VERSION ""

NS_ :

BS_:

BU_: CGM_HS TCM_HS RDCM_HS EPS_HS ECM_HS EBCM_HS BSM_HS BCM_HS

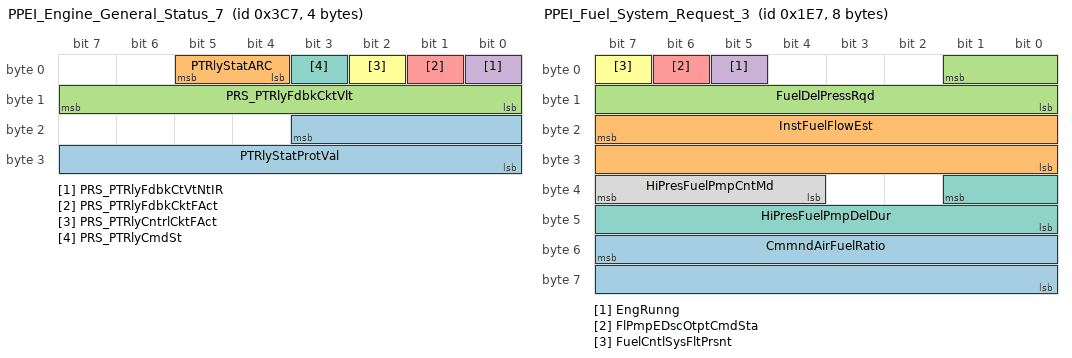
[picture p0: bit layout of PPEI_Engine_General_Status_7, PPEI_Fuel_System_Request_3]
BO_ 967 PPEI_Engine_General_Status_7: 4 ECM_HS
 SG_ PTRlyStatProtVal : 19|12@0+ (1,0) [0|4095] ""  CGM_HS
 SG_ PTRlyStatARC : 5|2@0+ (1,0) [0|3] ""  CGM_HS
 SG_ PRS_PTRlyFdbkCktVlt : 15|8@0+ (0.1,0) [0|25.5] "V"  CGM_HS
 SG_ PRS_PTRlyFdbkCtVtNtIR : 0|1@0+ (1,0) [0|1] ""  CGM_HS
 SG_ PRS_PTRlyFdbkCktFAct : 1|1@0+ (1,0) [0|1] ""  CGM_HS
 SG_ PRS_PTRlyCntrlCktFAct : 2|1@0+ (1,0) [0|1] ""  CGM_HS
 SG_ PRS_PTRlyCmdSt : 3|1@0+ (1,0) [0|1] ""  CGM_HS

BO_ 487 PPEI_Fuel_System_Request_3: 8 ECM_HS
 SG_ CmmndAirFuelRatio : 55|16@0+ (0.000488281,0) [0|31.999495335] ""  CGM_HS
 SG_ InstFuelFlowEst : 23|16@0+ (0.000976562,0) [0|63.99899067] "grams/s"  CGM_HS
 SG_ FuelDelPressRqd : 1|10@0+ (1,0) [0|1023] "kPa"  CGM_HS
 SG_ EngRunng : 5|1@0+ (1,0) [0|1] "" Vector__XXX
 SG_ FlPmpEDscOtptCmdSta : 6|1@0+ (1,0) [0|1] ""  CGM_HS
 SG_ FuelCntlSysFltPrsnt : 7|1@0+ (1,0) [0|1] ""  CGM_HS
 SG_ HiPresFuelPmpDelDur : 33|10@0+ (1,0) [0|1023] "deg"  CGM_HS
 SG_ HiPresFuelPmpCntMd : 39|4@0+ (1,0) [0|15] ""  CGM_HS

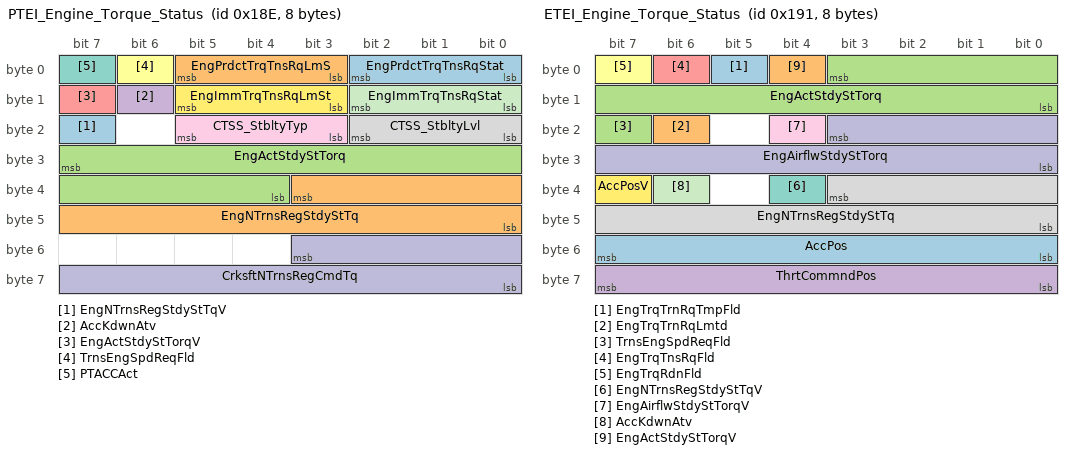
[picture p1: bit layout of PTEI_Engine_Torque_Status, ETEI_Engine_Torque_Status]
BO_ 398 PTEI_Engine_Torque_Status: 8 ECM_HS
 SG_ EngNTrnsRegStdyStTqV : 23|1@0+ (1,0) [0|1] ""  CGM_HS,TCM_HS
 SG_ EngNTrnsRegStdyStTq : 35|12@0+ (0.5,-848) [-848|1199.5] "Nm"  CGM_HS,TCM_HS
 SG_ EngActStdyStTorq : 31|12@0+ (0.5,-848) [-848|1199.5] "Nm"  CGM_HS,TCM_HS
 SG_ AccKdwnAtv : 14|1@0+ (1,0) [0|1] ""  CGM_HS,TCM_HS
 SG_ EngActStdyStTorqV : 15|1@0+ (1,0) [0|1] ""  CGM_HS,TCM_HS
 SG_ TrnsEngSpdReqFld : 6|1@0+ (1,0) [0|1] ""  CGM_HS,TCM_HS
 SG_ PTACCAct : 7|1@0+ (1,0) [0|1] ""  CGM_HS,TCM_HS
 SG_ CTSS_StbltyLvl : 18|3@0+ (1,0) [0|7] ""  CGM_HS,TCM_HS
 SG_ CTSS_StbltyTyp : 21|3@0+ (1,0) [0|7] ""  CGM_HS,TCM_HS
 SG_ CrksftNTrnsRegCmdTq : 51|12@0+ (0.5,-848) [-848|1199.5] "Nm"  CGM_HS,TCM_HS
 SG_ EngImmTrqTnsRqStat : 10|3@0+ (1,0) [0|7] ""  CGM_HS,TCM_HS
 SG_ EngImmTrqTnsRqLmSt : 13|3@0+ (1,0) [0|7] ""  CGM_HS,TCM_HS
 SG_ EngPrdctTrqTnsRqStat : 2|3@0+ (1,0) [0|7] ""  CGM_HS,TCM_HS
 SG_ EngPrdctTrqTnsRqLmS : 5|3@0+ (1,0) [0|7] ""  CGM_HS,TCM_HS

BO_ 1267 PPEI_Powertrain_Config_Data_2: 1 ECM_HS
 SG_ VehMassNom : 7|8@0+ (20,500) [500|5600] "kg"  CGM_HS

BO_ 1906 DTC_Triggered_772: 7 ECM_HS
 SG_ DTCI_DTCFaultType_772 : 55|8@0+ (1,0) [0|255] ""  CGM_HS
 SG_ DTCI_CodeSupported_772 : 40|1@0+ (1,0) [0|1] ""  CGM_HS
 SG_ DTCI_CurrentStatus_772 : 41|1@0+ (1,0) [0|1] ""  CGM_HS
 SG_ DTCI_TstNPsdCdClrdSt_772 : 42|1@0+ (1,0) [0|1] ""  CGM_HS
 SG_ DTCI_TstFldCdClrdStat_772 : 43|1@0+ (1,0) [0|1] ""  CGM_HS
 SG_ DTCI_HistStat_772 : 44|1@0+ (1,0) [0|1] ""  CGM_HS
 SG_ DTCI_TstNPsdPwrUpSt_772 : 45|1@0+ (1,0) [0|1] ""  CGM_HS
 SG_ DTCI_TstFldPwrUpSt_772 : 46|1@0+ (1,0) [0|1] ""  CGM_HS
 SG_ DTCI_WrnIndRqdSt_772 : 47|1@0+ (1,0) [0|1] ""  CGM_HS
 SG_ DTCI_DTCFailType_772 : 39|8@0+ (1,0) [0|255] ""  CGM_HS
 SG_ DTCI_DTCNumber_772 : 23|16@0+ (1,0) [0|65535] ""  CGM_HS
 SG_ DTCI_DTCSource_772 : 15|8@0+ (1,0) [0|255] ""  CGM_HS
 SG_ DTCI_DTCTriggered_772 : 0|1@0+ (1,0) [0|1] ""  CGM_HS
 SG_ DTCIUnused7_772 : 1|1@0+ (1,0) [0|1] ""  CGM_HS
 SG_ DTCIUnused6_772 : 2|1@0+ (1,0) [0|1] ""  CGM_HS
 SG_ DTCIUnused5_772 : 3|1@0+ (1,0) [0|1] ""  CGM_HS
 SG_ DTCIUnused4_772 : 4|1@0+ (1,0) [0|1] ""  CGM_HS
 SG_ DTCIUnused3_772 : 5|1@0+ (1,0) [0|1] ""  CGM_HS
 SG_ DTCIUnused2_772 : 6|1@0+ (1,0) [0|1] ""  CGM_HS
 SG_ DTCIUnused1_772 : 7|1@0+ (1,0) [0|1] ""  CGM_HS

BO_ 401 ETEI_Engine_Torque_Status: 8 ECM_HS
 SG_ EngTrqTrnRqTmpFld : 5|1@0+ (1,0) [0|1] ""  CGM_HS,TCM_HS
 SG_ EngTrqTrnRqLmtd : 22|1@0+ (1,0) [0|1] ""  CGM_HS,TCM_HS
 SG_ TrnsEngSpdReqFld : 23|1@0+ (1,0) [0|1] ""  CGM_HS,TCM_HS
 SG_ ThrtCommndPos : 63|8@0+ (0.392157,0) [0|100.000035] "%"  CGM_HS
 SG_ EngTrqTnsRqFld : 6|1@0+ (1,0) [0|1] ""  CGM_HS,TCM_HS
 SG_ EngTrqRdnFld : 7|1@0+ (1,0) [0|1] ""  CGM_HS,TCM_HS
 SG_ EngNTrnsRegStdyStTqV : 36|1@0+ (1,0) [0|1] ""  CGM_HS,TCM_HS
 SG_ EngNTrnsRegStdyStTq : 35|12@0+ (0.5,-848) [-848|1199.5] "Nm"  CGM_HS,TCM_HS
 SG_ EngAirflwStdyStTorqV : 20|1@0+ (1,0) [0|1] ""  CGM_HS,TCM_HS
 SG_ EngAirflwStdyStTorq : 19|12@0+ (0.5,-848) [-848|1199.5] "Nm"  CGM_HS,TCM_HS
 SG_ AccKdwnAtv : 38|1@0+ (1,0) [0|1] ""  CGM_HS,TCM_HS
 SG_ AccPosV : 39|1@0+ (1,0) [0|1] ""  CGM_HS,TCM_HS
 SG_ AccPos : 55|8@0+ (0.392157,0) [0|100.000035] "%"  TCM_HS
 SG_ EngActStdyStTorqV : 4|1@0+ (1,0) [0|1] ""  CGM_HS,TCM_HS
 SG_ EngActStdyStTorq : 3|12@0+ (0.5,-848) [-848|1199.5] "Nm"  CGM_HS,TCM_HS

BO_ 2024 USDT_Resp_From_ECM_HS: 8 ECM_HS
 SG_ DgnInf : 7|64@0+ (1,0) [0|1.84467440737096E+019] ""  CGM_HS

BO_ 1512 UUDT_Resp_From_ECM: 8 ECM_HS
 SG_ DgnInf : 7|64@0+ (1,0) [0|1.84467440737096E+019] ""  CGM_HS

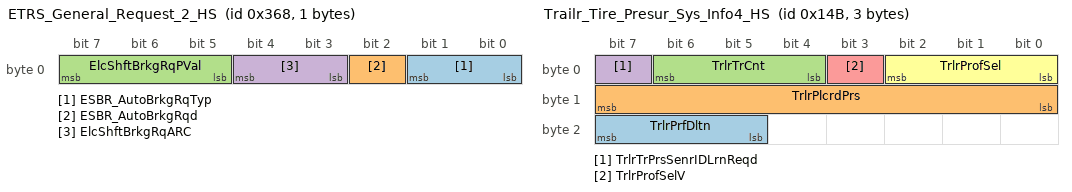
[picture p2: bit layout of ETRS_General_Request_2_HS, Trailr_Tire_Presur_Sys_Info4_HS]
BO_ 872 ETRS_General_Request_2_HS: 1 ECM_HS
 SG_ ESBR_AutoBrkgRqTyp : 1|2@0+ (1,0) [0|3] ""  CGM_HS,EBCM_HS
 SG_ ESBR_AutoBrkgRqd : 2|1@0+ (1,0) [0|1] ""  CGM_HS,EBCM_HS
 SG_ ElcShftBrkgRqPVal : 7|3@0+ (1,0) [0|7] ""  CGM_HS,EBCM_HS
 SG_ ElcShftBrkgRqARC : 4|2@0+ (1,0) [0|3] ""  CGM_HS,EBCM_HS

BO_ 331 Trailr_Tire_Presur_Sys_Info4_HS: 3 CGM_HS
 SG_ TrlrPrfDltn : 23|3@0+ (1,0) [0|7] "" Vector__XXX
 SG_ TrlrPlcrdPrs : 15|8@0+ (4,0) [0|1020] "kPaG" Vector__XXX
 SG_ TrlrTrCnt : 6|3@0+ (1,0) [0|7] "count" Vector__XXX
 SG_ TrlrTrPrsSenrIDLrnReqd : 7|1@0+ (1,0) [0|1] "" Vector__XXX
 SG_ TrlrProfSelV : 3|1@0+ (1,0) [0|1] ""  EBCM_HS
 SG_ TrlrProfSel : 2|3@0+ (1,0) [0|7] ""  EBCM_HS

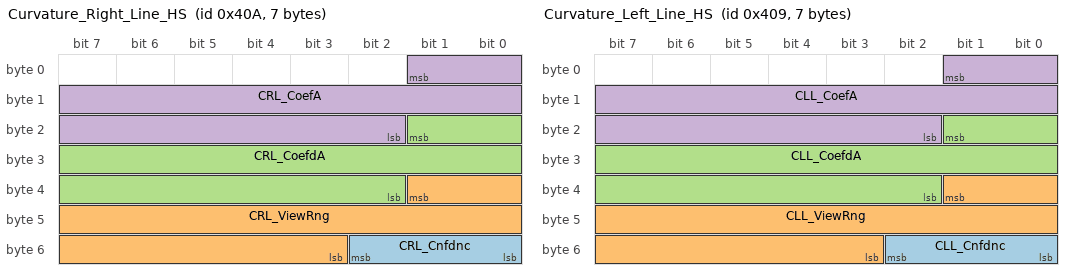
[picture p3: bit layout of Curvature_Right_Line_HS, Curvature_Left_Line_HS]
BO_ 1034 Curvature_Right_Line_HS: 7 CGM_HS
 SG_ CRL_Cnfdnc : 50|3@0+ (1,0) [0|7] ""  EBCM_HS
 SG_ CRL_ViewRng : 33|15@0+ (0.0039064,0) [0|128.0010088] "m"  EBCM_HS
 SG_ CRL_CoefdA : 17|16@0- (3.6622E-009,0) [-0.0001200029696|0.0001199993074] "1/m^2"  EBCM_HS
 SG_ CRL_CoefA : 1|16@0- (6.1036E-007,0) [-0.02000027648|0.01999966612] "1/m"  EBCM_HS

BO_ 1033 Curvature_Left_Line_HS: 7 CGM_HS
 SG_ CLL_Cnfdnc : 50|3@0+ (1,0) [0|7] ""  EBCM_HS
 SG_ CLL_ViewRng : 33|15@0+ (0.0039064,0) [0|128.0010088] "m"  EBCM_HS
 SG_ CLL_CoefdA : 17|16@0- (3.6622E-009,0) [-0.0001200029696|0.0001199993074] "1/m^2"  EBCM_HS
 SG_ CLL_CoefA : 1|16@0- (6.1036E-007,0) [-0.02000027648|0.01999966612] "1/m"  EBCM_HS

BO_ 1013 PPEI_Trans_General_Status_4_HS: 6 TCM_HS
 SG_ TrnRqHRBkCtlTgtVSpd : 1|2@0+ (1,0) [0|3] ""  CGM_HS,EBCM_HS
 SG_ TransReqHSAAval : 3|2@0+ (1,0) [0|3] ""  CGM_HS,EBCM_HS
 SG_ MtrBCoolFlwCmd : 39|8@0+ (0.05,0) [0|12.75] "l/min"  CGM_HS,TCM_HS
 SG_ MtrACoolFlwCmd : 31|8@0+ (0.05,0) [0|12.75] "l/min"  CGM_HS,TCM_HS
 SG_ ActrProcIntgSftyPtrn : 43|4@0+ (1,0) [0|15] ""  CGM_HS,ECM_HS
 SG_ TrnsRngDiagLmtdPVal : 19|4@0+ (1,0) [0|15] ""  CGM_HS,ECM_HS
 SG_ TrnsRngDiagLmtdFltARC : 7|2@0+ (1,0) [0|3] ""  CGM_HS,ECM_HS
 SG_ TRDLF_TrnsFwDrvRDLFlt : 20|1@0+ (1,0) [0|1] ""  CGM_HS,ECM_HS
 SG_ TRDLF_TrnsNtRgDgLtFlt : 21|1@0+ (1,0) [0|1] ""  CGM_HS,ECM_HS
 SG_ TRDLF_TrnsRvRgDgLtFlt : 22|1@0+ (1,0) [0|1] ""  CGM_HS,ECM_HS
 SG_ TRDLF_TrnsPkRgDgLtFlt : 23|1@0+ (1,0) [0|1] ""  CGM_HS,ECM_HS
 SG_ TrnsRngDiagCrtFltPVal : 11|4@0+ (1,0) [0|15] ""  CGM_HS,ECM_HS
 SG_ TrnsRngDiagCrtFltARC : 5|2@0+ (1,0) [0|3] ""  CGM_HS,ECM_HS
 SG_ TRDCF_TrnsFwDrvRDCFlt : 12|1@0+ (1,0) [0|1] ""  CGM_HS,ECM_HS
 SG_ TRDCF_TrnsNtRgDgCtFlt : 13|1@0+ (1,0) [0|1] ""  CGM_HS,ECM_HS
 SG_ TRDCF_TrnsRvRgDgCtFlt : 14|1@0+ (1,0) [0|1] ""  CGM_HS,ECM_HS
 SG_ TRDCF_TrnsPkRgDgCtFlt : 15|1@0+ (1,0) [0|1] ""  CGM_HS,ECM_HS

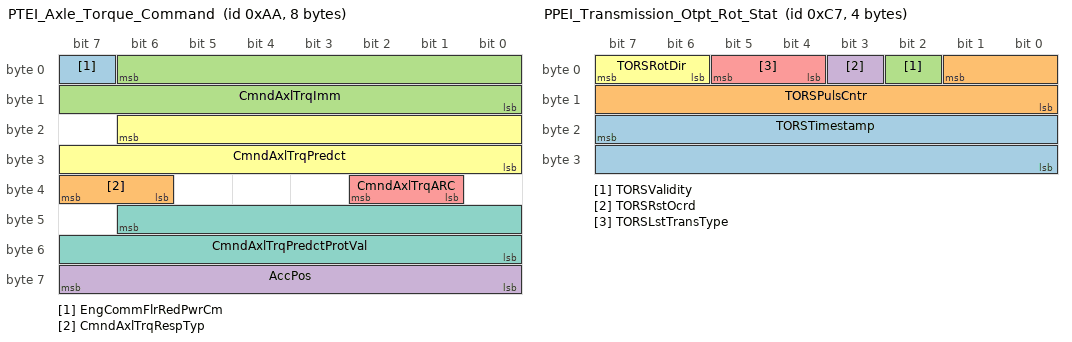
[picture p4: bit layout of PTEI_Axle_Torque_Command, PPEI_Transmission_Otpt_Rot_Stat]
BO_ 170 PTEI_Axle_Torque_Command: 8 ECM_HS
 SG_ EngCommFlrRedPwrCm : 7|1@0+ (1,0) [0|1] ""  CGM_HS
 SG_ CmndAxlTrqRespTyp : 39|2@0+ (1,0) [0|3] ""  CGM_HS
 SG_ CmndAxlTrqImm : 6|15@0+ (2,-22534) [-22534|43000] "Nm"  CGM_HS
 SG_ AccPos : 63|8@0+ (0.392157,0) [0|100.000035] "%"  TCM_HS
 SG_ CmndAxlTrqARC : 34|2@0+ (1,0) [0|3] ""  CGM_HS,EBCM_HS
 SG_ CmndAxlTrqPredct : 22|15@0+ (2,-22534) [-22534|43000] "Nm"  CGM_HS,EBCM_HS
 SG_ CmndAxlTrqPredctProtVal : 46|15@0+ (1,0) [0|32767] ""  CGM_HS,EBCM_HS

BO_ 647 PTEI_Transfer_Case_Supplemental: 6 ECM_HS
 SG_ DrvTrkModeCmnd : 23|1@0+ (1,0) [0|1] ""  TCM_HS,CGM_HS
 SG_ DrvCrwlModeCmnd : 31|1@0+ (1,0) [0|1] ""  TCM_HS,CGM_HS
 SG_ EngCntDtIntRSnsPsWdtV : 29|1@0+ (1,0) [0|1] ""  TCM_HS,CGM_HS
 SG_ CrnksftTqModRspMxCapV : 28|1@0+ (1,0) [0|1] ""  TCM_HS,CGM_HS
 SG_ CrnksftTqModRspMxCap : 27|12@0+ (0.5,-848) [-848|1199.5] "Nm"  TCM_HS,CGM_HS
 SG_ EngDetPndTrnCsRngShfV : 21|1@0+ (1,0) [0|1] ""  TCM_HS,CGM_HS
 SG_ EngDetPndTrnCsRngShf : 20|2@0+ (1,0) [0|3] ""  TCM_HS,CGM_HS
 SG_ EngCntDtIntRSnsPsWdt : 47|8@0+ (0.392157,0) [0|100.000035] "%"  TCM_HS,CGM_HS
 SG_ CrpCstCrvCmd : 18|3@0+ (1,0) [0|7] ""  TCM_HS,CGM_HS
 SG_ DrvMntnMdCmnd : 11|1@0+ (1,0) [0|1] ""  CGM_HS
 SG_ DrvHldMdCmnd : 12|1@0+ (1,0) [0|1] ""  CGM_HS
 SG_ DrPTGrdBrkDsbMdCmd : 22|1@0+ (1,0) [0|1] ""  TCM_HS,CGM_HS
 SG_ DrvWntrMdCmd : 13|1@0+ (1,0) [0|1] ""  TCM_HS,CGM_HS
 SG_ DrvTwHaulMdCmd : 14|1@0+ (1,0) [0|1] ""  TCM_HS,CGM_HS
 SG_ DrvSprtMdCmd : 15|1@0+ (1,0) [0|1] ""  TCM_HS,CGM_HS
 SG_ DrvEconMdCmd : 5|1@0+ (1,0) [0|1] ""  TCM_HS,CGM_HS
 SG_ EngCntrlDtrmdTrfCRngV : 10|1@0+ (1,0) [0|1] ""  TCM_HS,CGM_HS
 SG_ EngCntrlDtrmdTrfCRng : 9|2@0+ (1,0) [0|3] ""  TCM_HS,CGM_HS
 SG_ EngCtrlUtldTrnCRgPVal : 1|2@0+ (1,0) [0|3] ""  EBCM_HS,CGM_HS
 SG_ EngCntrlUtldTrnCsRng : 3|2@0+ (1,0) [0|3] ""  EBCM_HS,CGM_HS
 SG_ EngCntrlUtldTrnCsRgIn : 4|1@0+ (1,0) [0|1] ""  EBCM_HS,CGM_HS
 SG_ EngCtrlUtldTrnCRgARC : 7|2@0+ (1,0) [0|3] ""  EBCM_HS,CGM_HS

BO_ 199 PPEI_Transmission_Otpt_Rot_Stat: 4 TCM_HS
 SG_ TORSTimestamp : 23|16@0+ (1,0) [0|65535] "counts"  CGM_HS,ECM_HS,EBCM_HS
 SG_ TORSPulsCntr : 1|10@0+ (1,0) [0|1023] "counts"  CGM_HS,ECM_HS,EBCM_HS
 SG_ TORSValidity : 2|1@0+ (1,0) [0|1] ""  CGM_HS,ECM_HS,EBCM_HS
 SG_ TORSRstOcrd : 3|1@0+ (1,0) [0|1] ""  CGM_HS,ECM_HS,EBCM_HS
 SG_ TORSLstTransType : 5|2@0+ (1,0) [0|3] ""  CGM_HS,ECM_HS,EBCM_HS
 SG_ TORSRotDir : 7|2@0+ (1,0) [0|3] ""  CGM_HS,ECM_HS,EBCM_HS

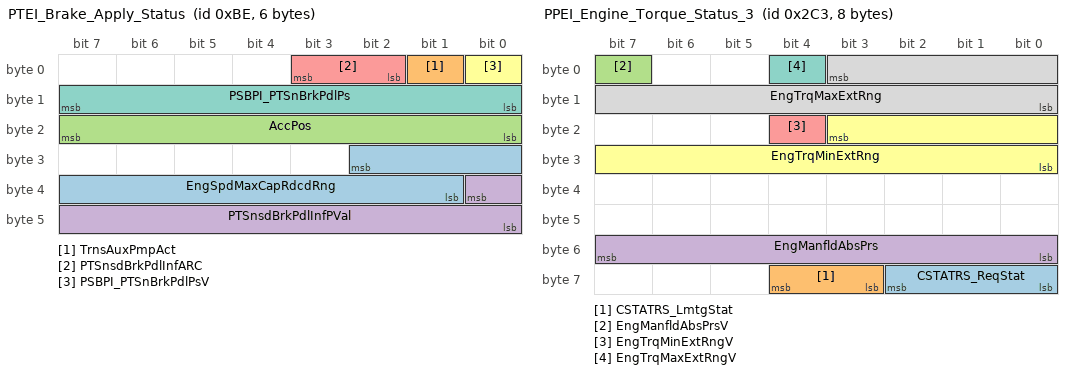
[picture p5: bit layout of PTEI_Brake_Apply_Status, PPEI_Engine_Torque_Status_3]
BO_ 190 PTEI_Brake_Apply_Status: 6 ECM_HS
 SG_ EngSpdMaxCapRdcdRng : 26|10@0+ (8,0) [0|8184] "rpm"  CGM_HS,TCM_HS
 SG_ TrnsAuxPmpAct : 1|1@0+ (1,0) [0|1] ""  CGM_HS,TCM_HS
 SG_ AccPos : 23|8@0+ (0.392157,0) [0|100.000035] "%"  CGM_HS,TCM_HS
 SG_ PTSnsdBrkPdlInfPVal : 32|9@0+ (1,0) [0|511] ""  CGM_HS,EBCM_HS
 SG_ PTSnsdBrkPdlInfARC : 3|2@0+ (1,0) [0|3] ""  CGM_HS,EBCM_HS
 SG_ PSBPI_PTSnBrkPdlPsV : 0|1@0+ (1,0) [0|1] ""  CGM_HS,TCM_HS,EBCM_HS
 SG_ PSBPI_PTSnBrkPdlPs : 15|8@0+ (0.392157,0) [0|100.000035] "%"  CGM_HS,TCM_HS,EBCM_HS

BO_ 579 USDT_Req_to_EBCM_HPCC_HS: 8 CGM_HS
 SG_ DgnInf : 7|64@0+ (1,0) [0|1.84467440737096E+019] ""  EBCM_HS

BO_ 707 PPEI_Engine_Torque_Status_3: 8 ECM_HS
 SG_ CSTATRS_ReqStat : 58|3@0+ (1,0) [0|7] ""  CGM_HS,EBCM_HS
 SG_ CSTATRS_LmtgStat : 60|2@0+ (1,0) [0|3] ""  CGM_HS,EBCM_HS
 SG_ EngManfldAbsPrsV : 7|1@0+ (1,0) [0|1] ""  CGM_HS,EBCM_HS
 SG_ EngManfldAbsPrs : 55|8@0+ (0.5,0) [0|127.5] "kPa"  CGM_HS,EBCM_HS
 SG_ EngTrqMinExtRngV : 20|1@0+ (1,0) [0|1] ""  CGM_HS,EBCM_HS
 SG_ EngTrqMinExtRng : 19|12@0+ (0.5,-848) [-848|1199.5] "Nm"  CGM_HS,EBCM_HS
 SG_ EngTrqMaxExtRngV : 4|1@0+ (1,0) [0|1] ""  CGM_HS,RDCM_HS,EBCM_HS
 SG_ EngTrqMaxExtRng : 3|12@0+ (0.5,-848) [-848|1199.5] "Nm"  CGM_HS,RDCM_HS,EBCM_HS

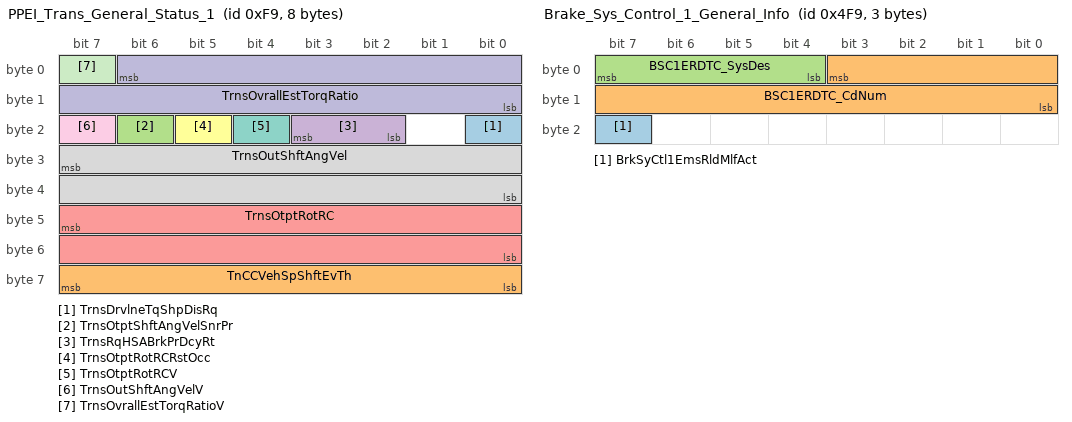
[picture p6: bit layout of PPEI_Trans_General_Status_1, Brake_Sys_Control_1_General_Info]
BO_ 249 PPEI_Trans_General_Status_1: 8 TCM_HS
 SG_ TrnsDrvlneTqShpDisRq : 16|1@0+ (1,0) [0|1] ""  CGM_HS,ECM_HS
 SG_ TnCCVehSpShftEvTh : 63|8@0+ (2,0) [0|510] "km / h"  CGM_HS,ECM_HS
 SG_ TrnsOtptShftAngVelSnrPr : 22|1@0+ (1,0) [0|1] ""  CGM_HS,ECM_HS
 SG_ TrnsRqHSABrkPrDcyRt : 19|2@0+ (1,0) [0|3] ""  CGM_HS,EBCM_HS
 SG_ TrnsOtptRotRC : 47|16@0+ (0.0078125,0) [0|511.9921875] "rot"  CGM_HS,ECM_HS,EBCM_HS
 SG_ TrnsOtptRotRCRstOcc : 21|1@0+ (1,0) [0|1] ""  CGM_HS,ECM_HS,EBCM_HS
 SG_ TrnsOtptRotRCV : 20|1@0+ (1,0) [0|1] ""  CGM_HS,ECM_HS,EBCM_HS
 SG_ TrnsOutShftAngVel : 31|16@0+ (0.25,0) [0|16383.75] "rpm"  CGM_HS,ECM_HS,EBCM_HS
 SG_ TrnsOutShftAngVelV : 23|1@0+ (1,0) [0|1] ""  CGM_HS,ECM_HS,EBCM_HS
 SG_ TrnsOvrallEstTorqRatio : 6|15@0- (0.00390625,0) [-64|63.99609375] ""  CGM_HS,RDCM_HS,ECM_HS,EBCM_HS
 SG_ TrnsOvrallEstTorqRatioV : 7|1@0+ (1,0) [0|1] ""  CGM_HS,RDCM_HS,ECM_HS,EBCM_HS

BO_ 1273 Brake_Sys_Control_1_General_Info: 3 EBCM_HS
 SG_ BrkSyCtl1EmsRldMlfAct : 23|1@0+ (1,0) [0|1] ""  CGM_HS,ECM_HS
 SG_ BSC1ERDTC_CdNum : 3|12@0+ (1,0) [0|4095] ""  CGM_HS,ECM_HS
 SG_ BSC1ERDTC_SysDes : 7|4@0+ (1,0) [0|15] ""  CGM_HS,ECM_HS

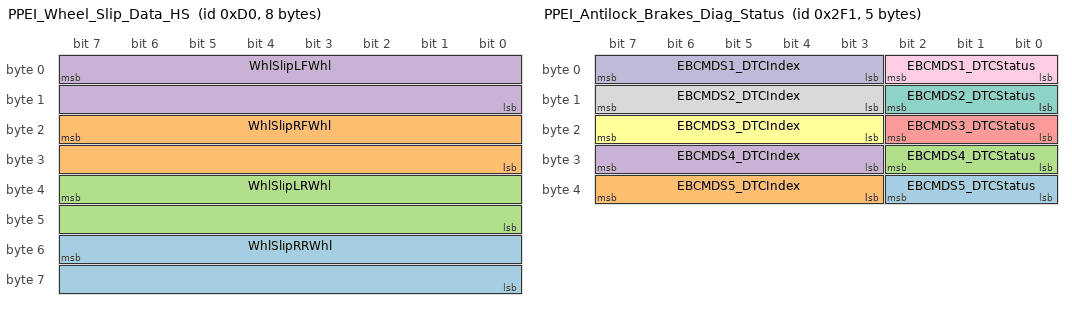
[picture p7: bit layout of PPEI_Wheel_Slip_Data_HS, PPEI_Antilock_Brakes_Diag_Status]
BO_ 208 PPEI_Wheel_Slip_Data_HS: 8 EBCM_HS
 SG_ WhlSlipRRWhl : 55|16@0+ (0.390625,-12800) [-12800|12799.609375] "%"  CGM_HS,TCM_HS
 SG_ WhlSlipRFWhl : 23|16@0+ (0.390625,-12800) [-12800|12799.609375] "%"  CGM_HS,TCM_HS
 SG_ WhlSlipLRWhl : 39|16@0+ (0.390625,-12800) [-12800|12799.609375] "%"  CGM_HS,TCM_HS
 SG_ WhlSlipLFWhl : 7|16@0+ (0.390625,-12800) [-12800|12799.609375] "%"  CGM_HS,TCM_HS

BO_ 753 PPEI_Antilock_Brakes_Diag_Status: 5 EBCM_HS
 SG_ EBCMDS5_DTCStatus : 34|3@0+ (1,0) [0|7] ""  CGM_HS,ECM_HS
 SG_ EBCMDS5_DTCIndex : 39|5@0+ (1,0) [0|31] ""  CGM_HS,ECM_HS
 SG_ EBCMDS4_DTCStatus : 26|3@0+ (1,0) [0|7] ""  CGM_HS,ECM_HS
 SG_ EBCMDS4_DTCIndex : 31|5@0+ (1,0) [0|31] ""  CGM_HS,ECM_HS
 SG_ EBCMDS3_DTCStatus : 18|3@0+ (1,0) [0|7] ""  CGM_HS,ECM_HS
 SG_ EBCMDS3_DTCIndex : 23|5@0+ (1,0) [0|31] ""  CGM_HS,ECM_HS
 SG_ EBCMDS2_DTCStatus : 10|3@0+ (1,0) [0|7] ""  CGM_HS,ECM_HS
 SG_ EBCMDS2_DTCIndex : 15|5@0+ (1,0) [0|31] ""  CGM_HS,ECM_HS
 SG_ EBCMDS1_DTCStatus : 2|3@0+ (1,0) [0|7] ""  CGM_HS,ECM_HS
 SG_ EBCMDS1_DTCIndex : 7|5@0+ (1,0) [0|31] ""  CGM_HS,ECM_HS

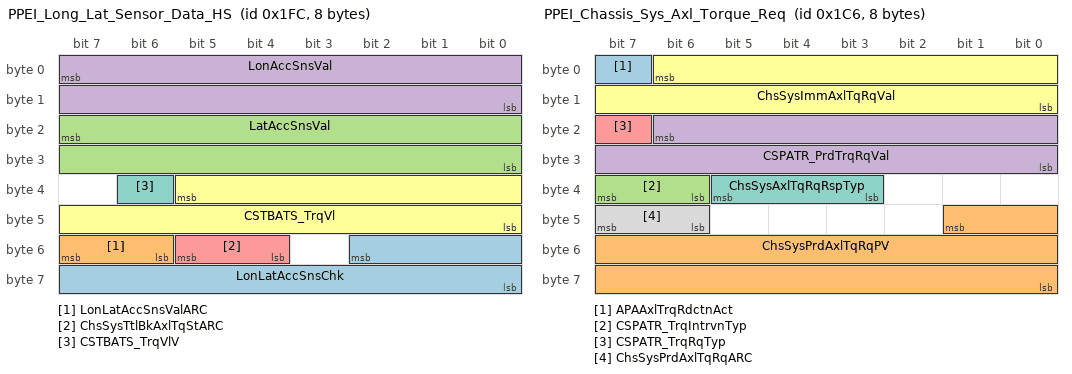
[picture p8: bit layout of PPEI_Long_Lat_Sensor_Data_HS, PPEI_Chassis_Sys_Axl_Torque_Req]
BO_ 508 PPEI_Long_Lat_Sensor_Data_HS: 8 EBCM_HS
 SG_ LonLatAccSnsChk : 50|11@0+ (1,0) [0|2047] ""  CGM_HS,TCM_HS,ECM_HS
 SG_ LonLatAccSnsValARC : 55|2@0+ (1,0) [0|3] ""  CGM_HS,TCM_HS,ECM_HS
 SG_ LatAccSnsVal : 23|16@0- (0.00012207,0) [-3.99998976|3.99986769] "g's"  TCM_HS,ECM_HS,CGM_HS
 SG_ LonAccSnsVal : 7|16@0- (0.00012207,0) [-3.99998976|3.99986769] "g's"  TCM_HS,ECM_HS,CGM_HS
 SG_ ChsSysTtlBkAxlTqStARC : 53|2@0+ (1,0) [0|3] ""  ECM_HS,CGM_HS
 SG_ CSTBATS_TrqVl : 37|14@0+ (2,0) [0|32766] "Nm"  TCM_HS,ECM_HS,CGM_HS
 SG_ CSTBATS_TrqVlV : 38|1@0+ (1,0) [0|1] ""  TCM_HS,ECM_HS,CGM_HS

BO_ 454 PPEI_Chassis_Sys_Axl_Torque_Req: 8 EBCM_HS
 SG_ APAAxlTrqRdctnAct : 7|1@0+ (1,0) [0|1] ""  ECM_HS,CGM_HS
 SG_ ChsSysPrdAxlTqRqPV : 41|18@0+ (1,0) [0|262143] ""  ECM_HS,CGM_HS
 SG_ CSPATR_TrqIntrvnTyp : 39|2@0+ (1,0) [0|3] ""  ECM_HS,CGM_HS
 SG_ CSPATR_PrdTrqRqVal : 22|15@0+ (2,-22534) [-22534|43000] "Nm"  ECM_HS,CGM_HS
 SG_ CSPATR_TrqRqTyp : 23|1@0+ (1,0) [0|1] ""  ECM_HS,CGM_HS
 SG_ ChsSysImmAxlTqRqVal : 6|15@0+ (2,-22534) [-22534|43000] "Nm"  ECM_HS,CGM_HS
 SG_ ChsSysAxlTqRqRspTyp : 37|3@0+ (1,0) [0|7] ""  ECM_HS,CGM_HS
 SG_ ChsSysPrdAxlTqRqARC : 47|2@0+ (1,0) [0|3] ""  ECM_HS,CGM_HS

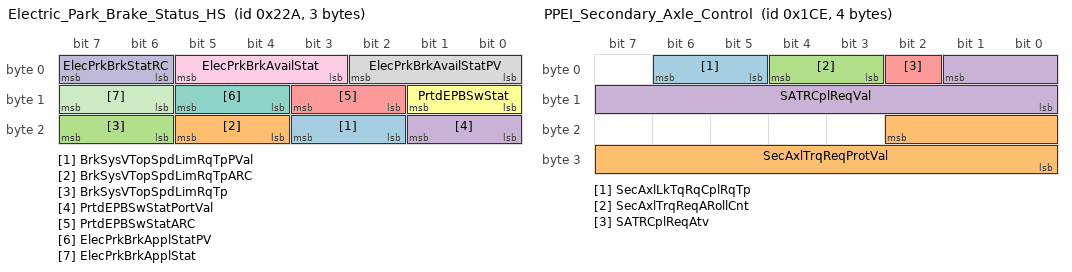
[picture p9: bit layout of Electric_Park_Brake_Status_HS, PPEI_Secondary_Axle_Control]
BO_ 554 Electric_Park_Brake_Status_HS: 3 EBCM_HS
 SG_ BrkSysVTopSpdLimRqTpPVal : 19|2@0+ (1,0) [0|3] ""  ECM_HS,CGM_HS
 SG_ BrkSysVTopSpdLimRqTpARC : 21|2@0+ (1,0) [0|3] ""  ECM_HS,CGM_HS
 SG_ BrkSysVTopSpdLimRqTp : 23|2@0+ (1,0) [0|3] ""  ECM_HS,CGM_HS
 SG_ PrtdEPBSwStatPortVal : 17|2@0+ (1,0) [0|3] "Counts"  CGM_HS
 SG_ PrtdEPBSwStatARC : 11|2@0+ (1,0) [0|3] "Counts"  CGM_HS
 SG_ PrtdEPBSwStat : 9|2@0+ (1,0) [0|3] ""  CGM_HS
 SG_ ElecPrkBrkApplStatPV : 13|2@0+ (1,0) [0|3] ""  ECM_HS,CGM_HS
 SG_ ElecPrkBrkAvailStatPV : 2|3@0+ (1,0) [0|7] ""  ECM_HS,CGM_HS
 SG_ ElecPrkBrkAvailStat : 5|3@0+ (1,0) [0|7] ""  TCM_HS,ECM_HS,CGM_HS
 SG_ ElecPrkBrkStatRC : 7|2@0+ (1,0) [0|3] ""  ECM_HS,CGM_HS
 SG_ ElecPrkBrkApplStat : 15|2@0+ (1,0) [0|3] ""  TCM_HS,ECM_HS,CGM_HS

BO_ 462 PPEI_Secondary_Axle_Control: 4 EBCM_HS
 SG_ SecAxlLkTqRqCplRqTp : 6|2@0+ (1,0) [0|3] ""  CGM_HS
 SG_ SecAxlTrqReqProtVal : 18|11@0+ (1,0) [0|2047] "Counts"  CGM_HS
 SG_ SecAxlTrqReqARollCnt : 4|2@0+ (1,0) [0|3] "Counts"  CGM_HS
 SG_ SATRCplReqVal : 1|10@0+ (10,0) [0|10230] "Nm"  CGM_HS
 SG_ SATRCplReqAtv : 2|1@0+ (1,0) [0|1] ""  CGM_HS

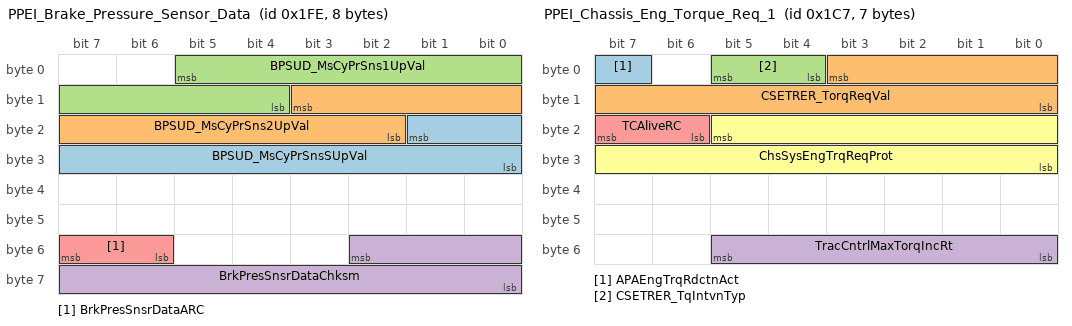
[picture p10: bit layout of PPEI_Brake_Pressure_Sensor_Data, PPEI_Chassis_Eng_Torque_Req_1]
BO_ 510 PPEI_Brake_Pressure_Sensor_Data: 8 EBCM_HS
 SG_ BPSUD_MsCyPrSnsSUpVal : 17|10@0+ (1,0) [0|1023] ""  CGM_HS
 SG_ BPSUD_MsCyPrSns2UpVal : 11|10@0+ (1,0) [0|1023] ""  CGM_HS
 SG_ BPSUD_MsCyPrSns1UpVal : 5|10@0+ (1,0) [0|1023] ""  CGM_HS
 SG_ BrkPresSnsrDataChksm : 50|11@0+ (1,0) [0|2047] ""  CGM_HS
 SG_ BrkPresSnsrDataARC : 55|2@0+ (1,0) [0|3] ""  CGM_HS

BO_ 1920 DTC_Triggered_780: 7 EBCM_HS
 SG_ DTCI_CurrentStatus_780 : 41|1@0+ (1,0) [0|1] ""  CGM_HS
 SG_ DTCI_WrnIndRqdSt_780 : 47|1@0+ (1,0) [0|1] ""  CGM_HS
 SG_ DTCIUnused7_780 : 1|1@0+ (1,0) [0|1] ""  CGM_HS
 SG_ DTCIUnused6_780 : 2|1@0+ (1,0) [0|1] ""  CGM_HS
 SG_ DTCIUnused5_780 : 3|1@0+ (1,0) [0|1] ""  CGM_HS
 SG_ DTCIUnused4_780 : 4|1@0+ (1,0) [0|1] ""  CGM_HS
 SG_ DTCIUnused3_780 : 5|1@0+ (1,0) [0|1] ""  CGM_HS
 SG_ DTCIUnused2_780 : 6|1@0+ (1,0) [0|1] ""  CGM_HS
 SG_ DTCIUnused1_780 : 7|1@0+ (1,0) [0|1] ""  CGM_HS
 SG_ DTCI_TstNPsdPwrUpSt_780 : 45|1@0+ (1,0) [0|1] ""  CGM_HS
 SG_ DTCI_TstNPsdCdClrdSt_780 : 42|1@0+ (1,0) [0|1] ""  CGM_HS
 SG_ DTCI_TstFldPwrUpSt_780 : 46|1@0+ (1,0) [0|1] ""  CGM_HS
 SG_ DTCI_TstFldCdClrdStat_780 : 43|1@0+ (1,0) [0|1] ""  CGM_HS
 SG_ DTCI_HistStat_780 : 44|1@0+ (1,0) [0|1] ""  CGM_HS
 SG_ DTCI_DTCTriggered_780 : 0|1@0+ (1,0) [0|1] ""  CGM_HS
 SG_ DTCI_DTCSource_780 : 15|8@0+ (1,0) [0|255] ""  CGM_HS
 SG_ DTCI_DTCNumber_780 : 23|16@0+ (1,0) [0|65535] ""  CGM_HS
 SG_ DTCI_DTCFaultType_780 : 55|8@0+ (1,0) [0|255] ""  CGM_HS
 SG_ DTCI_DTCFailType_780 : 39|8@0+ (1,0) [0|255] ""  CGM_HS
 SG_ DTCI_CodeSupported_780 : 40|1@0+ (1,0) [0|1] ""  CGM_HS

BO_ 1907 DTC_Triggered_773: 7 EBCM_HS
 SG_ DTCI_DTCFaultType_773 : 55|8@0+ (1,0) [0|255] ""  CGM_HS
 SG_ DTCI_CodeSupported_773 : 40|1@0+ (1,0) [0|1] ""  CGM_HS
 SG_ DTCI_CurrentStatus_773 : 41|1@0+ (1,0) [0|1] ""  CGM_HS
 SG_ DTCI_TstNPsdCdClrdSt_773 : 42|1@0+ (1,0) [0|1] ""  CGM_HS
 SG_ DTCI_TstFldCdClrdStat_773 : 43|1@0+ (1,0) [0|1] ""  CGM_HS
 SG_ DTCI_HistStat_773 : 44|1@0+ (1,0) [0|1] ""  CGM_HS
 SG_ DTCI_TstNPsdPwrUpSt_773 : 45|1@0+ (1,0) [0|1] ""  CGM_HS
 SG_ DTCI_TstFldPwrUpSt_773 : 46|1@0+ (1,0) [0|1] ""  CGM_HS
 SG_ DTCI_WrnIndRqdSt_773 : 47|1@0+ (1,0) [0|1] ""  CGM_HS
 SG_ DTCI_DTCFailType_773 : 39|8@0+ (1,0) [0|255] ""  CGM_HS
 SG_ DTCI_DTCNumber_773 : 23|16@0+ (1,0) [0|65535] ""  CGM_HS
 SG_ DTCI_DTCSource_773 : 15|8@0+ (1,0) [0|255] ""  CGM_HS
 SG_ DTCI_DTCTriggered_773 : 0|1@0+ (1,0) [0|1] ""  CGM_HS
 SG_ DTCIUnused7_773 : 1|1@0+ (1,0) [0|1] ""  CGM_HS
 SG_ DTCIUnused6_773 : 2|1@0+ (1,0) [0|1] ""  CGM_HS
 SG_ DTCIUnused5_773 : 3|1@0+ (1,0) [0|1] ""  CGM_HS
 SG_ DTCIUnused4_773 : 4|1@0+ (1,0) [0|1] ""  CGM_HS
 SG_ DTCIUnused3_773 : 5|1@0+ (1,0) [0|1] ""  CGM_HS
 SG_ DTCIUnused2_773 : 6|1@0+ (1,0) [0|1] ""  CGM_HS
 SG_ DTCIUnused1_773 : 7|1@0+ (1,0) [0|1] ""  CGM_HS

BO_ 1603 USDT_Resp_From_EBCM_HPCC_HS: 8 EBCM_HS
 SG_ DgnInf : 7|64@0+ (1,0) [0|1.84467440737096E+019] ""  CGM_HS

BO_ 1347 UUDT_Resp_From_EBCM_HPCC_HS: 8 EBCM_HS
 SG_ DgnInf_HS543 : 7|64@0+ (1,0) [0|1.84467440737096E+019] ""  CGM_HS

BO_ 455 PPEI_Chassis_Eng_Torque_Req_1: 7 EBCM_HS
 SG_ APAEngTrqRdctnAct : 7|1@0+ (1,0) [0|1] ""  CGM_HS,ECM_HS
 SG_ CSETRER_TorqReqVal : 3|12@0+ (0.5,-848) [-848|1199.5] "Nm"  CGM_HS,ECM_HS
 SG_ CSETRER_TqIntvnTyp : 5|2@0+ (1,0) [0|3] ""  CGM_HS,ECM_HS
 SG_ TracCntrlMaxTorqIncRt : 53|6@0+ (16,0) [0|1008] "Nm/s"  CGM_HS,ECM_HS
 SG_ TCAliveRC : 23|2@0+ (1,0) [0|3] ""  CGM_HS,ECM_HS
 SG_ ChsSysEngTrqReqProt : 21|14@0+ (1,0) [0|16383] ""  CGM_HS,ECM_HS

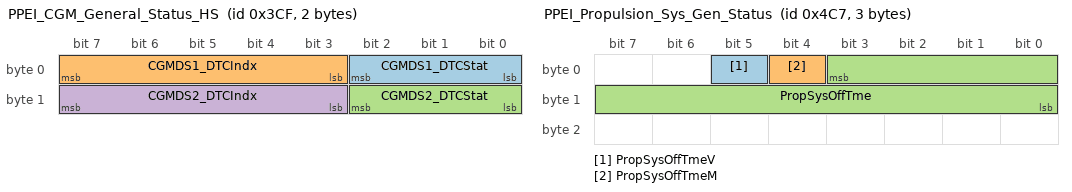
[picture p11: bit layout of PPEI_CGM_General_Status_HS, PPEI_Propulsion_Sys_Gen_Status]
BO_ 975 PPEI_CGM_General_Status_HS: 2 CGM_HS
 SG_ CGMDS1_DTCStat : 2|3@0+ (1,0) [0|7] ""  TCM_HS,EBCM_HS,ECM_HS,BSM_HS
 SG_ CGMDS1_DTCIndx : 7|5@0+ (1,0) [0|31] ""  TCM_HS,EBCM_HS,ECM_HS,BSM_HS
 SG_ CGMDS2_DTCStat : 10|3@0+ (1,0) [0|7] ""  ECM_HS
 SG_ CGMDS2_DTCIndx : 15|5@0+ (1,0) [0|31] ""  ECM_HS

BO_ 1223 PPEI_Propulsion_Sys_Gen_Status: 3 ECM_HS
 SG_ PropSysOffTmeV : 5|1@0+ (1,0) [0|1] ""  CGM_HS,TCM_HS,EBCM_HS,BSM_HS
 SG_ PropSysOffTmeM : 4|1@0+ (1,0) [0|1] ""  CGM_HS,TCM_HS,EBCM_HS,BSM_HS
 SG_ PropSysOffTme : 3|12@0+ (0.5,0) [0|2047.5] "min"  CGM_HS,TCM_HS,EBCM_HS,BSM_HS

BO_ 211 PPEI_Hybrid_General_Status_3_HS: 2 ECM_HS
 SG_ ActAxleTrqV : 7|1@0+ (1,0) [0|1] ""  CGM_HS,TCM_HS,EPS_HS,ECM_HS,EBCM_HS,BSM_HS
 SG_ ActAxleTrq : 6|15@0+ (2,-22534) [-22534|43000] "Nm"  CGM_HS,TCM_HS,EPS_HS,ECM_HS,EBCM_HS,BSM_HS

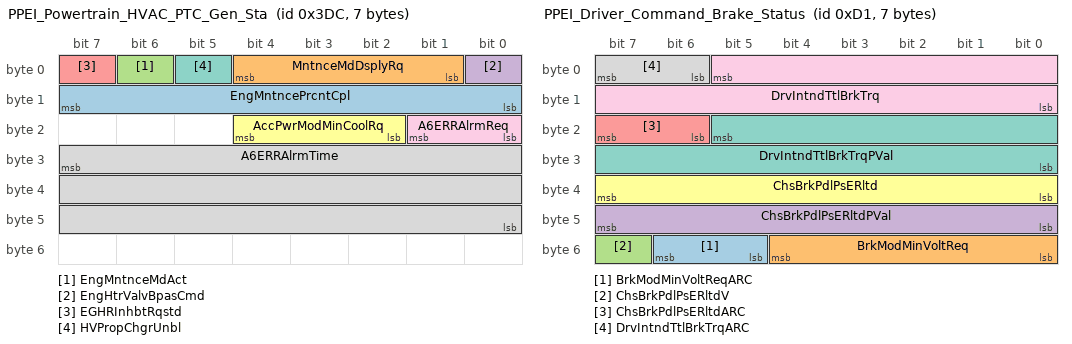
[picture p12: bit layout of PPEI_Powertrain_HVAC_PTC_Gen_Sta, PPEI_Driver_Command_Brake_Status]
BO_ 988 PPEI_Powertrain_HVAC_PTC_Gen_Sta: 7 ECM_HS
 SG_ EngMntncePrcntCpl : 15|8@0+ (0.392157,0) [0|100.000035] "%"  CGM_HS
 SG_ MntnceMdDsplyRq : 4|4@0+ (1,0) [0|15] ""  CGM_HS
 SG_ EngMntnceMdAct : 6|1@0+ (1,0) [0|1] ""  CGM_HS
 SG_ EngHtrValvBpasCmd : 0|1@0+ (1,0) [0|1] ""  CGM_HS
 SG_ EGHRInhbtRqstd : 7|1@0+ (1,0) [0|1] ""  CGM_HS,BSM_HS
 SG_ AccPwrModMinCoolRq : 20|3@0+ (1,0) [0|7] ""  CGM_HS,BSM_HS
 SG_ HVPropChgrUnbl : 5|1@0+ (1,0) [0|1] ""  CGM_HS,BSM_HS
 SG_ A6ERRAlrmTime : 31|24@0+ (1,0) [0|16777215] "min"  BSM_HS
 SG_ A6ERRAlrmReq : 17|2@0+ (1,0) [0|3] ""  BSM_HS

BO_ 209 PPEI_Driver_Command_Brake_Status: 7 EBCM_HS
 SG_ BrkModMinVoltReqARC : 54|2@0+ (1,0) [0|3] ""  ECM_HS,CGM_HS
 SG_ BrkModMinVoltReq : 52|5@0+ (0.625,0) [0|19.375] ""  ECM_HS,CGM_HS
 SG_ ChsBrkPdlPsERltdV : 55|1@0+ (1,0) [0|1] ""  ECM_HS,CGM_HS
 SG_ ChsBrkPdlPsERltdPVal : 47|8@0+ (1,0) [0|255] ""  ECM_HS,CGM_HS
 SG_ ChsBrkPdlPsERltdARC : 23|2@0+ (1,0) [0|3] ""  ECM_HS,CGM_HS
 SG_ ChsBrkPdlPsERltd : 39|8@0+ (0.392157,0) [0|100.000035] "%"  ECM_HS,CGM_HS
 SG_ DrvIntndTtlBrkTrqPVal : 21|14@0+ (1,0) [0|16383] ""  ECM_HS,CGM_HS
 SG_ DrvIntndTtlBrkTrqARC : 7|2@0+ (1,0) [0|3] ""  ECM_HS,CGM_HS
 SG_ DrvIntndTtlBrkTrq : 5|14@0+ (2,0) [0|32766] "Nm"  ECM_HS,CGM_HS,BSM_HS

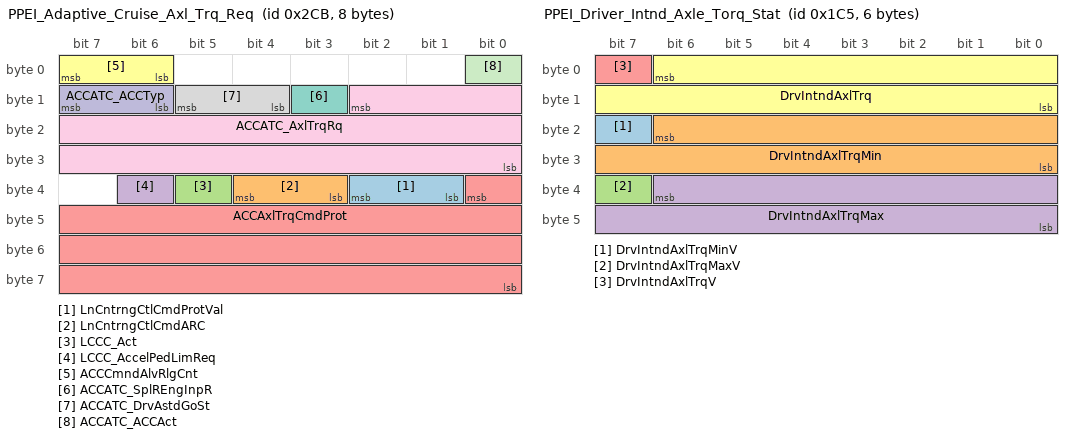
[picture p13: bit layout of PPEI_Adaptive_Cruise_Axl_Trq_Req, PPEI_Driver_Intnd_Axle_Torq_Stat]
BO_ 715 PPEI_Adaptive_Cruise_Axl_Trq_Req: 8 CGM_HS
 SG_ LnCntrngCtlCmdProtVal : 34|2@0+ (1,0) [0|3] ""  ECM_HS
 SG_ LnCntrngCtlCmdARC : 36|2@0+ (1,0) [0|3] ""  ECM_HS
 SG_ LCCC_Act : 37|1@0+ (1,0) [0|1] ""  ECM_HS
 SG_ LCCC_AccelPedLimReq : 38|1@0+ (1,0) [0|1] ""  ECM_HS
 SG_ ACCAxlTrqCmdProt : 32|25@0+ (1,0) [0|33554431] ""  ECM_HS
 SG_ ACCCmndAlvRlgCnt : 7|2@0+ (1,0) [0|3] ""  ECM_HS
 SG_ ACCATC_SplREngInpR : 11|1@0+ (1,0) [0|1] ""  ECM_HS,BSM_HS
 SG_ ACCATC_DrvAstdGoSt : 13|2@0+ (1,0) [0|3] ""  ECM_HS,BSM_HS
 SG_ ACCATC_AxlTrqRq : 10|19@0+ (0.125,-22534) [-22534|43001.875] "Nm"  ECM_HS,BSM_HS
 SG_ ACCATC_ACCTyp : 15|2@0+ (1,0) [0|3] ""  ECM_HS,BSM_HS
 SG_ ACCATC_ACCAct : 0|1@0+ (1,0) [0|1] ""  ECM_HS,BSM_HS

BO_ 453 PPEI_Driver_Intnd_Axle_Torq_Stat: 6 ECM_HS
 SG_ DrvIntndAxlTrqMinV : 23|1@0+ (1,0) [0|1] ""  CGM_HS
 SG_ DrvIntndAxlTrqMin : 22|15@0+ (2,-22534) [-22534|43000] "Nm"  CGM_HS
 SG_ DrvIntndAxlTrqMaxV : 39|1@0+ (1,0) [0|1] ""  CGM_HS
 SG_ DrvIntndAxlTrqMax : 38|15@0+ (2,-22534) [-22534|43000] "Nm"  CGM_HS
 SG_ DrvIntndAxlTrqV : 7|1@0+ (1,0) [0|1] ""  CGM_HS,EBCM_HS,BSM_HS
 SG_ DrvIntndAxlTrq : 6|15@0+ (2,-22534) [-22534|43000] "Nm"  CGM_HS,EBCM_HS,BSM_HS

BO_ 495 PPEI_Fuel_System_Request_2: 4 ECM_HS
 SG_ MassAirFloV : 7|1@0+ (1,0) [0|1] ""  CGM_HS,BSM_HS
 SG_ MassAirFlo : 23|16@0+ (0.01,0) [0|655.35] "grams/s"  CGM_HS,BSM_HS

BO_ 2020 USDT_Req_to_VICM_HS: 8 CGM_HS
 SG_ DgnInf : 7|64@0+ (1,0) [0|1.84467440737096E+019] ""  BSM_HS

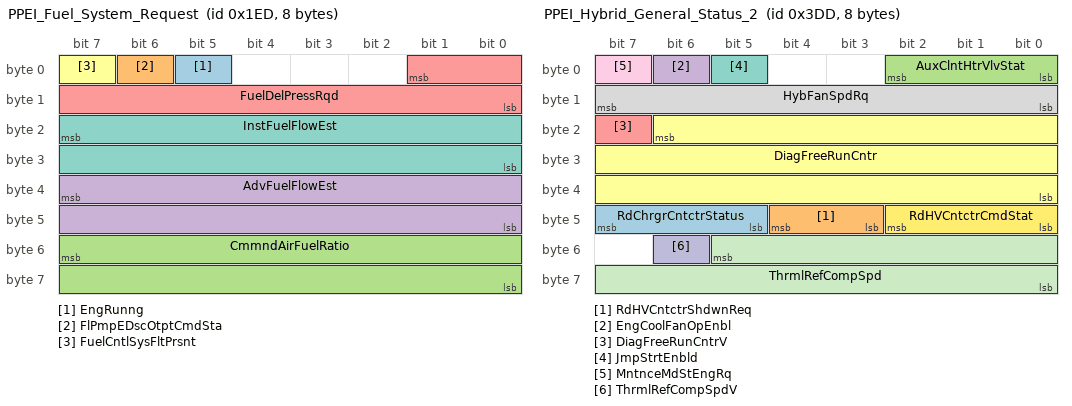
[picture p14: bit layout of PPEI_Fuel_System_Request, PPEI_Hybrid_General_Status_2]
BO_ 493 PPEI_Fuel_System_Request: 8 ECM_HS
 SG_ EngRunng : 5|1@0+ (1,0) [0|1] ""  CGM_HS
 SG_ FlPmpEDscOtptCmdSta : 6|1@0+ (1,0) [0|1] ""  CGM_HS
 SG_ CmmndAirFuelRatio : 55|16@0+ (0.000488281,0) [0|31.999495335] ""  CGM_HS
 SG_ AdvFuelFlowEst : 39|16@0+ (0.000976562,0) [0|63.99899067] "grams/s"  CGM_HS
 SG_ FuelDelPressRqd : 1|10@0+ (1,0) [0|1023] "kPa"  CGM_HS
 SG_ FuelCntlSysFltPrsnt : 7|1@0+ (1,0) [0|1] ""  CGM_HS
 SG_ InstFuelFlowEst : 23|16@0+ (0.000976562,0) [0|63.99899067] "grams/s"  CGM_HS,BSM_HS

BO_ 2015 USDT_OBD_Functional_Request: 8 CGM_HS
 SG_ DgnInf : 7|64@0+ (1,0) [0|1.84467440737096E+019] ""  TCM_HS,ECM_HS,BSM_HS

BO_ 989 PPEI_Hybrid_General_Status_2: 8 BSM_HS
 SG_ RdChrgrCntctrStatus : 47|3@0+ (1,0) [0|7] ""  CGM_HS
 SG_ RdHVCntctrShdwnReq : 44|2@0+ (1,0) [0|3] ""  CGM_HS
 SG_ AuxClntHtrVlvStat : 2|3@0+ (1,0) [0|7] ""  CGM_HS,ECM_HS
 SG_ EngCoolFanOpEnbl : 6|1@0+ (1,0) [0|1] ""  CGM_HS,ECM_HS
 SG_ DiagFreeRunCntrV : 23|1@0+ (1,0) [0|1] ""  CGM_HS,ECM_HS
 SG_ DiagFreeRunCntr : 22|23@0+ (1,0) [0|8388607] "min"  CGM_HS,ECM_HS
 SG_ JmpStrtEnbld : 5|1@0+ (1,0) [0|1] ""  CGM_HS
 SG_ HybFanSpdRq : 15|8@0+ (0.392157,0) [0|100.000035] "%"  CGM_HS,ECM_HS
 SG_ MntnceMdStEngRq : 7|1@0+ (1,0) [0|1] ""  CGM_HS,ECM_HS
 SG_ ThrmlRefCompSpdV : 54|1@0+ (1,0) [0|1] ""  CGM_HS,ECM_HS
 SG_ ThrmlRefCompSpd : 53|14@0+ (1,0) [0|16383] "rpm"  CGM_HS,ECM_HS
 SG_ RdHVCntctrCmdStat : 42|3@0+ (1,0) [0|7] ""  CGM_HS

BO_ 1927 DTC_Triggered_787: 7 BSM_HS
 SG_ DTCI_CodeSupported_787 : 40|1@0+ (1,0) [0|1] ""  CGM_HS
 SG_ DTCI_CurrentStatus_787 : 41|1@0+ (1,0) [0|1] ""  CGM_HS
 SG_ DTCI_DTCFailType_787 : 39|8@0+ (1,0) [0|255] ""  CGM_HS
 SG_ DTCI_DTCFaultType_787 : 55|8@0+ (1,0) [0|255] ""  CGM_HS
 SG_ DTCI_DTCNumber_787 : 23|16@0+ (1,0) [0|65535] ""  CGM_HS
 SG_ DTCI_DTCSource_787 : 15|8@0+ (1,0) [0|255] ""  CGM_HS
 SG_ DTCI_DTCTriggered_787 : 0|1@0+ (1,0) [0|1] ""  CGM_HS
 SG_ DTCI_HistStat_787 : 44|1@0+ (1,0) [0|1] ""  CGM_HS
 SG_ DTCI_TstFldCdClrdStat_787 : 43|1@0+ (1,0) [0|1] ""  CGM_HS
 SG_ DTCI_TstFldPwrUpSt_787 : 46|1@0+ (1,0) [0|1] ""  CGM_HS
 SG_ DTCI_TstNPsdCdClrdSt_787 : 42|1@0+ (1,0) [0|1] ""  CGM_HS
 SG_ DTCI_TstNPsdPwrUpSt_787 : 45|1@0+ (1,0) [0|1] ""  CGM_HS
 SG_ DTCIUnused1_787 : 7|1@0+ (1,0) [0|1] ""  CGM_HS
 SG_ DTCIUnused2_787 : 6|1@0+ (1,0) [0|1] ""  CGM_HS
 SG_ DTCIUnused3_787 : 5|1@0+ (1,0) [0|1] ""  CGM_HS
 SG_ DTCIUnused4_787 : 4|1@0+ (1,0) [0|1] ""  CGM_HS
 SG_ DTCIUnused5_787 : 3|1@0+ (1,0) [0|1] ""  CGM_HS
 SG_ DTCIUnused6_787 : 2|1@0+ (1,0) [0|1] ""  CGM_HS
 SG_ DTCIUnused7_787 : 1|1@0+ (1,0) [0|1] ""  CGM_HS
 SG_ DTCI_WrnIndRqdSt_787 : 47|1@0+ (1,0) [0|1] ""  CGM_HS

BO_ 2028 USDT_Resp_From_VICM_HS: 8 BSM_HS
 SG_ DgnInf : 7|64@0+ (1,0) [0|1.84467440737096E+019] ""  CGM_HS

BO_ 1516 UUDT_Resp_From_VICM_HS: 8 BSM_HS
 SG_ DgnInf : 7|64@0+ (1,0) [0|1.84467440737096E+019] ""  CGM_HS

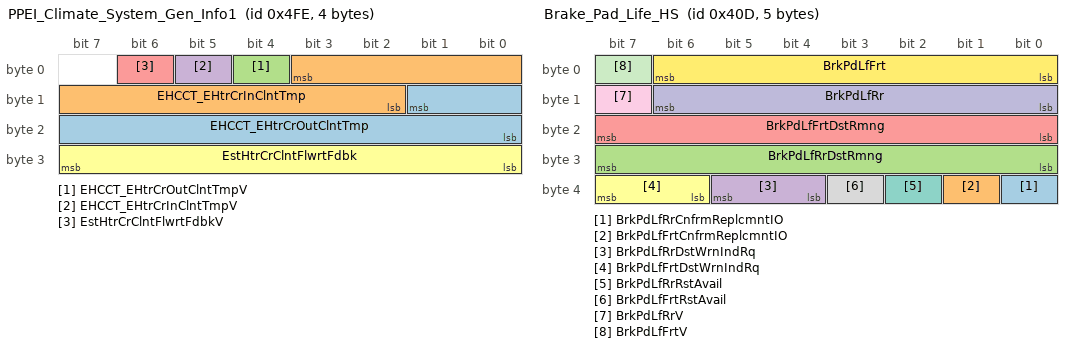
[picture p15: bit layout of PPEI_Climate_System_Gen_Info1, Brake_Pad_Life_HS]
BO_ 1278 PPEI_Climate_System_Gen_Info1: 4 ECM_HS
 SG_ EHCCT_EHtrCrOutClntTmp : 9|10@0+ (0.1857,-40) [-40|149.9711] "DegC"  CGM_HS,BCM_HS
 SG_ EHCCT_EHtrCrInClntTmp : 3|10@0+ (0.1857,-40) [-40|149.9711] "DegC"  CGM_HS,BCM_HS
 SG_ EHCCT_EHtrCrOutClntTmpV : 4|1@0+ (1,0) [0|1] ""  CGM_HS,BCM_HS
 SG_ EHCCT_EHtrCrInClntTmpV : 5|1@0+ (1,0) [0|1] ""  CGM_HS,BCM_HS
 SG_ EstHtrCrClntFlwrtFdbkV : 6|1@0+ (1,0) [0|1] ""  CGM_HS,BCM_HS
 SG_ EstHtrCrClntFlwrtFdbk : 31|8@0+ (0.2509,0) [0|63.9795] "l/min"  CGM_HS,BCM_HS

BO_ 1276 PPEI_OBD_Climate_Sys_Gen_Info_1: 2 ECM_HS
 SG_ CCFrBlwFnSpdFbkRatV : 0|1@0+ (1,0) [0|1] ""  CGM_HS,BCM_HS
 SG_ CCFrBlwFnSpdFbkRat : 15|8@0+ (0.392157,0) [0|100.000035] "%"  CGM_HS,BCM_HS

BO_ 1037 Brake_Pad_Life_HS: 5 EBCM_HS
 SG_ BrkPdLfRrCnfrmReplcmntIO : 32|1@0+ (1,0) [0|1] ""  CGM_HS,BCM_HS
 SG_ BrkPdLfFrtCnfrmReplcmntIO : 33|1@0+ (1,0) [0|1] ""  CGM_HS,BCM_HS
 SG_ BrkPdLfRrDstRmng : 31|8@0+ (100,0) [0|25500] ""  CGM_HS,BCM_HS
 SG_ BrkPdLfRrDstWrnIndRq : 37|2@0+ (1,0) [0|3] ""  CGM_HS,BCM_HS
 SG_ BrkPdLfFrtDstRmng : 23|8@0+ (100,0) [0|25500] ""  CGM_HS,BCM_HS
 SG_ BrkPdLfFrtDstWrnIndRq : 39|2@0+ (1,0) [0|3] ""  CGM_HS,BCM_HS
 SG_ BrkPdLfRrRstAvail : 34|1@0+ (1,0) [0|1] ""  CGM_HS,BCM_HS
 SG_ BrkPdLfFrtRstAvail : 35|1@0+ (1,0) [0|1] ""  CGM_HS,BCM_HS
 SG_ BrkPdLfRrV : 15|1@0+ (1,0) [0|1] ""  CGM_HS,BCM_HS
 SG_ BrkPdLfRr : 14|7@0+ (1,0) [0|127] "%"  CGM_HS,BCM_HS
 SG_ BrkPdLfFrtV : 7|1@0+ (1,0) [0|1] ""  CGM_HS,BCM_HS
 SG_ BrkPdLfFrt : 6|7@0+ (1,0) [0|127] "%"  CGM_HS,BCM_HS

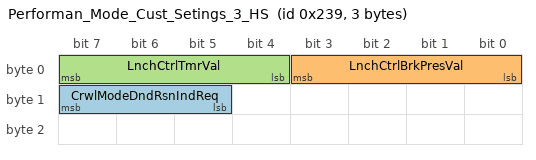
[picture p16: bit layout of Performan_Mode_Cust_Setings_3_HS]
BO_ 569 Performan_Mode_Cust_Setings_3_HS: 3 EBCM_HS
 SG_ CrwlModeDndRsnIndReq : 15|3@0+ (1,0) [0|7] ""  CGM_HS,BCM_HS
 SG_ LnchCtrlBrkPresVal : 3|4@0+ (10,0) [0|150] "%"  CGM_HS,BCM_HS
 SG_ LnchCtrlTmrVal : 7|4@0+ (1,0) [0|15] ""  CGM_HS,BCM_HS

CM_ SG_ 398 EngNTrnsRegStdyStTqV "ETEI 3.1";
CM_ SG_ 398 EngNTrnsRegStdyStTq "ETEI 3.1";
CM_ SG_ 398 EngActStdyStTorq "ETEI 3.1";
CM_ SG_ 398 EngActStdyStTorqV "ETEI 3.1";
CM_ SG_ 1906 DTCI_DTCFaultType_772 "Based on Powertrain definition.  Not expected to be supported by all devices.";
CM_ SG_ 1906 DTCI_DTCFailType_772 "Assigned per GMW3110, Appendix E";
CM_ SG_ 1906 DTCI_DTCSource_772 "This shall be equal to the Diagnostic Address of the transmittting device.";
CM_ SG_ 401 EngTrqTnsRqFld "Indicates that the Engine controller will not honor the torque request from the Transmission Controller due to a failure in the Rolling count, protection value, etc.";
CM_ SG_ 401 EngNTrnsRegStdyStTqV "ETEI 3.1";
CM_ SG_ 401 EngNTrnsRegStdyStTq "ETEI 3.1";
CM_ SG_ 401 EngAirflwStdyStTorqV "ETEI 3.1";
CM_ SG_ 401 EngAirflwStdyStTorq "ETEI 3.1";
CM_ SG_ 401 EngActStdyStTorqV "ETEI 3.1";
CM_ SG_ 401 EngActStdyStTorq "ETEI 3.1";
CM_ SG_ 1920 DTCI_DTCSource_780 "This shall be equal to the Diagnostic Address of the transmittting device.";
CM_ SG_ 1920 DTCI_DTCFaultType_780 "Based on Powertrain definition.  Not expected to be supported by all devices.";
CM_ SG_ 1920 DTCI_DTCFailType_780 "Assigned per GMW3110, Appendix E";
CM_ SG_ 1907 DTCI_DTCFaultType_773 "Based on Powertrain definition.  Not expected to be supported by all devices.";
CM_ SG_ 1907 DTCI_DTCFailType_773 "Assigned per GMW3110, Appendix E";
CM_ SG_ 1907 DTCI_DTCSource_773 "This shall be equal to the Diagnostic Address of the transmittting device.";
CM_ BO_ 715 "EOCM algorithm will transmit this message at a 40 ms periodic rate";
CM_ SG_ 1927 DTCI_DTCFailType_787 "Assigned per GMW3110, Appendix E";
CM_ SG_ 1927 DTCI_DTCFaultType_787 "Based on Powertrain definition.  Not expected to be supported by all devices.";
CM_ SG_ 1927 DTCI_DTCSource_787 "This shall be equal to the Diagnostic Address of the transmittting device.";
BA_DEF_ SG_  "GenSigSendOnInit" ENUM  "Not Initialized","Application","Handler","DLCLS","DLCHS","DLCCE","DLCFO";
BA_DEF_ SG_  "GenSigSendType" ENUM  "not used","not used","not used","not used","not used","not used","not used","NoSigSendType","not used","not used","OnAnyChange","OnChangeIfActive","OnDelta","DLCLS","DLCHS","DLCCE","DLCFO";
BA_DEF_ SG_  "GenSigDeltaValue" INT 0 0;
BA_DEF_ SG_  "VNSigAllNodes" ENUM  "No","Yes","DLCLS","DLCHS","DLCCE","DLCFO";
BA_DEF_ SG_  "VNSigSLHSSharedDiagnostic" ENUM  "No","Yes","DLCLS","DLCHS","DLCCE","DLCFO";
BA_DEF_ SG_  "VNSigSLHS_VNReq" ENUM  "No","Yes","DLCLS","DLCHS","DLCCE","DLCFO";
BA_DEF_ SG_  "SignalType" STRING ;
BA_DEF_ SG_  "PacketOrder" INT 0 65535;
BA_DEF_ SG_  "SignalLongName" STRING ;
BA_DEF_ SG_  "GenSigStartValue" INT 0 65535;
BA_DEF_ SG_  "TxSignalSendOnInit" ENUM  "Not Initialized","Application","Handler";
BA_DEF_ BO_  "GenMsgILSupport" ENUM  "No","Yes","DLCLS","DLCHS","DLCCE","DLCFO";
BA_DEF_ BO_  "AppGenMsgCycleTime" INT 0 0;
BA_DEF_ BO_  "TpApplType" STRING ;
BA_DEF_ BO_  "Prio" INT 0 7;
BA_DEF_ BO_  "MessageSubnet" ENUM  "LS","MS","HS","CE","PE","HV","FO","S1","HE","LE","HE2","DLCLS","DLCHS","DLCCE","DLCFO","vector_leerstring";
BA_DEF_ BO_  "DiagState" ENUM  "No","Yes";
BA_DEF_ BO_  "GenMsgIlSupport" ENUM  "No","Yes";
BA_DEF_ BO_  "GenMsgStartDelayTime" INT 0 100000;
BA_DEF_ BO_  "GenMsgDelayTime" INT 0 100000;
BA_DEF_ BO_  "GenMsgCycleTime" INT 0 100000;
BA_DEF_ BO_  "GenMsgSendType" ENUM  "cyclicX","spontanX","cyclicIfActiveX","spontanWithDelay","cyclicAndSpontanX","cyclicAndSpontanWithDelay","spontanWithRepitition","cyclicIfActiveAndSpontanWD";
BA_DEF_ BO_  "DiagResponse" ENUM  "No","Yes";
BA_DEF_ BO_  "DiagRequest" ENUM  "No","Yes";
BA_DEF_ BO_  "NmMessage" ENUM  "No","Yes";
BA_DEF_REL_ BU_SG_REL_  "GenSigSuprvResp" ENUM  "None","Notify App","Substitute Default","DLCLS","DLCHS","DLCCE","DLCFO";
BA_DEF_REL_ BU_SG_REL_  "GenSigSuprvRespSubValue" INT 0 65535;
BA_DEF_REL_ BU_SG_REL_  "GenSigRxStartValue" STRING ;
BA_DEF_REL_ BU_SG_REL_  "GenSigVDAFailResp" ENUM  "No","Yes","DLCLS","DLCHS","DLCCE","DLCFO";
BA_DEF_REL_ BU_SG_REL_  "GenSigVDAFailComment" STRING ;
BA_DEF_REL_ BU_SG_REL_  "GenSigVBitRespComment" STRING ;
BA_DEF_REL_ BU_SG_REL_  "GenSigVBitResp" ENUM  "No","Yes","DLCLS","DLCHS","DLCCE","DLCFO";
BA_DEF_REL_ BU_SG_REL_  "GenSigSuprvRespComment" STRING ;
BA_DEF_REL_ BU_SG_REL_  "GenSigTimeoutMsg" HEX 0 268435455;
BA_DEF_REL_ BU_SG_REL_  "GenSigTimeoutTime" INT 0 5000;
BA_DEF_DEF_  "GenSigSendOnInit" "Not Initialized";
BA_DEF_DEF_  "GenSigSendType" "NoSigSendType";
BA_DEF_DEF_  "GenSigDeltaValue" 0;
BA_DEF_DEF_  "VNSigAllNodes" "No";
BA_DEF_DEF_  "VNSigSLHSSharedDiagnostic" "No";
BA_DEF_DEF_  "VNSigSLHS_VNReq" "No";
BA_DEF_DEF_  "SignalType" "";
BA_DEF_DEF_  "PacketOrder" 0;
BA_DEF_DEF_  "SignalLongName" "";
BA_DEF_DEF_  "GenSigStartValue" 0;
BA_DEF_DEF_  "TxSignalSendOnInit" "Not Initialized";
BA_DEF_DEF_  "GenMsgILSupport" "Yes";
BA_DEF_DEF_  "AppGenMsgCycleTime" 0;
BA_DEF_DEF_  "TpApplType" "";
BA_DEF_DEF_  "Prio" 0;
BA_DEF_DEF_  "MessageSubnet" "LS";
BA_DEF_DEF_  "DiagState" "No";
BA_DEF_DEF_  "GenMsgIlSupport" "Yes";
BA_DEF_DEF_  "GenMsgStartDelayTime" 0;
BA_DEF_DEF_  "GenMsgDelayTime" 0;
BA_DEF_DEF_  "GenMsgCycleTime" 0;
BA_DEF_DEF_  "GenMsgSendType" "spontanX";
BA_DEF_DEF_  "DiagResponse" "No";
BA_DEF_DEF_  "DiagRequest" "No";
BA_DEF_DEF_  "NmMessage" "No";
BA_DEF_DEF_REL_ "GenSigSuprvResp" "None";
BA_DEF_DEF_REL_ "GenSigSuprvRespSubValue" 0;
BA_DEF_DEF_REL_ "GenSigRxStartValue" "";
BA_DEF_DEF_REL_ "GenSigVDAFailResp" "No";
BA_DEF_DEF_REL_ "GenSigVDAFailComment" "";
BA_DEF_DEF_REL_ "GenSigVBitRespComment" "";
BA_DEF_DEF_REL_ "GenSigVBitResp" "No";
BA_DEF_DEF_REL_ "GenSigSuprvRespComment" "";
BA_DEF_DEF_REL_ "GenSigTimeoutMsg" 0;
BA_DEF_DEF_REL_ "GenSigTimeoutTime" 0;
BA_ "GenMsgSendType" BO_ 967 0;
BA_ "GenMsgCycleTime" BO_ 967 100;
BA_ "MessageSubnet" BO_ 967 2;
BA_ "GenMsgSendType" BO_ 487 0;
BA_ "GenMsgCycleTime" BO_ 487 12;
BA_ "MessageSubnet" BO_ 487 2;
BA_ "GenMsgSendType" BO_ 398 0;
BA_ "GenMsgCycleTime" BO_ 398 12;
BA_ "MessageSubnet" BO_ 398 2;
BA_ "GenMsgSendType" BO_ 1267 0;
BA_ "GenMsgCycleTime" BO_ 1267 1000;
BA_ "MessageSubnet" BO_ 1267 2;
BA_ "GenMsgSendType" BO_ 1906 0;
BA_ "GenMsgCycleTime" BO_ 1906 1000;
BA_ "MessageSubnet" BO_ 1906 2;
BA_ "Prio" BO_ 1906 6;
BA_ "GenMsgSendType" BO_ 401 0;
BA_ "GenMsgCycleTime" BO_ 401 12;
BA_ "MessageSubnet" BO_ 401 2;
BA_ "DiagResponse" BO_ 2024 1;
BA_ "MessageSubnet" BO_ 2024 2;
BA_ "MessageSubnet" BO_ 1512 2;
BA_ "TpApplType" BO_ 1512 "DiagUUDTResponse";
BA_ "GenMsgILSupport" BO_ 1512 0;
BA_ "GenMsgSendType" BO_ 872 0;
BA_ "GenMsgCycleTime" BO_ 872 25;
BA_ "MessageSubnet" BO_ 872 2;
BA_ "GenMsgSendType" BO_ 331 0;
BA_ "GenMsgCycleTime" BO_ 331 1000;
BA_ "MessageSubnet" BO_ 331 2;
BA_ "GenMsgSendType" BO_ 1034 0;
BA_ "GenMsgCycleTime" BO_ 1034 100;
BA_ "MessageSubnet" BO_ 1034 2;
BA_ "GenMsgSendType" BO_ 1033 0;
BA_ "GenMsgCycleTime" BO_ 1033 100;
BA_ "MessageSubnet" BO_ 1033 2;
BA_ "GenMsgSendType" BO_ 1013 0;
BA_ "GenMsgCycleTime" BO_ 1013 250;
BA_ "MessageSubnet" BO_ 1013 2;
BA_ "GenMsgSendType" BO_ 170 0;
BA_ "GenMsgCycleTime" BO_ 170 12;
BA_ "MessageSubnet" BO_ 170 2;
BA_ "GenMsgSendType" BO_ 647 0;
BA_ "GenMsgCycleTime" BO_ 647 25;
BA_ "MessageSubnet" BO_ 647 2;
BA_ "GenMsgSendType" BO_ 199 0;
BA_ "GenMsgCycleTime" BO_ 199 12;
BA_ "MessageSubnet" BO_ 199 2;
BA_ "GenMsgSendType" BO_ 190 0;
BA_ "GenMsgCycleTime" BO_ 190 12;
BA_ "MessageSubnet" BO_ 190 2;
BA_ "DiagRequest" BO_ 579 1;
BA_ "MessageSubnet" BO_ 579 2;
BA_ "GenMsgSendType" BO_ 707 0;
BA_ "GenMsgCycleTime" BO_ 707 50;
BA_ "MessageSubnet" BO_ 707 2;
BA_ "GenMsgSendType" BO_ 249 0;
BA_ "GenMsgCycleTime" BO_ 249 12;
BA_ "MessageSubnet" BO_ 249 2;
BA_ "GenMsgSendType" BO_ 1273 0;
BA_ "GenMsgCycleTime" BO_ 1273 500;
BA_ "MessageSubnet" BO_ 1273 2;
BA_ "GenMsgSendType" BO_ 208 0;
BA_ "GenMsgCycleTime" BO_ 208 100;
BA_ "MessageSubnet" BO_ 208 2;
BA_ "GenMsgSendType" BO_ 753 0;
BA_ "GenMsgCycleTime" BO_ 753 100;
BA_ "MessageSubnet" BO_ 753 2;
BA_ "GenMsgSendType" BO_ 508 0;
BA_ "GenMsgCycleTime" BO_ 508 50;
BA_ "MessageSubnet" BO_ 508 2;
BA_ "GenMsgSendType" BO_ 454 0;
BA_ "GenMsgCycleTime" BO_ 454 25;
BA_ "MessageSubnet" BO_ 454 2;
BA_ "GenMsgSendType" BO_ 554 0;
BA_ "GenMsgCycleTime" BO_ 554 100;
BA_ "MessageSubnet" BO_ 554 2;
BA_ "GenMsgSendType" BO_ 462 0;
BA_ "GenMsgCycleTime" BO_ 462 20;
BA_ "MessageSubnet" BO_ 462 2;
BA_ "GenMsgSendType" BO_ 510 0;
BA_ "GenMsgCycleTime" BO_ 510 50;
BA_ "MessageSubnet" BO_ 510 2;
BA_ "GenMsgSendType" BO_ 1920 0;
BA_ "GenMsgCycleTime" BO_ 1920 1000;
BA_ "MessageSubnet" BO_ 1920 2;
BA_ "GenMsgSendType" BO_ 1907 0;
BA_ "GenMsgCycleTime" BO_ 1907 1000;
BA_ "MessageSubnet" BO_ 1907 2;
BA_ "Prio" BO_ 1907 6;
BA_ "DiagResponse" BO_ 1603 1;
BA_ "MessageSubnet" BO_ 1603 2;
BA_ "MessageSubnet" BO_ 1347 2;
BA_ "TpApplType" BO_ 1347 "DiagUUDTResponse";
BA_ "GenMsgILSupport" BO_ 1347 0;
BA_ "GenMsgSendType" BO_ 455 0;
BA_ "GenMsgCycleTime" BO_ 455 20;
BA_ "MessageSubnet" BO_ 455 2;
BA_ "GenMsgSendType" BO_ 975 0;
BA_ "GenMsgCycleTime" BO_ 975 100;
BA_ "MessageSubnet" BO_ 975 2;
BA_ "GenMsgSendType" BO_ 1223 0;
BA_ "GenMsgCycleTime" BO_ 1223 500;
BA_ "MessageSubnet" BO_ 1223 2;
BA_ "GenMsgSendType" BO_ 211 0;
BA_ "GenMsgCycleTime" BO_ 211 12;
BA_ "MessageSubnet" BO_ 211 2;
BA_ "GenMsgSendType" BO_ 988 0;
BA_ "GenMsgCycleTime" BO_ 988 100;
BA_ "MessageSubnet" BO_ 988 2;
BA_ "GenMsgSendType" BO_ 209 0;
BA_ "GenMsgCycleTime" BO_ 209 10;
BA_ "MessageSubnet" BO_ 209 2;
BA_ "MessageSubnet" BO_ 715 2;
BA_ "AppGenMsgCycleTime" BO_ 715 40;
BA_ "GenMsgSendType" BO_ 453 0;
BA_ "GenMsgCycleTime" BO_ 453 25;
BA_ "MessageSubnet" BO_ 453 2;
BA_ "GenMsgSendType" BO_ 495 0;
BA_ "GenMsgCycleTime" BO_ 495 12;
BA_ "MessageSubnet" BO_ 495 2;
BA_ "DiagRequest" BO_ 2020 1;
BA_ "MessageSubnet" BO_ 2020 2;
BA_ "GenMsgSendType" BO_ 493 0;
BA_ "GenMsgCycleTime" BO_ 493 12;
BA_ "MessageSubnet" BO_ 493 2;
BA_ "MessageSubnet" BO_ 2015 2;
BA_ "GenMsgILSupport" BO_ 2015 0;
BA_ "GenMsgSendType" BO_ 989 0;
BA_ "GenMsgCycleTime" BO_ 989 100;
BA_ "MessageSubnet" BO_ 989 2;
BA_ "GenMsgSendType" BO_ 1927 0;
BA_ "GenMsgCycleTime" BO_ 1927 1000;
BA_ "MessageSubnet" BO_ 1927 2;
BA_ "DiagResponse" BO_ 2028 1;
BA_ "MessageSubnet" BO_ 2028 2;
BA_ "MessageSubnet" BO_ 1516 2;
BA_ "TpApplType" BO_ 1516 "DiagUUDTResponse";
BA_ "GenMsgILSupport" BO_ 1516 0;
BA_ "GenMsgSendType" BO_ 1278 0;
BA_ "GenMsgCycleTime" BO_ 1278 1000;
BA_ "MessageSubnet" BO_ 1278 2;
BA_ "GenMsgSendType" BO_ 1276 0;
BA_ "GenMsgCycleTime" BO_ 1276 1000;
BA_ "MessageSubnet" BO_ 1276 2;
BA_ "GenMsgSendType" BO_ 1037 0;
BA_ "GenMsgCycleTime" BO_ 1037 5000;
BA_ "GenMsgDelayTime" BO_ 1037 100;
BA_ "MessageSubnet" BO_ 1037 2;
BA_ "GenMsgSendType" BO_ 569 0;
BA_ "GenMsgCycleTime" BO_ 569 250;
BA_ "MessageSubnet" BO_ 569 2;
BA_ "SignalLongName" SG_ 967 PTRlyStatProtVal "Powertrain Relay Status Protection Value";
BA_ "SignalType" SG_ 967 PTRlyStatProtVal "UNM";
BA_ "VNSigAllNodes" SG_ 967 PTRlyStatProtVal 1;
BA_ "SignalLongName" SG_ 967 PTRlyStatARC "Powertrain Relay Status Alive Rolling Count";
BA_ "SignalType" SG_ 967 PTRlyStatARC "UNM";
BA_ "VNSigAllNodes" SG_ 967 PTRlyStatARC 1;
BA_ "SignalLongName" SG_ 967 PRS_PTRlyFdbkCktVlt "Powertrain Relay Status : Powertrain Relay Feedback Circuit Voltage";
BA_ "PacketOrder" SG_ 967 PRS_PTRlyFdbkCktVlt 5;
BA_ "SignalType" SG_ 967 PRS_PTRlyFdbkCktVlt "UNM";
BA_ "VNSigAllNodes" SG_ 967 PRS_PTRlyFdbkCktVlt 1;
BA_ "SignalLongName" SG_ 967 PRS_PTRlyFdbkCtVtNtIR "Powertrain Relay Status : Powertrain Relay Feedback Circuit Voltage Not In Range";
BA_ "PacketOrder" SG_ 967 PRS_PTRlyFdbkCtVtNtIR 4;
BA_ "SignalType" SG_ 967 PRS_PTRlyFdbkCtVtNtIR "BLN";
BA_ "VNSigAllNodes" SG_ 967 PRS_PTRlyFdbkCtVtNtIR 1;
BA_ "SignalLongName" SG_ 967 PRS_PTRlyFdbkCktFAct "Powertrain Relay Status : Powertrain Relay Feedback Circuit Fault Active";
BA_ "PacketOrder" SG_ 967 PRS_PTRlyFdbkCktFAct 3;
BA_ "SignalType" SG_ 967 PRS_PTRlyFdbkCktFAct "BLN";
BA_ "VNSigAllNodes" SG_ 967 PRS_PTRlyFdbkCktFAct 1;
BA_ "SignalLongName" SG_ 967 PRS_PTRlyCntrlCktFAct "Powertrain Relay Status : Powertrain Relay Control Circuit Fault Active";
BA_ "PacketOrder" SG_ 967 PRS_PTRlyCntrlCktFAct 2;
BA_ "SignalType" SG_ 967 PRS_PTRlyCntrlCktFAct "BLN";
BA_ "VNSigAllNodes" SG_ 967 PRS_PTRlyCntrlCktFAct 1;
BA_ "SignalLongName" SG_ 967 PRS_PTRlyCmdSt "Powertrain Relay Status : Powertrain Relay Commanded State";
BA_ "PacketOrder" SG_ 967 PRS_PTRlyCmdSt 1;
BA_ "SignalType" SG_ 967 PRS_PTRlyCmdSt "ENM";
BA_ "VNSigAllNodes" SG_ 967 PRS_PTRlyCmdSt 1;
BA_ "SignalLongName" SG_ 487 CmmndAirFuelRatio "Commanded Air Fuel Ratio";
BA_ "SignalType" SG_ 487 CmmndAirFuelRatio "UNM";
BA_ "VNSigAllNodes" SG_ 487 CmmndAirFuelRatio 1;
BA_ "SignalLongName" SG_ 487 InstFuelFlowEst "Instantaneous Fuel Flow Estimate";
BA_ "SignalType" SG_ 487 InstFuelFlowEst "UNM";
BA_ "VNSigAllNodes" SG_ 487 InstFuelFlowEst 1;
BA_ "SignalLongName" SG_ 487 FuelDelPressRqd "Fuel Delivery Pressure Requested";
BA_ "SignalType" SG_ 487 FuelDelPressRqd "UNM";
BA_ "VNSigAllNodes" SG_ 487 FuelDelPressRqd 1;
BA_ "SignalLongName" SG_ 487 EngRunng "Engine Running";
BA_ "SignalType" SG_ 487 EngRunng "BLN";
BA_ "VNSigAllNodes" SG_ 487 EngRunng 1;
BA_ "SignalLongName" SG_ 487 FlPmpEDscOtptCmdSta "Fuel Pump Enabled Discrete Output Commanded Status";
BA_ "SignalType" SG_ 487 FlPmpEDscOtptCmdSta "ENM";
BA_ "VNSigAllNodes" SG_ 487 FlPmpEDscOtptCmdSta 1;
BA_ "SignalLongName" SG_ 487 FuelCntlSysFltPrsnt "Fuel Control System Fault Present";
BA_ "SignalType" SG_ 487 FuelCntlSysFltPrsnt "BLN";
BA_ "VNSigAllNodes" SG_ 487 FuelCntlSysFltPrsnt 1;
BA_ "SignalLongName" SG_ 487 HiPresFuelPmpDelDur "High Pressure Fuel Pump Delivery Duration";
BA_ "SignalType" SG_ 487 HiPresFuelPmpDelDur "UNM";
BA_ "VNSigAllNodes" SG_ 487 HiPresFuelPmpDelDur 1;
BA_ "SignalLongName" SG_ 487 HiPresFuelPmpCntMd "High Pressure Fuel Pump Control Mode";
BA_ "SignalType" SG_ 487 HiPresFuelPmpCntMd "ENM";
BA_ "VNSigAllNodes" SG_ 487 HiPresFuelPmpCntMd 1;
BA_ "SignalLongName" SG_ 398 EngNTrnsRegStdyStTqV "Engine Non-Transmission Regulated Steady State Torque Validity";
BA_ "SignalType" SG_ 398 EngNTrnsRegStdyStTqV "ENM";
BA_ "VNSigAllNodes" SG_ 398 EngNTrnsRegStdyStTqV 1;
BA_ "SignalLongName" SG_ 398 EngNTrnsRegStdyStTq "Engine Non-Transmission Regulated Steady State Torque";
BA_ "SignalType" SG_ 398 EngNTrnsRegStdyStTq "UNM";
BA_ "VNSigAllNodes" SG_ 398 EngNTrnsRegStdyStTq 1;
BA_ "SignalLongName" SG_ 398 EngActStdyStTorq "Engine Actual Steady State Torque";
BA_ "SignalType" SG_ 398 EngActStdyStTorq "UNM";
BA_ "VNSigAllNodes" SG_ 398 EngActStdyStTorq 1;
BA_ "SignalLongName" SG_ 398 AccKdwnAtv "Accelerator Kick Down Detected";
BA_ "SignalType" SG_ 398 AccKdwnAtv "BLN";
BA_ "VNSigAllNodes" SG_ 398 AccKdwnAtv 1;
BA_ "SignalLongName" SG_ 398 EngActStdyStTorqV "Engine Actual Steady State Torque Validity";
BA_ "SignalType" SG_ 398 EngActStdyStTorqV "ENM";
BA_ "VNSigAllNodes" SG_ 398 EngActStdyStTorqV 1;
BA_ "SignalLongName" SG_ 398 TrnsEngSpdReqFld "Transmission Engine Speed Request Failed";
BA_ "SignalType" SG_ 398 TrnsEngSpdReqFld "BLN";
BA_ "VNSigAllNodes" SG_ 398 TrnsEngSpdReqFld 1;
BA_ "SignalLongName" SG_ 398 PTACCAct "Powertrain Adaptive Cruise Control Active";
BA_ "SignalType" SG_ 398 PTACCAct "BLN";
BA_ "VNSigAllNodes" SG_ 398 PTACCAct 1;
BA_ "SignalLongName" SG_ 398 CTSS_StbltyLvl "Crankshaft Torque Stability Status : Stability Level";
BA_ "PacketOrder" SG_ 398 CTSS_StbltyLvl 2;
BA_ "SignalType" SG_ 398 CTSS_StbltyLvl "ENM";
BA_ "VNSigAllNodes" SG_ 398 CTSS_StbltyLvl 1;
BA_ "SignalLongName" SG_ 398 CTSS_StbltyTyp "Crankshaft Torque Stability Status : Stability Type";
BA_ "PacketOrder" SG_ 398 CTSS_StbltyTyp 1;
BA_ "SignalType" SG_ 398 CTSS_StbltyTyp "ENM";
BA_ "VNSigAllNodes" SG_ 398 CTSS_StbltyTyp 1;
BA_ "SignalLongName" SG_ 398 CrksftNTrnsRegCmdTq "Crankshaft Non-Transmission Regulated Commanded Torque";
BA_ "SignalType" SG_ 398 CrksftNTrnsRegCmdTq "UNM";
BA_ "VNSigAllNodes" SG_ 398 CrksftNTrnsRegCmdTq 1;
BA_ "SignalLongName" SG_ 398 EngImmTrqTnsRqStat "Engine Immediate Torque Transmission Request Status";
BA_ "SignalType" SG_ 398 EngImmTrqTnsRqStat "ENM";
BA_ "VNSigAllNodes" SG_ 398 EngImmTrqTnsRqStat 1;
BA_ "SignalLongName" SG_ 398 EngImmTrqTnsRqLmSt "Engine Immediate Torque Transmission Request Limiting Status";
BA_ "SignalType" SG_ 398 EngImmTrqTnsRqLmSt "ENM";
BA_ "VNSigAllNodes" SG_ 398 EngImmTrqTnsRqLmSt 1;
BA_ "SignalLongName" SG_ 398 EngPrdctTrqTnsRqStat "Engine Predicted Torque Transmission Request Status";
BA_ "SignalType" SG_ 398 EngPrdctTrqTnsRqStat "ENM";
BA_ "VNSigAllNodes" SG_ 398 EngPrdctTrqTnsRqStat 1;
BA_ "SignalLongName" SG_ 398 EngPrdctTrqTnsRqLmS "Engine Predicted Torque Transmission Request Limiting Status";
BA_ "SignalType" SG_ 398 EngPrdctTrqTnsRqLmS "ENM";
BA_ "VNSigAllNodes" SG_ 398 EngPrdctTrqTnsRqLmS 1;
BA_ "SignalLongName" SG_ 1267 VehMassNom "Vehicle Mass Nominal";
BA_ "SignalType" SG_ 1267 VehMassNom "UNM";
BA_ "VNSigAllNodes" SG_ 1267 VehMassNom 1;
BA_ "SignalLongName" SG_ 1906 DTCI_DTCFaultType_772 "Diagnostic Trouble Code Information Extended 772 : Diagnostic Trouble Code Fault Type";
BA_ "PacketOrder" SG_ 1906 DTCI_DTCFaultType_772 20;
BA_ "SignalType" SG_ 1906 DTCI_DTCFaultType_772 "ENM";
BA_ "VNSigAllNodes" SG_ 1906 DTCI_DTCFaultType_772 1;
BA_ "SignalLongName" SG_ 1906 DTCI_CodeSupported_772 "Diagnostic Trouble Code Information Extended 772 : Code Supported";
BA_ "PacketOrder" SG_ 1906 DTCI_CodeSupported_772 19;
BA_ "SignalType" SG_ 1906 DTCI_CodeSupported_772 "BLN";
BA_ "VNSigAllNodes" SG_ 1906 DTCI_CodeSupported_772 1;
BA_ "SignalLongName" SG_ 1906 DTCI_CurrentStatus_772 "Diagnostic Trouble Code Information Extended 772 : Current Status";
BA_ "PacketOrder" SG_ 1906 DTCI_CurrentStatus_772 18;
BA_ "SignalType" SG_ 1906 DTCI_CurrentStatus_772 "BLN";
BA_ "VNSigAllNodes" SG_ 1906 DTCI_CurrentStatus_772 1;
BA_ "SignalLongName" SG_ 1906 DTCI_TstNPsdCdClrdSt_772 "Diagnostic Trouble Code Information Extended 772 : Test Not Passed Since Code Cleared Status";
BA_ "PacketOrder" SG_ 1906 DTCI_TstNPsdCdClrdSt_772 17;
BA_ "SignalType" SG_ 1906 DTCI_TstNPsdCdClrdSt_772 "BLN";
BA_ "VNSigAllNodes" SG_ 1906 DTCI_TstNPsdCdClrdSt_772 1;
BA_ "SignalLongName" SG_ 1906 DTCI_TstFldCdClrdStat_772 "Diagnostic Trouble Code Information Extended 772 : Test Failed Since Code Cleared Status";
BA_ "PacketOrder" SG_ 1906 DTCI_TstFldCdClrdStat_772 16;
BA_ "SignalType" SG_ 1906 DTCI_TstFldCdClrdStat_772 "BLN";
BA_ "VNSigAllNodes" SG_ 1906 DTCI_TstFldCdClrdStat_772 1;
BA_ "SignalLongName" SG_ 1906 DTCI_HistStat_772 "Diagnostic Trouble Code Information Extended 772 : History Status";
BA_ "PacketOrder" SG_ 1906 DTCI_HistStat_772 15;
BA_ "SignalType" SG_ 1906 DTCI_HistStat_772 "BLN";
BA_ "VNSigAllNodes" SG_ 1906 DTCI_HistStat_772 1;
BA_ "SignalLongName" SG_ 1906 DTCI_TstNPsdPwrUpSt_772 "Diagnostic Trouble Code Information Extended 772 : Test Not Passed Since Power Up Status";
BA_ "PacketOrder" SG_ 1906 DTCI_TstNPsdPwrUpSt_772 14;
BA_ "SignalType" SG_ 1906 DTCI_TstNPsdPwrUpSt_772 "BLN";
BA_ "VNSigAllNodes" SG_ 1906 DTCI_TstNPsdPwrUpSt_772 1;
BA_ "SignalLongName" SG_ 1906 DTCI_TstFldPwrUpSt_772 "Diagnostic Trouble Code Information Extended 772 : Test Failed Since Power Up Status";
BA_ "PacketOrder" SG_ 1906 DTCI_TstFldPwrUpSt_772 13;
BA_ "SignalType" SG_ 1906 DTCI_TstFldPwrUpSt_772 "BLN";
BA_ "VNSigAllNodes" SG_ 1906 DTCI_TstFldPwrUpSt_772 1;
BA_ "SignalLongName" SG_ 1906 DTCI_WrnIndRqdSt_772 "Diagnostic Trouble Code Information Extended 772 : Warning Indicator Requested Status";
BA_ "PacketOrder" SG_ 1906 DTCI_WrnIndRqdSt_772 12;
BA_ "SignalType" SG_ 1906 DTCI_WrnIndRqdSt_772 "BLN";
BA_ "VNSigAllNodes" SG_ 1906 DTCI_WrnIndRqdSt_772 1;
BA_ "SignalLongName" SG_ 1906 DTCI_DTCFailType_772 "Diagnostic Trouble Code Information Extended 772 : Diagnostic Trouble Code Failure Type";
BA_ "PacketOrder" SG_ 1906 DTCI_DTCFailType_772 11;
BA_ "SignalType" SG_ 1906 DTCI_DTCFailType_772 "UNM";
BA_ "VNSigAllNodes" SG_ 1906 DTCI_DTCFailType_772 1;
BA_ "SignalLongName" SG_ 1906 DTCI_DTCNumber_772 "Diagnostic Trouble Code Information Extended 772 : Diagnostic Trouble Code Number";
BA_ "PacketOrder" SG_ 1906 DTCI_DTCNumber_772 10;
BA_ "SignalType" SG_ 1906 DTCI_DTCNumber_772 "UNM";
BA_ "VNSigAllNodes" SG_ 1906 DTCI_DTCNumber_772 1;
BA_ "SignalLongName" SG_ 1906 DTCI_DTCSource_772 "Diagnostic Trouble Code Information Extended 772 : Diagnostic Trouble Code Source";
BA_ "PacketOrder" SG_ 1906 DTCI_DTCSource_772 9;
BA_ "SignalType" SG_ 1906 DTCI_DTCSource_772 "UNM";
BA_ "VNSigAllNodes" SG_ 1906 DTCI_DTCSource_772 1;
BA_ "SignalLongName" SG_ 1906 DTCI_DTCTriggered_772 "Diagnostic Trouble Code Information Extended 772 : Diagnostic Trouble Code Triggered";
BA_ "PacketOrder" SG_ 1906 DTCI_DTCTriggered_772 8;
BA_ "SignalType" SG_ 1906 DTCI_DTCTriggered_772 "BLN";
BA_ "VNSigAllNodes" SG_ 1906 DTCI_DTCTriggered_772 1;
BA_ "SignalLongName" SG_ 1906 DTCIUnused7_772 "Diagnostic Trouble Code Information Extended 772 : Unused 7";
BA_ "PacketOrder" SG_ 1906 DTCIUnused7_772 7;
BA_ "SignalType" SG_ 1906 DTCIUnused7_772 "BLN";
BA_ "VNSigAllNodes" SG_ 1906 DTCIUnused7_772 1;
BA_ "SignalLongName" SG_ 1906 DTCIUnused6_772 "Diagnostic Trouble Code Information Extended 772 : Unused 6";
BA_ "PacketOrder" SG_ 1906 DTCIUnused6_772 6;
BA_ "SignalType" SG_ 1906 DTCIUnused6_772 "BLN";
BA_ "VNSigAllNodes" SG_ 1906 DTCIUnused6_772 1;
BA_ "SignalLongName" SG_ 1906 DTCIUnused5_772 "Diagnostic Trouble Code Information Extended 772 : Unused 5";
BA_ "PacketOrder" SG_ 1906 DTCIUnused5_772 5;
BA_ "SignalType" SG_ 1906 DTCIUnused5_772 "BLN";
BA_ "VNSigAllNodes" SG_ 1906 DTCIUnused5_772 1;
BA_ "SignalLongName" SG_ 1906 DTCIUnused4_772 "Diagnostic Trouble Code Information Extended 772 : Unused 4";
BA_ "PacketOrder" SG_ 1906 DTCIUnused4_772 4;
BA_ "SignalType" SG_ 1906 DTCIUnused4_772 "BLN";
BA_ "VNSigAllNodes" SG_ 1906 DTCIUnused4_772 1;
BA_ "SignalLongName" SG_ 1906 DTCIUnused3_772 "Diagnostic Trouble Code Information Extended 772 : Unused 3";
BA_ "PacketOrder" SG_ 1906 DTCIUnused3_772 3;
BA_ "SignalType" SG_ 1906 DTCIUnused3_772 "BLN";
BA_ "VNSigAllNodes" SG_ 1906 DTCIUnused3_772 1;
BA_ "SignalLongName" SG_ 1906 DTCIUnused2_772 "Diagnostic Trouble Code Information Extended 772 : Unused 2";
BA_ "PacketOrder" SG_ 1906 DTCIUnused2_772 2;
BA_ "SignalType" SG_ 1906 DTCIUnused2_772 "BLN";
BA_ "VNSigAllNodes" SG_ 1906 DTCIUnused2_772 1;
BA_ "SignalLongName" SG_ 1906 DTCIUnused1_772 "Diagnostic Trouble Code Information Extended 772 : Unused 1";
BA_ "PacketOrder" SG_ 1906 DTCIUnused1_772 1;
BA_ "SignalType" SG_ 1906 DTCIUnused1_772 "BLN";
BA_ "VNSigAllNodes" SG_ 1906 DTCIUnused1_772 1;
BA_ "SignalLongName" SG_ 401 EngTrqTrnRqTmpFld "Engine Torque Transmission Request Temporarily Failed";
BA_ "SignalType" SG_ 401 EngTrqTrnRqTmpFld "BLN";
BA_ "VNSigAllNodes" SG_ 401 EngTrqTrnRqTmpFld 1;
BA_ "SignalLongName" SG_ 401 EngTrqTrnRqLmtd "Engine Torque Transmission Request Limited";
BA_ "SignalType" SG_ 401 EngTrqTrnRqLmtd "BLN";
BA_ "VNSigAllNodes" SG_ 401 EngTrqTrnRqLmtd 1;
BA_ "SignalLongName" SG_ 401 TrnsEngSpdReqFld "Transmission Engine Speed Request Failed";
BA_ "SignalType" SG_ 401 TrnsEngSpdReqFld "BLN";
BA_ "VNSigAllNodes" SG_ 401 TrnsEngSpdReqFld 1;
BA_ "SignalLongName" SG_ 401 ThrtCommndPos "Throttle Commanded Position";
BA_ "SignalType" SG_ 401 ThrtCommndPos "UNM";
BA_ "VNSigAllNodes" SG_ 401 ThrtCommndPos 1;
BA_ "SignalLongName" SG_ 401 EngTrqTnsRqFld "Engine Torque Transmission Request Failed";
BA_ "SignalType" SG_ 401 EngTrqTnsRqFld "BLN";
BA_ "VNSigAllNodes" SG_ 401 EngTrqTnsRqFld 1;
BA_ "SignalLongName" SG_ 401 EngTrqRdnFld "Engine Torque Reduction Failed";
BA_ "SignalType" SG_ 401 EngTrqRdnFld "BLN";
BA_ "VNSigAllNodes" SG_ 401 EngTrqRdnFld 1;
BA_ "SignalLongName" SG_ 401 EngNTrnsRegStdyStTqV "Engine Non-Transmission Regulated Steady State Torque Validity";
BA_ "SignalType" SG_ 401 EngNTrnsRegStdyStTqV "ENM";
BA_ "VNSigAllNodes" SG_ 401 EngNTrnsRegStdyStTqV 1;
BA_ "SignalLongName" SG_ 401 EngNTrnsRegStdyStTq "Engine Non-Transmission Regulated Steady State Torque";
BA_ "SignalType" SG_ 401 EngNTrnsRegStdyStTq "UNM";
BA_ "VNSigAllNodes" SG_ 401 EngNTrnsRegStdyStTq 1;
BA_ "SignalLongName" SG_ 401 EngAirflwStdyStTorqV "Engine Airflow Steady State Torque Validity";
BA_ "SignalType" SG_ 401 EngAirflwStdyStTorqV "ENM";
BA_ "VNSigAllNodes" SG_ 401 EngAirflwStdyStTorqV 1;
BA_ "SignalLongName" SG_ 401 EngAirflwStdyStTorq "Engine Airflow Steady State Torque";
BA_ "SignalType" SG_ 401 EngAirflwStdyStTorq "UNM";
BA_ "VNSigAllNodes" SG_ 401 EngAirflwStdyStTorq 1;
BA_ "SignalLongName" SG_ 401 AccKdwnAtv "Accelerator Kick Down Detected";
BA_ "SignalType" SG_ 401 AccKdwnAtv "BLN";
BA_ "VNSigAllNodes" SG_ 401 AccKdwnAtv 1;
BA_ "SignalLongName" SG_ 401 AccPosV "Accelerator Effective Position Validity";
BA_ "SignalType" SG_ 401 AccPosV "ENM";
BA_ "VNSigAllNodes" SG_ 401 AccPosV 1;
BA_ "SignalLongName" SG_ 401 AccPos "Accelerator Effective Position";
BA_ "SignalType" SG_ 401 AccPos "UNM";
BA_ "VNSigAllNodes" SG_ 401 AccPos 1;
BA_ "SignalLongName" SG_ 401 EngActStdyStTorqV "Engine Actual Steady State Torque Validity";
BA_ "SignalType" SG_ 401 EngActStdyStTorqV "ENM";
BA_ "VNSigAllNodes" SG_ 401 EngActStdyStTorqV 1;
BA_ "SignalLongName" SG_ 401 EngActStdyStTorq "Engine Actual Steady State Torque";
BA_ "SignalType" SG_ 401 EngActStdyStTorq "UNM";
BA_ "VNSigAllNodes" SG_ 401 EngActStdyStTorq 1;
BA_ "SignalLongName" SG_ 2024 DgnInf "Diagnostic Information";
BA_ "SignalType" SG_ 2024 DgnInf "UNM";
BA_ "VNSigSLHSSharedDiagnostic" SG_ 2024 DgnInf 1;
BA_ "VNSigAllNodes" SG_ 2024 DgnInf 1;
BA_ "GenSigDeltaValue" SG_ 2024 DgnInf 1;
BA_ "GenSigSendType" SG_ 2024 DgnInf 12;
BA_ "SignalLongName" SG_ 1512 DgnInf "Diagnostic Information";
BA_ "SignalType" SG_ 1512 DgnInf "UNM";
BA_ "VNSigSLHSSharedDiagnostic" SG_ 1512 DgnInf 1;
BA_ "VNSigAllNodes" SG_ 1512 DgnInf 1;
BA_ "GenSigDeltaValue" SG_ 1512 DgnInf 1;
BA_ "GenSigSendType" SG_ 1512 DgnInf 12;
BA_ "SignalLongName" SG_ 872 ESBR_AutoBrkgRqTyp "Electronic Shift Braking Request : Automatic Braking Request Type";
BA_ "PacketOrder" SG_ 872 ESBR_AutoBrkgRqTyp 2;
BA_ "SignalType" SG_ 872 ESBR_AutoBrkgRqTyp "ENM";
BA_ "VNSigAllNodes" SG_ 872 ESBR_AutoBrkgRqTyp 1;
BA_ "SignalLongName" SG_ 872 ESBR_AutoBrkgRqd "Electronic Shift Braking Request : Automatic Braking Requested";
BA_ "PacketOrder" SG_ 872 ESBR_AutoBrkgRqd 1;
BA_ "SignalType" SG_ 872 ESBR_AutoBrkgRqd "ENM";
BA_ "VNSigAllNodes" SG_ 872 ESBR_AutoBrkgRqd 1;
BA_ "SignalLongName" SG_ 872 ElcShftBrkgRqPVal "Electronic Shift Braking Request Protection Value";
BA_ "SignalType" SG_ 872 ElcShftBrkgRqPVal "UNM";
BA_ "VNSigAllNodes" SG_ 872 ElcShftBrkgRqPVal 1;
BA_ "SignalLongName" SG_ 872 ElcShftBrkgRqARC "Electronic Shift Braking Request Alive Rolling Count";
BA_ "SignalType" SG_ 872 ElcShftBrkgRqARC "UNM";
BA_ "VNSigAllNodes" SG_ 872 ElcShftBrkgRqARC 1;
BA_ "SignalLongName" SG_ 331 TrlrPrfDltn "Trailer Profile Deletion";
BA_ "SignalType" SG_ 331 TrlrPrfDltn "ENM";
BA_ "VNSigAllNodes" SG_ 331 TrlrPrfDltn 1;
BA_ "SignalLongName" SG_ 331 TrlrPlcrdPrs "Trailer Placard Pressure";
BA_ "SignalType" SG_ 331 TrlrPlcrdPrs "UNM";
BA_ "VNSigAllNodes" SG_ 331 TrlrPlcrdPrs 1;
BA_ "SignalLongName" SG_ 331 TrlrTrCnt "Trailer Tire Count";
BA_ "SignalType" SG_ 331 TrlrTrCnt "UNM";
BA_ "VNSigAllNodes" SG_ 331 TrlrTrCnt 1;
BA_ "SignalLongName" SG_ 331 TrlrTrPrsSenrIDLrnReqd "Trailer Tire Pressure Sensor ID Learn Requested";
BA_ "SignalType" SG_ 331 TrlrTrPrsSenrIDLrnReqd "BLN";
BA_ "VNSigAllNodes" SG_ 331 TrlrTrPrsSenrIDLrnReqd 1;
BA_ "SignalLongName" SG_ 331 TrlrProfSelV "Trailer Profile Selection Validity";
BA_ "SignalType" SG_ 331 TrlrProfSelV "ENM";
BA_ "VNSigAllNodes" SG_ 331 TrlrProfSelV 1;
BA_ "SignalLongName" SG_ 331 TrlrProfSel "Trailer Profile Selection";
BA_ "SignalType" SG_ 331 TrlrProfSel "ENM";
BA_ "VNSigAllNodes" SG_ 331 TrlrProfSel 1;
BA_ "SignalLongName" SG_ 1034 CRL_Cnfdnc "Curvature Right Line : Confidence";
BA_ "PacketOrder" SG_ 1034 CRL_Cnfdnc 4;
BA_ "SignalType" SG_ 1034 CRL_Cnfdnc "ENM";
BA_ "VNSigAllNodes" SG_ 1034 CRL_Cnfdnc 1;
BA_ "SignalLongName" SG_ 1034 CRL_ViewRng "Curvature Right Line : View Range";
BA_ "PacketOrder" SG_ 1034 CRL_ViewRng 3;
BA_ "SignalType" SG_ 1034 CRL_ViewRng "UNM";
BA_ "VNSigAllNodes" SG_ 1034 CRL_ViewRng 1;
BA_ "SignalLongName" SG_ 1034 CRL_CoefdA "Curvature Right Line : Coefficient dA";
BA_ "PacketOrder" SG_ 1034 CRL_CoefdA 2;
BA_ "SignalType" SG_ 1034 CRL_CoefdA "SNM";
BA_ "VNSigAllNodes" SG_ 1034 CRL_CoefdA 1;
BA_ "SignalLongName" SG_ 1034 CRL_CoefA "Curvature Right Line : Coefficient A";
BA_ "PacketOrder" SG_ 1034 CRL_CoefA 1;
BA_ "SignalType" SG_ 1034 CRL_CoefA "SNM";
BA_ "VNSigAllNodes" SG_ 1034 CRL_CoefA 1;
BA_ "SignalLongName" SG_ 1033 CLL_Cnfdnc "Curvature Left Line : Confidence";
BA_ "PacketOrder" SG_ 1033 CLL_Cnfdnc 4;
BA_ "SignalType" SG_ 1033 CLL_Cnfdnc "ENM";
BA_ "VNSigAllNodes" SG_ 1033 CLL_Cnfdnc 1;
BA_ "SignalLongName" SG_ 1033 CLL_ViewRng "Curvature Left Line : View Range";
BA_ "PacketOrder" SG_ 1033 CLL_ViewRng 3;
BA_ "SignalType" SG_ 1033 CLL_ViewRng "UNM";
BA_ "VNSigAllNodes" SG_ 1033 CLL_ViewRng 1;
BA_ "SignalLongName" SG_ 1033 CLL_CoefdA "Curvature Left Line : Coefficient dA";
BA_ "PacketOrder" SG_ 1033 CLL_CoefdA 2;
BA_ "SignalType" SG_ 1033 CLL_CoefdA "SNM";
BA_ "VNSigAllNodes" SG_ 1033 CLL_CoefdA 1;
BA_ "SignalLongName" SG_ 1033 CLL_CoefA "Curvature Left Line : Coefficient A";
BA_ "PacketOrder" SG_ 1033 CLL_CoefA 1;
BA_ "SignalType" SG_ 1033 CLL_CoefA "SNM";
BA_ "VNSigAllNodes" SG_ 1033 CLL_CoefA 1;
BA_ "SignalLongName" SG_ 1013 TrnRqHRBkCtlTgtVSpd "Transmission Requested Hill Rollback Control Target Vehicle Speed";
BA_ "SignalType" SG_ 1013 TrnRqHRBkCtlTgtVSpd "ENM";
BA_ "VNSigAllNodes" SG_ 1013 TrnRqHRBkCtlTgtVSpd 1;
BA_ "SignalLongName" SG_ 1013 TransReqHSAAval "Transmission Requested Hill Start Assist Availability";
BA_ "SignalType" SG_ 1013 TransReqHSAAval "ENM";
BA_ "VNSigAllNodes" SG_ 1013 TransReqHSAAval 1;
BA_ "SignalLongName" SG_ 1013 MtrBCoolFlwCmd "Motor B Cooling Flow Command";
BA_ "SignalType" SG_ 1013 MtrBCoolFlwCmd "UNM";
BA_ "VNSigAllNodes" SG_ 1013 MtrBCoolFlwCmd 1;
BA_ "SignalLongName" SG_ 1013 MtrACoolFlwCmd "Motor A Cooling Flow Command";
BA_ "SignalType" SG_ 1013 MtrACoolFlwCmd "UNM";
BA_ "VNSigAllNodes" SG_ 1013 MtrACoolFlwCmd 1;
BA_ "SignalLongName" SG_ 1013 ActrProcIntgSftyPtrn "Actuator Processor Integrity Safety Pattern";
BA_ "SignalType" SG_ 1013 ActrProcIntgSftyPtrn "UNM";
BA_ "VNSigAllNodes" SG_ 1013 ActrProcIntgSftyPtrn 1;
BA_ "SignalLongName" SG_ 1013 TrnsRngDiagLmtdPVal "Transmission Range Diagnostic Limited Fault Protection Value";
BA_ "SignalType" SG_ 1013 TrnsRngDiagLmtdPVal "UNM";
BA_ "VNSigAllNodes" SG_ 1013 TrnsRngDiagLmtdPVal 1;
BA_ "SignalLongName" SG_ 1013 TrnsRngDiagLmtdFltARC "Transmission Range Diagnostic Limited Fault Alive Rolling Count";
BA_ "SignalType" SG_ 1013 TrnsRngDiagLmtdFltARC "UNM";
BA_ "VNSigAllNodes" SG_ 1013 TrnsRngDiagLmtdFltARC 1;
BA_ "SignalLongName" SG_ 1013 TRDLF_TrnsFwDrvRDLFlt "Transmission Range Diagnostic Limited Fault : Transmission Forward Drive Range Diagnostic Limited Fault";
BA_ "PacketOrder" SG_ 1013 TRDLF_TrnsFwDrvRDLFlt 4;
BA_ "SignalType" SG_ 1013 TRDLF_TrnsFwDrvRDLFlt "BLN";
BA_ "VNSigAllNodes" SG_ 1013 TRDLF_TrnsFwDrvRDLFlt 1;
BA_ "SignalLongName" SG_ 1013 TRDLF_TrnsNtRgDgLtFlt "Transmission Range Diagnostic Limited Fault : Transmission Neutral Range Diagnostic Limited Fault";
BA_ "PacketOrder" SG_ 1013 TRDLF_TrnsNtRgDgLtFlt 3;
BA_ "SignalType" SG_ 1013 TRDLF_TrnsNtRgDgLtFlt "BLN";
BA_ "VNSigAllNodes" SG_ 1013 TRDLF_TrnsNtRgDgLtFlt 1;
BA_ "SignalLongName" SG_ 1013 TRDLF_TrnsRvRgDgLtFlt "Transmission Range Diagnostic Limited Fault : Transmission Reverse Range Diagnostic Limited Fault";
BA_ "PacketOrder" SG_ 1013 TRDLF_TrnsRvRgDgLtFlt 2;
BA_ "SignalType" SG_ 1013 TRDLF_TrnsRvRgDgLtFlt "BLN";
BA_ "VNSigAllNodes" SG_ 1013 TRDLF_TrnsRvRgDgLtFlt 1;
BA_ "SignalLongName" SG_ 1013 TRDLF_TrnsPkRgDgLtFlt "Transmission Range Diagnostic Limited Fault : Transmission Park Range Diagnostic Limited Fault";
BA_ "PacketOrder" SG_ 1013 TRDLF_TrnsPkRgDgLtFlt 1;
BA_ "SignalType" SG_ 1013 TRDLF_TrnsPkRgDgLtFlt "BLN";
BA_ "VNSigAllNodes" SG_ 1013 TRDLF_TrnsPkRgDgLtFlt 1;
BA_ "SignalLongName" SG_ 1013 TrnsRngDiagCrtFltPVal "Transmission Range Diagnostic Critical Fault Protection Value";
BA_ "SignalType" SG_ 1013 TrnsRngDiagCrtFltPVal "UNM";
BA_ "VNSigAllNodes" SG_ 1013 TrnsRngDiagCrtFltPVal 1;
BA_ "SignalLongName" SG_ 1013 TrnsRngDiagCrtFltARC "Transmission Range Diagnostic Critical Fault Alive Rolling Count";
BA_ "SignalType" SG_ 1013 TrnsRngDiagCrtFltARC "UNM";
BA_ "VNSigAllNodes" SG_ 1013 TrnsRngDiagCrtFltARC 1;
BA_ "SignalLongName" SG_ 1013 TRDCF_TrnsFwDrvRDCFlt "Transmission Range Diagnostic Critical Fault : Transmission Forward Drive Range Diagnostic Critical Fault";
BA_ "PacketOrder" SG_ 1013 TRDCF_TrnsFwDrvRDCFlt 4;
BA_ "SignalType" SG_ 1013 TRDCF_TrnsFwDrvRDCFlt "BLN";
BA_ "VNSigAllNodes" SG_ 1013 TRDCF_TrnsFwDrvRDCFlt 1;
BA_ "SignalLongName" SG_ 1013 TRDCF_TrnsNtRgDgCtFlt "Transmission Range Diagnostic Critical Fault : Transmission Neutral Range Diagnostic Critical Fault";
BA_ "PacketOrder" SG_ 1013 TRDCF_TrnsNtRgDgCtFlt 3;
BA_ "SignalType" SG_ 1013 TRDCF_TrnsNtRgDgCtFlt "BLN";
BA_ "VNSigAllNodes" SG_ 1013 TRDCF_TrnsNtRgDgCtFlt 1;
BA_ "SignalLongName" SG_ 1013 TRDCF_TrnsRvRgDgCtFlt "Transmission Range Diagnostic Critical Fault : Transmission Reverse Range Diagnostic Critical Fault";
BA_ "PacketOrder" SG_ 1013 TRDCF_TrnsRvRgDgCtFlt 2;
BA_ "SignalType" SG_ 1013 TRDCF_TrnsRvRgDgCtFlt "BLN";
BA_ "VNSigAllNodes" SG_ 1013 TRDCF_TrnsRvRgDgCtFlt 1;
BA_ "SignalLongName" SG_ 1013 TRDCF_TrnsPkRgDgCtFlt "Transmission Range Diagnostic Critical Fault : Transmission Park Range Diagnostic Critical Fault";
BA_ "PacketOrder" SG_ 1013 TRDCF_TrnsPkRgDgCtFlt 1;
BA_ "SignalType" SG_ 1013 TRDCF_TrnsPkRgDgCtFlt "BLN";
BA_ "VNSigAllNodes" SG_ 1013 TRDCF_TrnsPkRgDgCtFlt 1;
BA_ "SignalLongName" SG_ 170 EngCommFlrRedPwrCm "Engine Communication Failure Reduced Power Commanded";
BA_ "SignalType" SG_ 170 EngCommFlrRedPwrCm "BLN";
BA_ "VNSigAllNodes" SG_ 170 EngCommFlrRedPwrCm 1;
BA_ "SignalLongName" SG_ 170 CmndAxlTrqRespTyp "Commanded Axle Torque Response Type";
BA_ "SignalType" SG_ 170 CmndAxlTrqRespTyp "ENM";
BA_ "VNSigAllNodes" SG_ 170 CmndAxlTrqRespTyp 1;
BA_ "SignalLongName" SG_ 170 CmndAxlTrqImm "Commanded Axle Torque Immediate";
BA_ "SignalType" SG_ 170 CmndAxlTrqImm "UNM";
BA_ "VNSigAllNodes" SG_ 170 CmndAxlTrqImm 1;
BA_ "SignalLongName" SG_ 170 AccPos "Accelerator Effective Position";
BA_ "SignalType" SG_ 170 AccPos "UNM";
BA_ "VNSigAllNodes" SG_ 170 AccPos 1;
BA_ "SignalLongName" SG_ 170 CmndAxlTrqARC "Commanded Axle Torque Alive Rolling Count";
BA_ "SignalType" SG_ 170 CmndAxlTrqARC "UNM";
BA_ "VNSigAllNodes" SG_ 170 CmndAxlTrqARC 1;
BA_ "SignalLongName" SG_ 170 CmndAxlTrqPredct "Commanded Axle Torque Predicted";
BA_ "SignalType" SG_ 170 CmndAxlTrqPredct "UNM";
BA_ "VNSigAllNodes" SG_ 170 CmndAxlTrqPredct 1;
BA_ "SignalLongName" SG_ 170 CmndAxlTrqPredctProtVal "Commanded Axle Torque Predicted Protection Value";
BA_ "SignalType" SG_ 170 CmndAxlTrqPredctProtVal "UNM";
BA_ "VNSigAllNodes" SG_ 170 CmndAxlTrqPredctProtVal 1;
BA_ "SignalLongName" SG_ 647 DrvTrkModeCmnd "Driver Track Mode Commanded";
BA_ "SignalType" SG_ 647 DrvTrkModeCmnd "BLN";
BA_ "VNSigAllNodes" SG_ 647 DrvTrkModeCmnd 1;
BA_ "SignalLongName" SG_ 647 DrvCrwlModeCmnd "Driver Crawl Mode Commanded";
BA_ "SignalType" SG_ 647 DrvCrwlModeCmnd "BLN";
BA_ "VNSigAllNodes" SG_ 647 DrvCrwlModeCmnd 1;
BA_ "SignalLongName" SG_ 647 EngCntDtIntRSnsPsWdtV "Engine Controller Determined Internal Range Sensor Pulse Width Validity";
BA_ "SignalType" SG_ 647 EngCntDtIntRSnsPsWdtV "ENM";
BA_ "VNSigAllNodes" SG_ 647 EngCntDtIntRSnsPsWdtV 1;
BA_ "SignalLongName" SG_ 647 CrnksftTqModRspMxCapV "Crankshaft Torque Moderate Response Maximum Capacity Validity";
BA_ "SignalType" SG_ 647 CrnksftTqModRspMxCapV "ENM";
BA_ "VNSigAllNodes" SG_ 647 CrnksftTqModRspMxCapV 1;
BA_ "SignalLongName" SG_ 647 CrnksftTqModRspMxCap "Crankshaft Torque Moderate Response Maximum Capacity";
BA_ "SignalType" SG_ 647 CrnksftTqModRspMxCap "UNM";
BA_ "VNSigAllNodes" SG_ 647 CrnksftTqModRspMxCap 1;
BA_ "SignalLongName" SG_ 647 EngDetPndTrnCsRngShfV "Engine Determined Pending Transfer Case Range Shift Validity";
BA_ "SignalType" SG_ 647 EngDetPndTrnCsRngShfV "ENM";
BA_ "VNSigAllNodes" SG_ 647 EngDetPndTrnCsRngShfV 1;
BA_ "SignalLongName" SG_ 647 EngDetPndTrnCsRngShf "Engine Determined Pending Transfer Case Range Shift";
BA_ "SignalType" SG_ 647 EngDetPndTrnCsRngShf "ENM";
BA_ "VNSigAllNodes" SG_ 647 EngDetPndTrnCsRngShf 1;
BA_ "SignalLongName" SG_ 647 EngCntDtIntRSnsPsWdt "Engine Controller Determined Internal Range Sensor Pulse Width";
BA_ "SignalType" SG_ 647 EngCntDtIntRSnsPsWdt "UNM";
BA_ "VNSigAllNodes" SG_ 647 EngCntDtIntRSnsPsWdt 1;
BA_ "SignalLongName" SG_ 647 CrpCstCrvCmd "Creep Coast Curve Commanded";
BA_ "SignalType" SG_ 647 CrpCstCrvCmd "ENM";
BA_ "VNSigAllNodes" SG_ 647 CrpCstCrvCmd 1;
BA_ "SignalLongName" SG_ 647 DrvMntnMdCmnd "Driver Mountain Mode Commanded";
BA_ "SignalType" SG_ 647 DrvMntnMdCmnd "BLN";
BA_ "VNSigAllNodes" SG_ 647 DrvMntnMdCmnd 1;
BA_ "SignalLongName" SG_ 647 DrvHldMdCmnd "Driver Hold Mode Commanded";
BA_ "SignalType" SG_ 647 DrvHldMdCmnd "BLN";
BA_ "VNSigAllNodes" SG_ 647 DrvHldMdCmnd 1;
BA_ "SignalLongName" SG_ 647 DrPTGrdBrkDsbMdCmd "Driver Powertrain Grade Braking Disable Mode Commanded";
BA_ "SignalType" SG_ 647 DrPTGrdBrkDsbMdCmd "BLN";
BA_ "VNSigAllNodes" SG_ 647 DrPTGrdBrkDsbMdCmd 1;
BA_ "SignalLongName" SG_ 647 DrvWntrMdCmd "Driver Winter Mode Commanded";
BA_ "SignalType" SG_ 647 DrvWntrMdCmd "BLN";
BA_ "VNSigAllNodes" SG_ 647 DrvWntrMdCmd 1;
BA_ "SignalLongName" SG_ 647 DrvTwHaulMdCmd "Driver Tow Haul Mode Commanded";
BA_ "SignalType" SG_ 647 DrvTwHaulMdCmd "BLN";
BA_ "VNSigAllNodes" SG_ 647 DrvTwHaulMdCmd 1;
BA_ "SignalLongName" SG_ 647 DrvSprtMdCmd "Driver Sport Mode Commanded";
BA_ "SignalType" SG_ 647 DrvSprtMdCmd "BLN";
BA_ "VNSigAllNodes" SG_ 647 DrvSprtMdCmd 1;
BA_ "SignalLongName" SG_ 647 DrvEconMdCmd "Driver Economy Mode Commanded";
BA_ "SignalType" SG_ 647 DrvEconMdCmd "BLN";
BA_ "VNSigAllNodes" SG_ 647 DrvEconMdCmd 1;
BA_ "SignalLongName" SG_ 647 EngCntrlDtrmdTrfCRngV "Engine Controller Determined Transfer Case Range Validity";
BA_ "SignalType" SG_ 647 EngCntrlDtrmdTrfCRngV "ENM";
BA_ "VNSigAllNodes" SG_ 647 EngCntrlDtrmdTrfCRngV 1;
BA_ "SignalLongName" SG_ 647 EngCntrlDtrmdTrfCRng "Engine Controller Determined Transfer Case Range";
BA_ "SignalType" SG_ 647 EngCntrlDtrmdTrfCRng "ENM";
BA_ "VNSigAllNodes" SG_ 647 EngCntrlDtrmdTrfCRng 1;
BA_ "SignalLongName" SG_ 647 EngCtrlUtldTrnCRgPVal "Engine Controller Utilized Transfer Case Range Protection Value";
BA_ "SignalType" SG_ 647 EngCtrlUtldTrnCRgPVal "UNM";
BA_ "VNSigAllNodes" SG_ 647 EngCtrlUtldTrnCRgPVal 1;
BA_ "SignalLongName" SG_ 647 EngCntrlUtldTrnCsRng "Engine Controller Utilized Transfer Case Range";
BA_ "SignalType" SG_ 647 EngCntrlUtldTrnCsRng "ENM";
BA_ "VNSigAllNodes" SG_ 647 EngCntrlUtldTrnCsRng 1;
BA_ "SignalLongName" SG_ 647 EngCntrlUtldTrnCsRgIn "Engine Controller Utilized Transfer Case Range Inconsistent";
BA_ "SignalType" SG_ 647 EngCntrlUtldTrnCsRgIn "BLN";
BA_ "VNSigAllNodes" SG_ 647 EngCntrlUtldTrnCsRgIn 1;
BA_ "SignalLongName" SG_ 647 EngCtrlUtldTrnCRgARC "Engine Controller Utilized Transfer Case Range Alive Rolling Count";
BA_ "SignalType" SG_ 647 EngCtrlUtldTrnCRgARC "UNM";
BA_ "VNSigAllNodes" SG_ 647 EngCtrlUtldTrnCRgARC 1;
BA_ "SignalLongName" SG_ 199 TORSTimestamp "Transmission Output Rotational Status : Transmission Output Rotational Status Timestamp";
BA_ "PacketOrder" SG_ 199 TORSTimestamp 6;
BA_ "SignalType" SG_ 199 TORSTimestamp "UNM";
BA_ "VNSigAllNodes" SG_ 199 TORSTimestamp 1;
BA_ "SignalLongName" SG_ 199 TORSPulsCntr "Transmission Output Rotational Status : Transmission Output Rotational Status Pulse Counter";
BA_ "PacketOrder" SG_ 199 TORSPulsCntr 5;
BA_ "SignalType" SG_ 199 TORSPulsCntr "UNM";
BA_ "VNSigAllNodes" SG_ 199 TORSPulsCntr 1;
BA_ "SignalLongName" SG_ 199 TORSValidity "Transmission Output Rotational Status : Transmission Output Rotational Status Validity";
BA_ "PacketOrder" SG_ 199 TORSValidity 4;
BA_ "SignalType" SG_ 199 TORSValidity "ENM";
BA_ "VNSigAllNodes" SG_ 199 TORSValidity 1;
BA_ "SignalLongName" SG_ 199 TORSRstOcrd "Transmission Output Rotational Status : Transmission Output Rotational Status Reset Occurred";
BA_ "PacketOrder" SG_ 199 TORSRstOcrd 3;
BA_ "SignalType" SG_ 199 TORSRstOcrd "BLN";
BA_ "VNSigAllNodes" SG_ 199 TORSRstOcrd 1;
BA_ "SignalLongName" SG_ 199 TORSLstTransType "Transmission Output Rotational Status : Transmission Output Rotational Status Last Transition Type";
BA_ "PacketOrder" SG_ 199 TORSLstTransType 2;
BA_ "SignalType" SG_ 199 TORSLstTransType "ENM";
BA_ "VNSigAllNodes" SG_ 199 TORSLstTransType 1;
BA_ "SignalLongName" SG_ 199 TORSRotDir "Transmission Output Rotational Status : Transmission Output Rotational Status Rotation Direction";
BA_ "PacketOrder" SG_ 199 TORSRotDir 1;
BA_ "SignalType" SG_ 199 TORSRotDir "ENM";
BA_ "VNSigAllNodes" SG_ 199 TORSRotDir 1;
BA_ "SignalLongName" SG_ 190 EngSpdMaxCapRdcdRng "Engine Speed Maximum Capacity Reduced Range";
BA_ "SignalType" SG_ 190 EngSpdMaxCapRdcdRng "UNM";
BA_ "VNSigAllNodes" SG_ 190 EngSpdMaxCapRdcdRng 1;
BA_ "SignalLongName" SG_ 190 TrnsAuxPmpAct "Transmission Auxiliary Pump Active";
BA_ "SignalType" SG_ 190 TrnsAuxPmpAct "BLN";
BA_ "VNSigAllNodes" SG_ 190 TrnsAuxPmpAct 1;
BA_ "SignalLongName" SG_ 190 AccPos "Accelerator Effective Position";
BA_ "SignalType" SG_ 190 AccPos "UNM";
BA_ "VNSigAllNodes" SG_ 190 AccPos 1;
BA_ "SignalLongName" SG_ 190 PTSnsdBrkPdlInfPVal "Powertrain Sensed Brake Pedal Information Protection Value";
BA_ "SignalType" SG_ 190 PTSnsdBrkPdlInfPVal "UNM";
BA_ "VNSigAllNodes" SG_ 190 PTSnsdBrkPdlInfPVal 1;
BA_ "SignalLongName" SG_ 190 PTSnsdBrkPdlInfARC "Powertrain Sensed Brake Pedal Information Alive Rolling Count";
BA_ "SignalType" SG_ 190 PTSnsdBrkPdlInfARC "UNM";
BA_ "VNSigAllNodes" SG_ 190 PTSnsdBrkPdlInfARC 1;
BA_ "SignalLongName" SG_ 190 PSBPI_PTSnBrkPdlPsV "Powertrain Sensed Brake Pedal Information : Powertrain Sensed Brake Pedal Position Validity";
BA_ "PacketOrder" SG_ 190 PSBPI_PTSnBrkPdlPsV 1;
BA_ "SignalType" SG_ 190 PSBPI_PTSnBrkPdlPsV "ENM";
BA_ "VNSigAllNodes" SG_ 190 PSBPI_PTSnBrkPdlPsV 1;
BA_ "SignalLongName" SG_ 190 PSBPI_PTSnBrkPdlPs "Powertrain Sensed Brake Pedal Information : Powertrain Sensed Brake Pedal Position";
BA_ "PacketOrder" SG_ 190 PSBPI_PTSnBrkPdlPs 2;
BA_ "SignalType" SG_ 190 PSBPI_PTSnBrkPdlPs "UNM";
BA_ "VNSigAllNodes" SG_ 190 PSBPI_PTSnBrkPdlPs 1;
BA_ "SignalLongName" SG_ 579 DgnInf "Diagnostic Information";
BA_ "SignalType" SG_ 579 DgnInf "UNM";
BA_ "VNSigSLHSSharedDiagnostic" SG_ 579 DgnInf 1;
BA_ "VNSigAllNodes" SG_ 579 DgnInf 1;
BA_ "GenSigDeltaValue" SG_ 579 DgnInf 1;
BA_ "GenSigSendType" SG_ 579 DgnInf 12;
BA_ "SignalLongName" SG_ 707 CSTATRS_ReqStat "Chassis System Total Axle Torque Request Status : Request Status";
BA_ "PacketOrder" SG_ 707 CSTATRS_ReqStat 2;
BA_ "SignalType" SG_ 707 CSTATRS_ReqStat "ENM";
BA_ "VNSigAllNodes" SG_ 707 CSTATRS_ReqStat 1;
BA_ "SignalLongName" SG_ 707 CSTATRS_LmtgStat "Chassis System Total Axle Torque Request Status : Limiting Status";
BA_ "PacketOrder" SG_ 707 CSTATRS_LmtgStat 1;
BA_ "SignalType" SG_ 707 CSTATRS_LmtgStat "ENM";
BA_ "VNSigAllNodes" SG_ 707 CSTATRS_LmtgStat 1;
BA_ "SignalLongName" SG_ 707 EngManfldAbsPrsV "Engine Manifold Absolute Pressure Validity";
BA_ "SignalType" SG_ 707 EngManfldAbsPrsV "ENM";
BA_ "VNSigAllNodes" SG_ 707 EngManfldAbsPrsV 1;
BA_ "SignalLongName" SG_ 707 EngManfldAbsPrs "Engine Manifold Absolute Pressure";
BA_ "SignalType" SG_ 707 EngManfldAbsPrs "UNM";
BA_ "VNSigAllNodes" SG_ 707 EngManfldAbsPrs 1;
BA_ "SignalLongName" SG_ 707 EngTrqMinExtRngV "Engine Torque Minimum Extended Range Validity";
BA_ "SignalType" SG_ 707 EngTrqMinExtRngV "ENM";
BA_ "VNSigAllNodes" SG_ 707 EngTrqMinExtRngV 1;
BA_ "GenSigStartValue" SG_ 707 EngTrqMinExtRng 1696;
BA_ "SignalLongName" SG_ 707 EngTrqMinExtRng "Engine Torque Minimum Extended Range";
BA_ "SignalType" SG_ 707 EngTrqMinExtRng "UNM";
BA_ "VNSigAllNodes" SG_ 707 EngTrqMinExtRng 1;
BA_ "SignalLongName" SG_ 707 EngTrqMaxExtRngV "Engine Torque Maximum Extended Range Validity";
BA_ "SignalType" SG_ 707 EngTrqMaxExtRngV "ENM";
BA_ "VNSigAllNodes" SG_ 707 EngTrqMaxExtRngV 1;
BA_ "GenSigStartValue" SG_ 707 EngTrqMaxExtRng 1696;
BA_ "SignalLongName" SG_ 707 EngTrqMaxExtRng "Engine Torque Maximum Extended Range";
BA_ "SignalType" SG_ 707 EngTrqMaxExtRng "UNM";
BA_ "VNSigAllNodes" SG_ 707 EngTrqMaxExtRng 1;
BA_ "SignalLongName" SG_ 249 TrnsDrvlneTqShpDisRq "Transmission Driveline Torque Shaping Disable Requested";
BA_ "SignalType" SG_ 249 TrnsDrvlneTqShpDisRq "BLN";
BA_ "VNSigAllNodes" SG_ 249 TrnsDrvlneTqShpDisRq 1;
BA_ "SignalLongName" SG_ 249 TnCCVehSpShftEvTh "Transmission Cruise Control Vehicle Speed Shift Event Threshold";
BA_ "SignalType" SG_ 249 TnCCVehSpShftEvTh "UNM";
BA_ "VNSigAllNodes" SG_ 249 TnCCVehSpShftEvTh 1;
BA_ "SignalLongName" SG_ 249 TrnsOtptShftAngVelSnrPr "Transmission Output Shaft Angular Velocity Sensor Present";
BA_ "SignalType" SG_ 249 TrnsOtptShftAngVelSnrPr "BLN";
BA_ "VNSigAllNodes" SG_ 249 TrnsOtptShftAngVelSnrPr 1;
BA_ "SignalLongName" SG_ 249 TrnsRqHSABrkPrDcyRt "Transmission Requested Hill Start Assist Brake Pressure Decay Rate";
BA_ "SignalType" SG_ 249 TrnsRqHSABrkPrDcyRt "ENM";
BA_ "VNSigAllNodes" SG_ 249 TrnsRqHSABrkPrDcyRt 1;
BA_ "SignalLongName" SG_ 249 TrnsOtptRotRC "Transmission Output Rotations Rolling Count";
BA_ "SignalType" SG_ 249 TrnsOtptRotRC "UNM";
BA_ "VNSigAllNodes" SG_ 249 TrnsOtptRotRC 1;
BA_ "SignalLongName" SG_ 249 TrnsOtptRotRCRstOcc "Transmission Output Rotations Rolling Count Reset Occurred";
BA_ "SignalType" SG_ 249 TrnsOtptRotRCRstOcc "BLN";
BA_ "VNSigAllNodes" SG_ 249 TrnsOtptRotRCRstOcc 1;
BA_ "SignalLongName" SG_ 249 TrnsOtptRotRCV "Transmission Output Rotations Rolling Count Validity";
BA_ "SignalType" SG_ 249 TrnsOtptRotRCV "ENM";
BA_ "VNSigAllNodes" SG_ 249 TrnsOtptRotRCV 1;
BA_ "SignalLongName" SG_ 249 TrnsOutShftAngVel "Transmission Output Shaft Angular Velocity";
BA_ "SignalType" SG_ 249 TrnsOutShftAngVel "UNM";
BA_ "VNSigAllNodes" SG_ 249 TrnsOutShftAngVel 1;
BA_ "SignalLongName" SG_ 249 TrnsOutShftAngVelV "Transmission Output Shaft Angular Velocity Validity";
BA_ "SignalType" SG_ 249 TrnsOutShftAngVelV "ENM";
BA_ "VNSigAllNodes" SG_ 249 TrnsOutShftAngVelV 1;
BA_ "SignalLongName" SG_ 249 TrnsOvrallEstTorqRatio "Transmission Overall Estimated Torque Ratio";
BA_ "SignalType" SG_ 249 TrnsOvrallEstTorqRatio "SNM";
BA_ "VNSigAllNodes" SG_ 249 TrnsOvrallEstTorqRatio 1;
BA_ "SignalLongName" SG_ 249 TrnsOvrallEstTorqRatioV "Transmission Overall Estimated Torque Ratio Validity";
BA_ "SignalType" SG_ 249 TrnsOvrallEstTorqRatioV "ENM";
BA_ "VNSigAllNodes" SG_ 249 TrnsOvrallEstTorqRatioV 1;
BA_ "SignalLongName" SG_ 1273 BrkSyCtl1EmsRldMlfAct "Brake System Control 1 Emissions Related Malfunction Active";
BA_ "SignalType" SG_ 1273 BrkSyCtl1EmsRldMlfAct "BLN";
BA_ "VNSigAllNodes" SG_ 1273 BrkSyCtl1EmsRldMlfAct 1;
BA_ "SignalLongName" SG_ 1273 BSC1ERDTC_CdNum "Brake System Control 1 Emissions Related DTC : Code Number";
BA_ "PacketOrder" SG_ 1273 BSC1ERDTC_CdNum 2;
BA_ "SignalType" SG_ 1273 BSC1ERDTC_CdNum "UNM";
BA_ "VNSigAllNodes" SG_ 1273 BSC1ERDTC_CdNum 1;
BA_ "SignalLongName" SG_ 1273 BSC1ERDTC_SysDes "Brake System Control 1 Emissions Related DTC : System Designator";
BA_ "PacketOrder" SG_ 1273 BSC1ERDTC_SysDes 1;
BA_ "SignalType" SG_ 1273 BSC1ERDTC_SysDes "ENM";
BA_ "VNSigAllNodes" SG_ 1273 BSC1ERDTC_SysDes 1;
BA_ "GenSigStartValue" SG_ 208 WhlSlipRRWhl 32768;
BA_ "SignalLongName" SG_ 208 WhlSlipRRWhl "Wheel Slip Right Rear Wheel";
BA_ "SignalType" SG_ 208 WhlSlipRRWhl "UNM";
BA_ "VNSigAllNodes" SG_ 208 WhlSlipRRWhl 1;
BA_ "GenSigStartValue" SG_ 208 WhlSlipRFWhl 32768;
BA_ "SignalLongName" SG_ 208 WhlSlipRFWhl "Wheel Slip Right Front Wheel";
BA_ "SignalType" SG_ 208 WhlSlipRFWhl "UNM";
BA_ "VNSigAllNodes" SG_ 208 WhlSlipRFWhl 1;
BA_ "GenSigStartValue" SG_ 208 WhlSlipLRWhl 32768;
BA_ "SignalLongName" SG_ 208 WhlSlipLRWhl "Wheel Slip Left Rear Wheel";
BA_ "SignalType" SG_ 208 WhlSlipLRWhl "UNM";
BA_ "VNSigAllNodes" SG_ 208 WhlSlipLRWhl 1;
BA_ "GenSigStartValue" SG_ 208 WhlSlipLFWhl 32768;
BA_ "SignalLongName" SG_ 208 WhlSlipLFWhl "Wheel Slip Left Front Wheel";
BA_ "SignalType" SG_ 208 WhlSlipLFWhl "UNM";
BA_ "VNSigAllNodes" SG_ 208 WhlSlipLFWhl 1;
BA_ "SignalLongName" SG_ 753 EBCMDS5_DTCStatus "Electronic Brake Control Module Diagnostic Status 5 : Diagnostic Trouble Code Status";
BA_ "PacketOrder" SG_ 753 EBCMDS5_DTCStatus 2;
BA_ "SignalType" SG_ 753 EBCMDS5_DTCStatus "ENM";
BA_ "VNSigAllNodes" SG_ 753 EBCMDS5_DTCStatus 1;
BA_ "SignalLongName" SG_ 753 EBCMDS5_DTCIndex "Electronic Brake Control Module Diagnostic Status 5 : Diagnostic Trouble Code Index";
BA_ "PacketOrder" SG_ 753 EBCMDS5_DTCIndex 1;
BA_ "SignalType" SG_ 753 EBCMDS5_DTCIndex "UNM";
BA_ "VNSigAllNodes" SG_ 753 EBCMDS5_DTCIndex 1;
BA_ "SignalLongName" SG_ 753 EBCMDS4_DTCStatus "Electronic Brake Control Module Diagnostic Status 4 : Diagnostic Trouble Code Status";
BA_ "PacketOrder" SG_ 753 EBCMDS4_DTCStatus 2;
BA_ "SignalType" SG_ 753 EBCMDS4_DTCStatus "ENM";
BA_ "VNSigAllNodes" SG_ 753 EBCMDS4_DTCStatus 1;
BA_ "SignalLongName" SG_ 753 EBCMDS4_DTCIndex "Electronic Brake Control Module Diagnostic Status 4 : Diagnostic Trouble Code Index";
BA_ "PacketOrder" SG_ 753 EBCMDS4_DTCIndex 1;
BA_ "SignalType" SG_ 753 EBCMDS4_DTCIndex "UNM";
BA_ "VNSigAllNodes" SG_ 753 EBCMDS4_DTCIndex 1;
BA_ "SignalLongName" SG_ 753 EBCMDS3_DTCStatus "Electronic Brake Control Module Diagnostic Status 3 : Diagnostic Trouble Code Status";
BA_ "PacketOrder" SG_ 753 EBCMDS3_DTCStatus 2;
BA_ "SignalType" SG_ 753 EBCMDS3_DTCStatus "ENM";
BA_ "VNSigAllNodes" SG_ 753 EBCMDS3_DTCStatus 1;
BA_ "SignalLongName" SG_ 753 EBCMDS3_DTCIndex "Electronic Brake Control Module Diagnostic Status 3 : Diagnostic Trouble Code Index";
BA_ "PacketOrder" SG_ 753 EBCMDS3_DTCIndex 1;
BA_ "SignalType" SG_ 753 EBCMDS3_DTCIndex "UNM";
BA_ "VNSigAllNodes" SG_ 753 EBCMDS3_DTCIndex 1;
BA_ "SignalLongName" SG_ 753 EBCMDS2_DTCStatus "Electronic Brake Control Module Diagnostic Status 2 : Diagnostic Trouble Code Status";
BA_ "PacketOrder" SG_ 753 EBCMDS2_DTCStatus 2;
BA_ "SignalType" SG_ 753 EBCMDS2_DTCStatus "ENM";
BA_ "VNSigAllNodes" SG_ 753 EBCMDS2_DTCStatus 1;
BA_ "SignalLongName" SG_ 753 EBCMDS2_DTCIndex "Electronic Brake Control Module Diagnostic Status 2 : Diagnostic Trouble Code Index";
BA_ "PacketOrder" SG_ 753 EBCMDS2_DTCIndex 1;
BA_ "SignalType" SG_ 753 EBCMDS2_DTCIndex "UNM";
BA_ "VNSigAllNodes" SG_ 753 EBCMDS2_DTCIndex 1;
BA_ "SignalLongName" SG_ 753 EBCMDS1_DTCStatus "Electronic Brake Control Module Diagnostic Status 1 : Diagnostic Trouble Code Status";
BA_ "PacketOrder" SG_ 753 EBCMDS1_DTCStatus 2;
BA_ "SignalType" SG_ 753 EBCMDS1_DTCStatus "ENM";
BA_ "VNSigAllNodes" SG_ 753 EBCMDS1_DTCStatus 1;
BA_ "SignalLongName" SG_ 753 EBCMDS1_DTCIndex "Electronic Brake Control Module Diagnostic Status 1 : Diagnostic Trouble Code Index";
BA_ "PacketOrder" SG_ 753 EBCMDS1_DTCIndex 1;
BA_ "SignalType" SG_ 753 EBCMDS1_DTCIndex "UNM";
BA_ "VNSigAllNodes" SG_ 753 EBCMDS1_DTCIndex 1;
BA_ "SignalLongName" SG_ 508 LonLatAccSnsChk "Longitudinal/Lateral Acceleration Sensor Checksum";
BA_ "SignalType" SG_ 508 LonLatAccSnsChk "UNM";
BA_ "VNSigAllNodes" SG_ 508 LonLatAccSnsChk 1;
BA_ "SignalLongName" SG_ 508 LonLatAccSnsValARC "Longitudinal/Lateral Acceleration Sensor Value Alive Rolling Count";
BA_ "SignalType" SG_ 508 LonLatAccSnsValARC "UNM";
BA_ "VNSigAllNodes" SG_ 508 LonLatAccSnsValARC 1;
BA_ "SignalLongName" SG_ 508 LatAccSnsVal "Lateral Acceleration Sensor Value";
BA_ "SignalType" SG_ 508 LatAccSnsVal "SNM";
BA_ "VNSigAllNodes" SG_ 508 LatAccSnsVal 1;
BA_ "SignalLongName" SG_ 508 LonAccSnsVal "Longitudinal Acceleration Sensor Value";
BA_ "SignalType" SG_ 508 LonAccSnsVal "SNM";
BA_ "VNSigAllNodes" SG_ 508 LonAccSnsVal 1;
BA_ "SignalLongName" SG_ 508 ChsSysTtlBkAxlTqStARC "Chassis System Total Brake Axle Torque Status Alive Rolling Count";
BA_ "SignalType" SG_ 508 ChsSysTtlBkAxlTqStARC "UNM";
BA_ "VNSigAllNodes" SG_ 508 ChsSysTtlBkAxlTqStARC 1;
BA_ "SignalLongName" SG_ 508 CSTBATS_TrqVl "Chassis System Total Brake Axle Torque Status : Torque Value";
BA_ "PacketOrder" SG_ 508 CSTBATS_TrqVl 2;
BA_ "SignalType" SG_ 508 CSTBATS_TrqVl "UNM";
BA_ "VNSigAllNodes" SG_ 508 CSTBATS_TrqVl 1;
BA_ "SignalLongName" SG_ 508 CSTBATS_TrqVlV "Chassis System Total Brake Axle Torque Status : Torque Value Validity";
BA_ "PacketOrder" SG_ 508 CSTBATS_TrqVlV 1;
BA_ "SignalType" SG_ 508 CSTBATS_TrqVlV "ENM";
BA_ "VNSigAllNodes" SG_ 508 CSTBATS_TrqVlV 1;
BA_ "SignalLongName" SG_ 454 APAAxlTrqRdctnAct "Advanced Park Assist Axle Torque Reduction Active";
BA_ "SignalType" SG_ 454 APAAxlTrqRdctnAct "BLN";
BA_ "VNSigAllNodes" SG_ 454 APAAxlTrqRdctnAct 1;
BA_ "SignalLongName" SG_ 454 ChsSysPrdAxlTqRqPV "Chassis System Predicted Axle Torque Request Protection Value";
BA_ "SignalType" SG_ 454 ChsSysPrdAxlTqRqPV "UNM";
BA_ "VNSigAllNodes" SG_ 454 ChsSysPrdAxlTqRqPV 1;
BA_ "SignalLongName" SG_ 454 CSPATR_TrqIntrvnTyp "Chassis System Predicted Axle Torque Request : Torque Intervention Type";
BA_ "PacketOrder" SG_ 454 CSPATR_TrqIntrvnTyp 3;
BA_ "SignalType" SG_ 454 CSPATR_TrqIntrvnTyp "ENM";
BA_ "VNSigAllNodes" SG_ 454 CSPATR_TrqIntrvnTyp 1;
BA_ "SignalLongName" SG_ 454 CSPATR_PrdTrqRqVal "Chassis System Predicted Axle Torque Request : Predicted Torque Request Value";
BA_ "PacketOrder" SG_ 454 CSPATR_PrdTrqRqVal 2;
BA_ "SignalType" SG_ 454 CSPATR_PrdTrqRqVal "UNM";
BA_ "VNSigAllNodes" SG_ 454 CSPATR_PrdTrqRqVal 1;
BA_ "SignalLongName" SG_ 454 CSPATR_TrqRqTyp "Chassis System Predicted Axle Torque Request : Torque Request Type";
BA_ "PacketOrder" SG_ 454 CSPATR_TrqRqTyp 1;
BA_ "SignalType" SG_ 454 CSPATR_TrqRqTyp "ENM";
BA_ "VNSigAllNodes" SG_ 454 CSPATR_TrqRqTyp 1;
BA_ "SignalLongName" SG_ 454 ChsSysImmAxlTqRqVal "Chassis System Immediate Axle Torque Request Value";
BA_ "SignalType" SG_ 454 ChsSysImmAxlTqRqVal "UNM";
BA_ "VNSigAllNodes" SG_ 454 ChsSysImmAxlTqRqVal 1;
BA_ "SignalLongName" SG_ 454 ChsSysAxlTqRqRspTyp "Chassis System Axle Torque Request Response Type";
BA_ "SignalType" SG_ 454 ChsSysAxlTqRqRspTyp "ENM";
BA_ "VNSigAllNodes" SG_ 454 ChsSysAxlTqRqRspTyp 1;
BA_ "SignalLongName" SG_ 454 ChsSysPrdAxlTqRqARC "Chassis System Predicted Axle Torque Request Alive Rolling Count";
BA_ "SignalType" SG_ 454 ChsSysPrdAxlTqRqARC "UNM";
BA_ "VNSigAllNodes" SG_ 454 ChsSysPrdAxlTqRqARC 1;
BA_ "SignalLongName" SG_ 554 BrkSysVTopSpdLimRqTpPVal "Braking System Vehicle Top Speed Limit Request Type Protection Value";
BA_ "SignalType" SG_ 554 BrkSysVTopSpdLimRqTpPVal "UNM";
BA_ "VNSigAllNodes" SG_ 554 BrkSysVTopSpdLimRqTpPVal 1;
BA_ "SignalLongName" SG_ 554 BrkSysVTopSpdLimRqTpARC "Braking System Vehicle Top Speed Limit Request Type Alive Rolling Count";
BA_ "SignalType" SG_ 554 BrkSysVTopSpdLimRqTpARC "UNM";
BA_ "VNSigAllNodes" SG_ 554 BrkSysVTopSpdLimRqTpARC 1;
BA_ "SignalLongName" SG_ 554 BrkSysVTopSpdLimRqTp "Braking System Vehicle Top Speed Limit Request Type";
BA_ "SignalType" SG_ 554 BrkSysVTopSpdLimRqTp "ENM";
BA_ "VNSigAllNodes" SG_ 554 BrkSysVTopSpdLimRqTp 1;
BA_ "SignalLongName" SG_ 554 PrtdEPBSwStatPortVal "Protected Electric Park Brake Switch Status Protection Value";
BA_ "SignalType" SG_ 554 PrtdEPBSwStatPortVal "UNM";
BA_ "VNSigAllNodes" SG_ 554 PrtdEPBSwStatPortVal 1;
BA_ "SignalLongName" SG_ 554 PrtdEPBSwStatARC "Protected Electric Park Brake Switch Status Alive Rolling Count";
BA_ "SignalType" SG_ 554 PrtdEPBSwStatARC "UNM";
BA_ "VNSigAllNodes" SG_ 554 PrtdEPBSwStatARC 1;
BA_ "SignalLongName" SG_ 554 PrtdEPBSwStat "Protected Electric Park Brake Switch Status";
BA_ "SignalType" SG_ 554 PrtdEPBSwStat "ENM";
BA_ "VNSigAllNodes" SG_ 554 PrtdEPBSwStat 1;
BA_ "SignalLongName" SG_ 554 ElecPrkBrkApplStatPV "Electric Park Brake Application Status Protection Value";
BA_ "SignalType" SG_ 554 ElecPrkBrkApplStatPV "UNM";
BA_ "VNSigAllNodes" SG_ 554 ElecPrkBrkApplStatPV 1;
BA_ "SignalLongName" SG_ 554 ElecPrkBrkAvailStatPV "Electric Park Brake Availability Status Protection Value";
BA_ "SignalType" SG_ 554 ElecPrkBrkAvailStatPV "UNM";
BA_ "VNSigAllNodes" SG_ 554 ElecPrkBrkAvailStatPV 1;
BA_ "SignalLongName" SG_ 554 ElecPrkBrkAvailStat "Electric Park Brake Availability Status";
BA_ "SignalType" SG_ 554 ElecPrkBrkAvailStat "ENM";
BA_ "VNSigAllNodes" SG_ 554 ElecPrkBrkAvailStat 1;
BA_ "SignalLongName" SG_ 554 ElecPrkBrkStatRC "Electric Park Brake Status Rolling Count";
BA_ "SignalType" SG_ 554 ElecPrkBrkStatRC "UNM";
BA_ "VNSigAllNodes" SG_ 554 ElecPrkBrkStatRC 1;
BA_ "SignalLongName" SG_ 554 ElecPrkBrkApplStat "Electric Park Brake Application Status";
BA_ "SignalType" SG_ 554 ElecPrkBrkApplStat "ENM";
BA_ "VNSigAllNodes" SG_ 554 ElecPrkBrkApplStat 1;
BA_ "SignalLongName" SG_ 462 SecAxlLkTqRqCplRqTp "Secondary Axle Locking Torque Request Coupling Request Type";
BA_ "SignalType" SG_ 462 SecAxlLkTqRqCplRqTp "ENM";
BA_ "VNSigAllNodes" SG_ 462 SecAxlLkTqRqCplRqTp 1;
BA_ "SignalLongName" SG_ 462 SecAxlTrqReqProtVal "Secondary Axle Torque Request Protection Value";
BA_ "SignalType" SG_ 462 SecAxlTrqReqProtVal "UNM";
BA_ "VNSigAllNodes" SG_ 462 SecAxlTrqReqProtVal 1;
BA_ "SignalLongName" SG_ 462 SecAxlTrqReqARollCnt "Secondary Axle Torque Request Alive Rolling Count";
BA_ "SignalType" SG_ 462 SecAxlTrqReqARollCnt "UNM";
BA_ "VNSigAllNodes" SG_ 462 SecAxlTrqReqARollCnt 1;
BA_ "SignalLongName" SG_ 462 SATRCplReqVal "Secondary Axle Torque Request : Coupling Request Value";
BA_ "PacketOrder" SG_ 462 SATRCplReqVal 2;
BA_ "SignalType" SG_ 462 SATRCplReqVal "UNM";
BA_ "VNSigAllNodes" SG_ 462 SATRCplReqVal 1;
BA_ "SignalLongName" SG_ 462 SATRCplReqAtv "Secondary Axle Torque Request : Coupling Request Active";
BA_ "PacketOrder" SG_ 462 SATRCplReqAtv 1;
BA_ "SignalType" SG_ 462 SATRCplReqAtv "BLN";
BA_ "VNSigAllNodes" SG_ 462 SATRCplReqAtv 1;
BA_ "SignalLongName" SG_ 510 BPSUD_MsCyPrSnsSUpVal "Brake Pressure Sensor Unprocessed Data : Master Cylinder Pressure Sensor Supply Unprocessed Value";
BA_ "PacketOrder" SG_ 510 BPSUD_MsCyPrSnsSUpVal 3;
BA_ "SignalType" SG_ 510 BPSUD_MsCyPrSnsSUpVal "UNM";
BA_ "VNSigAllNodes" SG_ 510 BPSUD_MsCyPrSnsSUpVal 1;
BA_ "SignalLongName" SG_ 510 BPSUD_MsCyPrSns2UpVal "Brake Pressure Sensor Unprocessed Data : Master Cylinder Pressure Sensor 2 Unprocessed Value";
BA_ "PacketOrder" SG_ 510 BPSUD_MsCyPrSns2UpVal 2;
BA_ "SignalType" SG_ 510 BPSUD_MsCyPrSns2UpVal "UNM";
BA_ "VNSigAllNodes" SG_ 510 BPSUD_MsCyPrSns2UpVal 1;
BA_ "SignalLongName" SG_ 510 BPSUD_MsCyPrSns1UpVal "Brake Pressure Sensor Unprocessed Data : Master Cylinder Pressure Sensor 1 Unprocessed Value";
BA_ "PacketOrder" SG_ 510 BPSUD_MsCyPrSns1UpVal 1;
BA_ "SignalType" SG_ 510 BPSUD_MsCyPrSns1UpVal "UNM";
BA_ "VNSigAllNodes" SG_ 510 BPSUD_MsCyPrSns1UpVal 1;
BA_ "SignalLongName" SG_ 510 BrkPresSnsrDataChksm "Brake Pressure Sensor Data Checksum";
BA_ "SignalType" SG_ 510 BrkPresSnsrDataChksm "UNM";
BA_ "VNSigAllNodes" SG_ 510 BrkPresSnsrDataChksm 1;
BA_ "SignalLongName" SG_ 510 BrkPresSnsrDataARC "Brake Pressure Sensor Data Alive Rolling Count";
BA_ "SignalType" SG_ 510 BrkPresSnsrDataARC "UNM";
BA_ "VNSigAllNodes" SG_ 510 BrkPresSnsrDataARC 1;
BA_ "SignalLongName" SG_ 1920 DTCI_CurrentStatus_780 "Diagnostic Trouble Code Information Extended 780 : Current Status";
BA_ "PacketOrder" SG_ 1920 DTCI_CurrentStatus_780 18;
BA_ "SignalType" SG_ 1920 DTCI_CurrentStatus_780 "BLN";
BA_ "VNSigAllNodes" SG_ 1920 DTCI_CurrentStatus_780 1;
BA_ "SignalLongName" SG_ 1920 DTCI_WrnIndRqdSt_780 "Diagnostic Trouble Code Information Extended 780 : Warning Indicator Requested Status";
BA_ "PacketOrder" SG_ 1920 DTCI_WrnIndRqdSt_780 12;
BA_ "SignalType" SG_ 1920 DTCI_WrnIndRqdSt_780 "BLN";
BA_ "VNSigAllNodes" SG_ 1920 DTCI_WrnIndRqdSt_780 1;
BA_ "SignalLongName" SG_ 1920 DTCIUnused7_780 "Diagnostic Trouble Code Information Extended 780 : Unused 7";
BA_ "PacketOrder" SG_ 1920 DTCIUnused7_780 7;
BA_ "SignalType" SG_ 1920 DTCIUnused7_780 "BLN";
BA_ "VNSigAllNodes" SG_ 1920 DTCIUnused7_780 1;
BA_ "SignalLongName" SG_ 1920 DTCIUnused6_780 "Diagnostic Trouble Code Information Extended 780 : Unused 6";
BA_ "PacketOrder" SG_ 1920 DTCIUnused6_780 6;
BA_ "SignalType" SG_ 1920 DTCIUnused6_780 "BLN";
BA_ "VNSigAllNodes" SG_ 1920 DTCIUnused6_780 1;
BA_ "SignalLongName" SG_ 1920 DTCIUnused5_780 "Diagnostic Trouble Code Information Extended 780 : Unused 5";
BA_ "PacketOrder" SG_ 1920 DTCIUnused5_780 5;
BA_ "SignalType" SG_ 1920 DTCIUnused5_780 "BLN";
BA_ "VNSigAllNodes" SG_ 1920 DTCIUnused5_780 1;
BA_ "SignalLongName" SG_ 1920 DTCIUnused4_780 "Diagnostic Trouble Code Information Extended 780 : Unused 4";
BA_ "PacketOrder" SG_ 1920 DTCIUnused4_780 4;
BA_ "SignalType" SG_ 1920 DTCIUnused4_780 "BLN";
BA_ "VNSigAllNodes" SG_ 1920 DTCIUnused4_780 1;
BA_ "SignalLongName" SG_ 1920 DTCIUnused3_780 "Diagnostic Trouble Code Information Extended 780 : Unused 3";
BA_ "PacketOrder" SG_ 1920 DTCIUnused3_780 3;
BA_ "SignalType" SG_ 1920 DTCIUnused3_780 "BLN";
BA_ "VNSigAllNodes" SG_ 1920 DTCIUnused3_780 1;
BA_ "SignalLongName" SG_ 1920 DTCIUnused2_780 "Diagnostic Trouble Code Information Extended 780 : Unused 2";
BA_ "PacketOrder" SG_ 1920 DTCIUnused2_780 2;
BA_ "SignalType" SG_ 1920 DTCIUnused2_780 "BLN";
BA_ "VNSigAllNodes" SG_ 1920 DTCIUnused2_780 1;
BA_ "SignalLongName" SG_ 1920 DTCIUnused1_780 "Diagnostic Trouble Code Information Extended 780 : Unused 1";
BA_ "PacketOrder" SG_ 1920 DTCIUnused1_780 1;
BA_ "SignalType" SG_ 1920 DTCIUnused1_780 "BLN";
BA_ "VNSigAllNodes" SG_ 1920 DTCIUnused1_780 1;
BA_ "SignalLongName" SG_ 1920 DTCI_TstNPsdPwrUpSt_780 "Diagnostic Trouble Code Information Extended 780 : Test Not Passed Since Power Up Status";
BA_ "PacketOrder" SG_ 1920 DTCI_TstNPsdPwrUpSt_780 14;
BA_ "SignalType" SG_ 1920 DTCI_TstNPsdPwrUpSt_780 "BLN";
BA_ "VNSigAllNodes" SG_ 1920 DTCI_TstNPsdPwrUpSt_780 1;
BA_ "SignalLongName" SG_ 1920 DTCI_TstNPsdCdClrdSt_780 "Diagnostic Trouble Code Information Extended 780 : Test Not Passed Since Code Cleared Status";
BA_ "PacketOrder" SG_ 1920 DTCI_TstNPsdCdClrdSt_780 17;
BA_ "SignalType" SG_ 1920 DTCI_TstNPsdCdClrdSt_780 "BLN";
BA_ "VNSigAllNodes" SG_ 1920 DTCI_TstNPsdCdClrdSt_780 1;
BA_ "SignalLongName" SG_ 1920 DTCI_TstFldPwrUpSt_780 "Diagnostic Trouble Code Information Extended 780 : Test Failed Since Power Up Status";
BA_ "PacketOrder" SG_ 1920 DTCI_TstFldPwrUpSt_780 13;
BA_ "SignalType" SG_ 1920 DTCI_TstFldPwrUpSt_780 "BLN";
BA_ "VNSigAllNodes" SG_ 1920 DTCI_TstFldPwrUpSt_780 1;
BA_ "SignalLongName" SG_ 1920 DTCI_TstFldCdClrdStat_780 "Diagnostic Trouble Code Information Extended 780 : Test Failed Since Code Cleared Status";
BA_ "PacketOrder" SG_ 1920 DTCI_TstFldCdClrdStat_780 16;
BA_ "SignalType" SG_ 1920 DTCI_TstFldCdClrdStat_780 "BLN";
BA_ "VNSigAllNodes" SG_ 1920 DTCI_TstFldCdClrdStat_780 1;
BA_ "SignalLongName" SG_ 1920 DTCI_HistStat_780 "Diagnostic Trouble Code Information Extended 780 : History Status";
BA_ "PacketOrder" SG_ 1920 DTCI_HistStat_780 15;
BA_ "SignalType" SG_ 1920 DTCI_HistStat_780 "BLN";
BA_ "VNSigAllNodes" SG_ 1920 DTCI_HistStat_780 1;
BA_ "SignalLongName" SG_ 1920 DTCI_DTCTriggered_780 "Diagnostic Trouble Code Information Extended 780 : Diagnostic Trouble Code Triggered";
BA_ "PacketOrder" SG_ 1920 DTCI_DTCTriggered_780 8;
BA_ "SignalType" SG_ 1920 DTCI_DTCTriggered_780 "BLN";
BA_ "VNSigAllNodes" SG_ 1920 DTCI_DTCTriggered_780 1;
BA_ "SignalLongName" SG_ 1920 DTCI_DTCSource_780 "Diagnostic Trouble Code Information Extended 780 : Diagnostic Trouble Code Source";
BA_ "PacketOrder" SG_ 1920 DTCI_DTCSource_780 9;
BA_ "SignalType" SG_ 1920 DTCI_DTCSource_780 "UNM";
BA_ "VNSigAllNodes" SG_ 1920 DTCI_DTCSource_780 1;
BA_ "SignalLongName" SG_ 1920 DTCI_DTCNumber_780 "Diagnostic Trouble Code Information Extended 780 : Diagnostic Trouble Code Number";
BA_ "PacketOrder" SG_ 1920 DTCI_DTCNumber_780 10;
BA_ "SignalType" SG_ 1920 DTCI_DTCNumber_780 "UNM";
BA_ "VNSigAllNodes" SG_ 1920 DTCI_DTCNumber_780 1;
BA_ "SignalLongName" SG_ 1920 DTCI_DTCFaultType_780 "Diagnostic Trouble Code Information Extended 780 : Diagnostic Trouble Code Fault Type";
BA_ "PacketOrder" SG_ 1920 DTCI_DTCFaultType_780 20;
BA_ "SignalType" SG_ 1920 DTCI_DTCFaultType_780 "ENM";
BA_ "VNSigAllNodes" SG_ 1920 DTCI_DTCFaultType_780 1;
BA_ "SignalLongName" SG_ 1920 DTCI_DTCFailType_780 "Diagnostic Trouble Code Information Extended 780 : Diagnostic Trouble Code Failure Type";
BA_ "PacketOrder" SG_ 1920 DTCI_DTCFailType_780 11;
BA_ "SignalType" SG_ 1920 DTCI_DTCFailType_780 "UNM";
BA_ "VNSigAllNodes" SG_ 1920 DTCI_DTCFailType_780 1;
BA_ "SignalLongName" SG_ 1920 DTCI_CodeSupported_780 "Diagnostic Trouble Code Information Extended 780 : Code Supported";
BA_ "PacketOrder" SG_ 1920 DTCI_CodeSupported_780 19;
BA_ "SignalType" SG_ 1920 DTCI_CodeSupported_780 "BLN";
BA_ "VNSigAllNodes" SG_ 1920 DTCI_CodeSupported_780 1;
BA_ "SignalLongName" SG_ 1907 DTCI_DTCFaultType_773 "Diagnostic Trouble Code Information Extended 773 : Diagnostic Trouble Code Fault Type";
BA_ "PacketOrder" SG_ 1907 DTCI_DTCFaultType_773 20;
BA_ "SignalType" SG_ 1907 DTCI_DTCFaultType_773 "ENM";
BA_ "VNSigAllNodes" SG_ 1907 DTCI_DTCFaultType_773 1;
BA_ "SignalLongName" SG_ 1907 DTCI_CodeSupported_773 "Diagnostic Trouble Code Information Extended 773 : Code Supported";
BA_ "PacketOrder" SG_ 1907 DTCI_CodeSupported_773 19;
BA_ "SignalType" SG_ 1907 DTCI_CodeSupported_773 "BLN";
BA_ "VNSigAllNodes" SG_ 1907 DTCI_CodeSupported_773 1;
BA_ "SignalLongName" SG_ 1907 DTCI_CurrentStatus_773 "Diagnostic Trouble Code Information Extended 773 : Current Status";
BA_ "PacketOrder" SG_ 1907 DTCI_CurrentStatus_773 18;
BA_ "SignalType" SG_ 1907 DTCI_CurrentStatus_773 "BLN";
BA_ "VNSigAllNodes" SG_ 1907 DTCI_CurrentStatus_773 1;
BA_ "SignalLongName" SG_ 1907 DTCI_TstNPsdCdClrdSt_773 "Diagnostic Trouble Code Information Extended 773 : Test Not Passed Since Code Cleared Status";
BA_ "PacketOrder" SG_ 1907 DTCI_TstNPsdCdClrdSt_773 17;
BA_ "SignalType" SG_ 1907 DTCI_TstNPsdCdClrdSt_773 "BLN";
BA_ "VNSigAllNodes" SG_ 1907 DTCI_TstNPsdCdClrdSt_773 1;
BA_ "SignalLongName" SG_ 1907 DTCI_TstFldCdClrdStat_773 "Diagnostic Trouble Code Information Extended 773 : Test Failed Since Code Cleared Status";
BA_ "PacketOrder" SG_ 1907 DTCI_TstFldCdClrdStat_773 16;
BA_ "SignalType" SG_ 1907 DTCI_TstFldCdClrdStat_773 "BLN";
BA_ "VNSigAllNodes" SG_ 1907 DTCI_TstFldCdClrdStat_773 1;
BA_ "SignalLongName" SG_ 1907 DTCI_HistStat_773 "Diagnostic Trouble Code Information Extended 773 : History Status";
BA_ "PacketOrder" SG_ 1907 DTCI_HistStat_773 15;
BA_ "SignalType" SG_ 1907 DTCI_HistStat_773 "BLN";
BA_ "VNSigAllNodes" SG_ 1907 DTCI_HistStat_773 1;
BA_ "SignalLongName" SG_ 1907 DTCI_TstNPsdPwrUpSt_773 "Diagnostic Trouble Code Information Extended 773 : Test Not Passed Since Power Up Status";
BA_ "PacketOrder" SG_ 1907 DTCI_TstNPsdPwrUpSt_773 14;
BA_ "SignalType" SG_ 1907 DTCI_TstNPsdPwrUpSt_773 "BLN";
BA_ "VNSigAllNodes" SG_ 1907 DTCI_TstNPsdPwrUpSt_773 1;
BA_ "SignalLongName" SG_ 1907 DTCI_TstFldPwrUpSt_773 "Diagnostic Trouble Code Information Extended 773 : Test Failed Since Power Up Status";
BA_ "PacketOrder" SG_ 1907 DTCI_TstFldPwrUpSt_773 13;
BA_ "SignalType" SG_ 1907 DTCI_TstFldPwrUpSt_773 "BLN";
BA_ "VNSigAllNodes" SG_ 1907 DTCI_TstFldPwrUpSt_773 1;
BA_ "SignalLongName" SG_ 1907 DTCI_WrnIndRqdSt_773 "Diagnostic Trouble Code Information Extended 773 : Warning Indicator Requested Status";
BA_ "PacketOrder" SG_ 1907 DTCI_WrnIndRqdSt_773 12;
BA_ "SignalType" SG_ 1907 DTCI_WrnIndRqdSt_773 "BLN";
BA_ "VNSigAllNodes" SG_ 1907 DTCI_WrnIndRqdSt_773 1;
BA_ "SignalLongName" SG_ 1907 DTCI_DTCFailType_773 "Diagnostic Trouble Code Information Extended 773 : Diagnostic Trouble Code Failure Type";
BA_ "PacketOrder" SG_ 1907 DTCI_DTCFailType_773 11;
BA_ "SignalType" SG_ 1907 DTCI_DTCFailType_773 "UNM";
BA_ "VNSigAllNodes" SG_ 1907 DTCI_DTCFailType_773 1;
BA_ "SignalLongName" SG_ 1907 DTCI_DTCNumber_773 "Diagnostic Trouble Code Information Extended 773 : Diagnostic Trouble Code Number";
BA_ "PacketOrder" SG_ 1907 DTCI_DTCNumber_773 10;
BA_ "SignalType" SG_ 1907 DTCI_DTCNumber_773 "UNM";
BA_ "VNSigAllNodes" SG_ 1907 DTCI_DTCNumber_773 1;
BA_ "SignalLongName" SG_ 1907 DTCI_DTCSource_773 "Diagnostic Trouble Code Information Extended 773 : Diagnostic Trouble Code Source";
BA_ "PacketOrder" SG_ 1907 DTCI_DTCSource_773 9;
BA_ "SignalType" SG_ 1907 DTCI_DTCSource_773 "UNM";
BA_ "VNSigAllNodes" SG_ 1907 DTCI_DTCSource_773 1;
BA_ "SignalLongName" SG_ 1907 DTCI_DTCTriggered_773 "Diagnostic Trouble Code Information Extended 773 : Diagnostic Trouble Code Triggered";
BA_ "PacketOrder" SG_ 1907 DTCI_DTCTriggered_773 8;
BA_ "SignalType" SG_ 1907 DTCI_DTCTriggered_773 "BLN";
BA_ "VNSigAllNodes" SG_ 1907 DTCI_DTCTriggered_773 1;
BA_ "SignalLongName" SG_ 1907 DTCIUnused7_773 "Diagnostic Trouble Code Information Extended 773 : Unused 7";
BA_ "PacketOrder" SG_ 1907 DTCIUnused7_773 7;
BA_ "SignalType" SG_ 1907 DTCIUnused7_773 "BLN";
BA_ "VNSigAllNodes" SG_ 1907 DTCIUnused7_773 1;
BA_ "SignalLongName" SG_ 1907 DTCIUnused6_773 "Diagnostic Trouble Code Information Extended 773 : Unused 6";
BA_ "PacketOrder" SG_ 1907 DTCIUnused6_773 6;
BA_ "SignalType" SG_ 1907 DTCIUnused6_773 "BLN";
BA_ "VNSigAllNodes" SG_ 1907 DTCIUnused6_773 1;
BA_ "SignalLongName" SG_ 1907 DTCIUnused5_773 "Diagnostic Trouble Code Information Extended 773 : Unused 5";
BA_ "PacketOrder" SG_ 1907 DTCIUnused5_773 5;
BA_ "SignalType" SG_ 1907 DTCIUnused5_773 "BLN";
BA_ "VNSigAllNodes" SG_ 1907 DTCIUnused5_773 1;
BA_ "SignalLongName" SG_ 1907 DTCIUnused4_773 "Diagnostic Trouble Code Information Extended 773 : Unused 4";
BA_ "PacketOrder" SG_ 1907 DTCIUnused4_773 4;
BA_ "SignalType" SG_ 1907 DTCIUnused4_773 "BLN";
BA_ "VNSigAllNodes" SG_ 1907 DTCIUnused4_773 1;
BA_ "SignalLongName" SG_ 1907 DTCIUnused3_773 "Diagnostic Trouble Code Information Extended 773 : Unused 3";
BA_ "PacketOrder" SG_ 1907 DTCIUnused3_773 3;
BA_ "SignalType" SG_ 1907 DTCIUnused3_773 "BLN";
BA_ "VNSigAllNodes" SG_ 1907 DTCIUnused3_773 1;
BA_ "SignalLongName" SG_ 1907 DTCIUnused2_773 "Diagnostic Trouble Code Information Extended 773 : Unused 2";
BA_ "PacketOrder" SG_ 1907 DTCIUnused2_773 2;
BA_ "SignalType" SG_ 1907 DTCIUnused2_773 "BLN";
BA_ "VNSigAllNodes" SG_ 1907 DTCIUnused2_773 1;
BA_ "SignalLongName" SG_ 1907 DTCIUnused1_773 "Diagnostic Trouble Code Information Extended 773 : Unused 1";
BA_ "PacketOrder" SG_ 1907 DTCIUnused1_773 1;
BA_ "SignalType" SG_ 1907 DTCIUnused1_773 "BLN";
BA_ "VNSigAllNodes" SG_ 1907 DTCIUnused1_773 1;
BA_ "SignalLongName" SG_ 1603 DgnInf "Diagnostic Information";
BA_ "SignalType" SG_ 1603 DgnInf "UNM";
BA_ "VNSigSLHSSharedDiagnostic" SG_ 1603 DgnInf 1;
BA_ "VNSigAllNodes" SG_ 1603 DgnInf 1;
BA_ "GenSigDeltaValue" SG_ 1603 DgnInf 1;
BA_ "GenSigSendType" SG_ 1603 DgnInf 12;
BA_ "SignalLongName" SG_ 1347 DgnInf_HS543 "Diagnostic Information HS543";
BA_ "SignalType" SG_ 1347 DgnInf_HS543 "UNM";
BA_ "VNSigSLHSSharedDiagnostic" SG_ 1347 DgnInf_HS543 1;
BA_ "VNSigAllNodes" SG_ 1347 DgnInf_HS543 1;
BA_ "SignalLongName" SG_ 455 APAEngTrqRdctnAct "Advanced Park Assist Engine Torque Reduction Active";
BA_ "SignalType" SG_ 455 APAEngTrqRdctnAct "BLN";
BA_ "VNSigAllNodes" SG_ 455 APAEngTrqRdctnAct 1;
BA_ "SignalLongName" SG_ 455 CSETRER_TorqReqVal "Chassis System Engine Torque Request Extended Range : Torque Request Value";
BA_ "PacketOrder" SG_ 455 CSETRER_TorqReqVal 2;
BA_ "SignalType" SG_ 455 CSETRER_TorqReqVal "UNM";
BA_ "VNSigAllNodes" SG_ 455 CSETRER_TorqReqVal 1;
BA_ "SignalLongName" SG_ 455 CSETRER_TqIntvnTyp "Chassis System Engine Torque Request Extended Range : Torque Intervention Type";
BA_ "PacketOrder" SG_ 455 CSETRER_TqIntvnTyp 1;
BA_ "SignalType" SG_ 455 CSETRER_TqIntvnTyp "ENM";
BA_ "VNSigAllNodes" SG_ 455 CSETRER_TqIntvnTyp 1;
BA_ "SignalLongName" SG_ 455 TracCntrlMaxTorqIncRt "Traction Control Maximum Torque Increase Rate";
BA_ "SignalType" SG_ 455 TracCntrlMaxTorqIncRt "UNM";
BA_ "VNSigAllNodes" SG_ 455 TracCntrlMaxTorqIncRt 1;
BA_ "SignalLongName" SG_ 455 TCAliveRC "Traction Control Alive Rolling Count";
BA_ "SignalType" SG_ 455 TCAliveRC "UNM";
BA_ "VNSigAllNodes" SG_ 455 TCAliveRC 1;
BA_ "SignalLongName" SG_ 455 ChsSysEngTrqReqProt "Chassis System Engine Torque Request Protection";
BA_ "SignalType" SG_ 455 ChsSysEngTrqReqProt "UNM";
BA_ "VNSigAllNodes" SG_ 455 ChsSysEngTrqReqProt 1;
BA_ "GenSigStartValue" SG_ 975 CGMDS1_DTCStat 2;
BA_ "SignalLongName" SG_ 975 CGMDS1_DTCStat "Central Gateway Module Diagnostic Status 1 : Diagnostic Trouble Code Status";
BA_ "PacketOrder" SG_ 975 CGMDS1_DTCStat 2;
BA_ "SignalType" SG_ 975 CGMDS1_DTCStat "ENM";
BA_ "VNSigAllNodes" SG_ 975 CGMDS1_DTCStat 1;
BA_ "SignalLongName" SG_ 975 CGMDS1_DTCIndx "Central Gateway Module Diagnostic Status 1 : Diagnostic Trouble Code Index";
BA_ "PacketOrder" SG_ 975 CGMDS1_DTCIndx 1;
BA_ "SignalType" SG_ 975 CGMDS1_DTCIndx "UNM";
BA_ "VNSigAllNodes" SG_ 975 CGMDS1_DTCIndx 1;
BA_ "GenSigStartValue" SG_ 975 CGMDS2_DTCStat 2;
BA_ "SignalLongName" SG_ 975 CGMDS2_DTCStat "Central Gateway Module Diagnostic Status 2 : Diagnostic Trouble Code Status";
BA_ "PacketOrder" SG_ 975 CGMDS2_DTCStat 2;
BA_ "SignalType" SG_ 975 CGMDS2_DTCStat "ENM";
BA_ "VNSigAllNodes" SG_ 975 CGMDS2_DTCStat 1;
BA_ "SignalLongName" SG_ 975 CGMDS2_DTCIndx "Central Gateway Module Diagnostic Status 2 : Diagnostic Trouble Code Index";
BA_ "PacketOrder" SG_ 975 CGMDS2_DTCIndx 1;
BA_ "SignalType" SG_ 975 CGMDS2_DTCIndx "UNM";
BA_ "VNSigAllNodes" SG_ 975 CGMDS2_DTCIndx 1;
BA_ "SignalLongName" SG_ 1223 PropSysOffTmeV "Propulsion System Off Time Validity";
BA_ "SignalType" SG_ 1223 PropSysOffTmeV "ENM";
BA_ "VNSigAllNodes" SG_ 1223 PropSysOffTmeV 1;
BA_ "SignalLongName" SG_ 1223 PropSysOffTmeM "Propulsion System Off Time Mask";
BA_ "SignalType" SG_ 1223 PropSysOffTmeM "ENM";
BA_ "VNSigAllNodes" SG_ 1223 PropSysOffTmeM 1;
BA_ "SignalLongName" SG_ 1223 PropSysOffTme "Propulsion System Off Time";
BA_ "SignalType" SG_ 1223 PropSysOffTme "UNM";
BA_ "VNSigAllNodes" SG_ 1223 PropSysOffTme 1;
BA_ "SignalLongName" SG_ 211 ActAxleTrqV "Actual Axle Torque Validity";
BA_ "SignalType" SG_ 211 ActAxleTrqV "ENM";
BA_ "VNSigAllNodes" SG_ 211 ActAxleTrqV 1;
BA_ "SignalLongName" SG_ 211 ActAxleTrq "Actual Axle Torque";
BA_ "SignalType" SG_ 211 ActAxleTrq "UNM";
BA_ "VNSigAllNodes" SG_ 211 ActAxleTrq 1;
BA_ "SignalLongName" SG_ 988 EngMntncePrcntCpl "Engine Maintenance Percent Complete";
BA_ "SignalType" SG_ 988 EngMntncePrcntCpl "UNM";
BA_ "VNSigAllNodes" SG_ 988 EngMntncePrcntCpl 1;
BA_ "GenSigDeltaValue" SG_ 988 EngMntncePrcntCpl 1;
BA_ "GenSigSendType" SG_ 988 EngMntncePrcntCpl 12;
BA_ "SignalLongName" SG_ 988 MntnceMdDsplyRq "Maintenance Mode Display Request";
BA_ "SignalType" SG_ 988 MntnceMdDsplyRq "ENM";
BA_ "VNSigAllNodes" SG_ 988 MntnceMdDsplyRq 1;
BA_ "GenSigSendType" SG_ 988 MntnceMdDsplyRq 10;
BA_ "GenSigSendOnInit" SG_ 988 MntnceMdDsplyRq 1;
BA_ "SignalLongName" SG_ 988 EngMntnceMdAct "Engine Maintenance Mode Active";
BA_ "SignalType" SG_ 988 EngMntnceMdAct "BLN";
BA_ "VNSigAllNodes" SG_ 988 EngMntnceMdAct 1;
BA_ "GenSigSendType" SG_ 988 EngMntnceMdAct 10;
BA_ "SignalLongName" SG_ 988 EngHtrValvBpasCmd "Engine Heater Valve Bypass Command";
BA_ "SignalType" SG_ 988 EngHtrValvBpasCmd "ENM";
BA_ "VNSigAllNodes" SG_ 988 EngHtrValvBpasCmd 1;
BA_ "SignalLongName" SG_ 988 EGHRInhbtRqstd "Exhaust Gas Heat Recovery Inhibit Requested";
BA_ "SignalType" SG_ 988 EGHRInhbtRqstd "BLN";
BA_ "VNSigAllNodes" SG_ 988 EGHRInhbtRqstd 1;
BA_ "SignalLongName" SG_ 988 AccPwrModMinCoolRq "Accessory Power Module Minimum Cooling Request";
BA_ "SignalType" SG_ 988 AccPwrModMinCoolRq "ENM";
BA_ "VNSigAllNodes" SG_ 988 AccPwrModMinCoolRq 1;
BA_ "SignalLongName" SG_ 988 HVPropChgrUnbl "High Voltage Propulsion Charging Unavailable";
BA_ "SignalType" SG_ 988 HVPropChgrUnbl "BLN";
BA_ "VNSigAllNodes" SG_ 988 HVPropChgrUnbl 1;
BA_ "SignalLongName" SG_ 988 A6ERRAlrmTime "Alarm 6 Extended Range Request : Alarm Time";
BA_ "PacketOrder" SG_ 988 A6ERRAlrmTime 2;
BA_ "SignalType" SG_ 988 A6ERRAlrmTime "UNM";
BA_ "VNSigAllNodes" SG_ 988 A6ERRAlrmTime 1;
BA_ "SignalLongName" SG_ 988 A6ERRAlrmReq "Alarm 6 Extended Range Request : Alarm Request";
BA_ "PacketOrder" SG_ 988 A6ERRAlrmReq 1;
BA_ "SignalType" SG_ 988 A6ERRAlrmReq "ENM";
BA_ "VNSigAllNodes" SG_ 988 A6ERRAlrmReq 1;
BA_ "SignalLongName" SG_ 209 BrkModMinVoltReqARC "Brake Module Minimum Voltage Request Alive Rolling Count";
BA_ "SignalType" SG_ 209 BrkModMinVoltReqARC "UNM";
BA_ "VNSigAllNodes" SG_ 209 BrkModMinVoltReqARC 1;
BA_ "SignalLongName" SG_ 209 BrkModMinVoltReq "Brake Module Minimum Voltage Request";
BA_ "SignalType" SG_ 209 BrkModMinVoltReq "UNM";
BA_ "VNSigAllNodes" SG_ 209 BrkModMinVoltReq 1;
BA_ "SignalLongName" SG_ 209 ChsBrkPdlPsERltdV "Chassis Brake Pedal Position Emissions Related Validity";
BA_ "SignalType" SG_ 209 ChsBrkPdlPsERltdV "ENM";
BA_ "VNSigAllNodes" SG_ 209 ChsBrkPdlPsERltdV 1;
BA_ "SignalLongName" SG_ 209 ChsBrkPdlPsERltdPVal "Chassis Brake Pedal Position Emissions Related Protection Value";
BA_ "SignalType" SG_ 209 ChsBrkPdlPsERltdPVal "UNM";
BA_ "VNSigAllNodes" SG_ 209 ChsBrkPdlPsERltdPVal 1;
BA_ "SignalLongName" SG_ 209 ChsBrkPdlPsERltdARC "Chassis Brake Pedal Position Emissions Related Alive Rolling Count";
BA_ "SignalType" SG_ 209 ChsBrkPdlPsERltdARC "UNM";
BA_ "VNSigAllNodes" SG_ 209 ChsBrkPdlPsERltdARC 1;
BA_ "SignalLongName" SG_ 209 ChsBrkPdlPsERltd "Chassis Brake Pedal Position Emissions Related";
BA_ "SignalType" SG_ 209 ChsBrkPdlPsERltd "UNM";
BA_ "VNSigAllNodes" SG_ 209 ChsBrkPdlPsERltd 1;
BA_ "SignalLongName" SG_ 209 DrvIntndTtlBrkTrqPVal "Driver Intended Total Brake Torque Protection Value";
BA_ "SignalType" SG_ 209 DrvIntndTtlBrkTrqPVal "UNM";
BA_ "VNSigAllNodes" SG_ 209 DrvIntndTtlBrkTrqPVal 1;
BA_ "SignalLongName" SG_ 209 DrvIntndTtlBrkTrqARC "Driver Intended Total Brake Torque Alive Rolling Count";
BA_ "SignalType" SG_ 209 DrvIntndTtlBrkTrqARC "UNM";
BA_ "VNSigAllNodes" SG_ 209 DrvIntndTtlBrkTrqARC 1;
BA_ "SignalLongName" SG_ 209 DrvIntndTtlBrkTrq "Driver Intended Total Brake Torque";
BA_ "SignalType" SG_ 209 DrvIntndTtlBrkTrq "UNM";
BA_ "VNSigAllNodes" SG_ 209 DrvIntndTtlBrkTrq 1;
BA_ "SignalLongName" SG_ 715 LnCntrngCtlCmdProtVal "Lane Centering Control Command Protection Value";
BA_ "SignalType" SG_ 715 LnCntrngCtlCmdProtVal "UNM";
BA_ "VNSigAllNodes" SG_ 715 LnCntrngCtlCmdProtVal 1;
BA_ "SignalLongName" SG_ 715 LnCntrngCtlCmdARC "Lane Centering Control Command Alive Rolling Count";
BA_ "SignalType" SG_ 715 LnCntrngCtlCmdARC "UNM";
BA_ "VNSigAllNodes" SG_ 715 LnCntrngCtlCmdARC 1;
BA_ "SignalLongName" SG_ 715 LCCC_Act "Lane Centering Control Command : Active";
BA_ "PacketOrder" SG_ 715 LCCC_Act 2;
BA_ "SignalType" SG_ 715 LCCC_Act "BLN";
BA_ "VNSigAllNodes" SG_ 715 LCCC_Act 1;
BA_ "SignalLongName" SG_ 715 LCCC_AccelPedLimReq "Lane Centering Control Command : Accel Pedal Limiting Request";
BA_ "PacketOrder" SG_ 715 LCCC_AccelPedLimReq 1;
BA_ "SignalType" SG_ 715 LCCC_AccelPedLimReq "BLN";
BA_ "VNSigAllNodes" SG_ 715 LCCC_AccelPedLimReq 1;
BA_ "SignalLongName" SG_ 715 ACCAxlTrqCmdProt "Adaptive Cruise Control Axle torque Command Protection";
BA_ "SignalType" SG_ 715 ACCAxlTrqCmdProt "UNM";
BA_ "VNSigAllNodes" SG_ 715 ACCAxlTrqCmdProt 1;
BA_ "SignalLongName" SG_ 715 ACCCmndAlvRlgCnt "Adaptive Cruise Control Command Alive Rolling Count";
BA_ "SignalType" SG_ 715 ACCCmndAlvRlgCnt "UNM";
BA_ "VNSigAllNodes" SG_ 715 ACCCmndAlvRlgCnt 1;
BA_ "SignalLongName" SG_ 715 ACCATC_SplREngInpR "Adaptive Cruise Control Axle Torque Command : Special Re-engagement Input Required";
BA_ "PacketOrder" SG_ 715 ACCATC_SplREngInpR 4;
BA_ "SignalType" SG_ 715 ACCATC_SplREngInpR "BLN";
BA_ "VNSigAllNodes" SG_ 715 ACCATC_SplREngInpR 1;
BA_ "SignalLongName" SG_ 715 ACCATC_DrvAstdGoSt "Adaptive Cruise Control Axle Torque Command : Driver Assisted Go State";
BA_ "PacketOrder" SG_ 715 ACCATC_DrvAstdGoSt 3;
BA_ "SignalType" SG_ 715 ACCATC_DrvAstdGoSt "ENM";
BA_ "VNSigAllNodes" SG_ 715 ACCATC_DrvAstdGoSt 1;
BA_ "SignalLongName" SG_ 715 ACCATC_AxlTrqRq "Adaptive Cruise Control Axle Torque Command : Axle Torque Request";
BA_ "PacketOrder" SG_ 715 ACCATC_AxlTrqRq 5;
BA_ "SignalType" SG_ 715 ACCATC_AxlTrqRq "UNM";
BA_ "VNSigAllNodes" SG_ 715 ACCATC_AxlTrqRq 1;
BA_ "SignalLongName" SG_ 715 ACCATC_ACCTyp "Adaptive Cruise Control Axle Torque Command : Adaptive Cruise Control Type";
BA_ "PacketOrder" SG_ 715 ACCATC_ACCTyp 2;
BA_ "SignalType" SG_ 715 ACCATC_ACCTyp "ENM";
BA_ "VNSigAllNodes" SG_ 715 ACCATC_ACCTyp 1;
BA_ "SignalLongName" SG_ 715 ACCATC_ACCAct "Adaptive Cruise Control Axle Torque Command : Adaptive Cruise Control Active";
BA_ "PacketOrder" SG_ 715 ACCATC_ACCAct 1;
BA_ "SignalType" SG_ 715 ACCATC_ACCAct "BLN";
BA_ "VNSigAllNodes" SG_ 715 ACCATC_ACCAct 1;
BA_ "SignalLongName" SG_ 453 DrvIntndAxlTrqMinV "Driver Intended Axle Torque Minimum Validity";
BA_ "SignalType" SG_ 453 DrvIntndAxlTrqMinV "ENM";
BA_ "VNSigAllNodes" SG_ 453 DrvIntndAxlTrqMinV 1;
BA_ "SignalLongName" SG_ 453 DrvIntndAxlTrqMin "Driver Intended Axle Torque Minimum";
BA_ "SignalType" SG_ 453 DrvIntndAxlTrqMin "UNM";
BA_ "VNSigAllNodes" SG_ 453 DrvIntndAxlTrqMin 1;
BA_ "SignalLongName" SG_ 453 DrvIntndAxlTrqMaxV "Driver Intended Axle Torque Maximum Validity";
BA_ "SignalType" SG_ 453 DrvIntndAxlTrqMaxV "ENM";
BA_ "VNSigAllNodes" SG_ 453 DrvIntndAxlTrqMaxV 1;
BA_ "GenSigStartValue" SG_ 453 DrvIntndAxlTrqMax 32767;
BA_ "SignalLongName" SG_ 453 DrvIntndAxlTrqMax "Driver Intended Axle Torque Maximum";
BA_ "SignalType" SG_ 453 DrvIntndAxlTrqMax "UNM";
BA_ "VNSigAllNodes" SG_ 453 DrvIntndAxlTrqMax 1;
BA_ "SignalLongName" SG_ 453 DrvIntndAxlTrqV "Driver Intended Axle Torque Validity";
BA_ "SignalType" SG_ 453 DrvIntndAxlTrqV "ENM";
BA_ "VNSigAllNodes" SG_ 453 DrvIntndAxlTrqV 1;
BA_ "GenSigStartValue" SG_ 453 DrvIntndAxlTrq 11267;
BA_ "SignalLongName" SG_ 453 DrvIntndAxlTrq "Driver Intended Axle Torque";
BA_ "SignalType" SG_ 453 DrvIntndAxlTrq "UNM";
BA_ "VNSigAllNodes" SG_ 453 DrvIntndAxlTrq 1;
BA_ "SignalLongName" SG_ 495 MassAirFloV "Mass Air Flow Validity";
BA_ "SignalType" SG_ 495 MassAirFloV "ENM";
BA_ "VNSigAllNodes" SG_ 495 MassAirFloV 1;
BA_ "SignalLongName" SG_ 495 MassAirFlo "Mass Air Flow";
BA_ "SignalType" SG_ 495 MassAirFlo "UNM";
BA_ "VNSigAllNodes" SG_ 495 MassAirFlo 1;
BA_ "SignalLongName" SG_ 2020 DgnInf "Diagnostic Information";
BA_ "SignalType" SG_ 2020 DgnInf "UNM";
BA_ "VNSigSLHSSharedDiagnostic" SG_ 2020 DgnInf 1;
BA_ "VNSigAllNodes" SG_ 2020 DgnInf 1;
BA_ "GenSigDeltaValue" SG_ 2020 DgnInf 1;
BA_ "GenSigSendType" SG_ 2020 DgnInf 12;
BA_ "SignalLongName" SG_ 493 EngRunng "Engine Running";
BA_ "SignalType" SG_ 493 EngRunng "BLN";
BA_ "VNSigAllNodes" SG_ 493 EngRunng 1;
BA_ "SignalLongName" SG_ 493 FlPmpEDscOtptCmdSta "Fuel Pump Enabled Discrete Output Commanded Status";
BA_ "SignalType" SG_ 493 FlPmpEDscOtptCmdSta "ENM";
BA_ "VNSigAllNodes" SG_ 493 FlPmpEDscOtptCmdSta 1;
BA_ "SignalLongName" SG_ 493 CmmndAirFuelRatio "Commanded Air Fuel Ratio";
BA_ "SignalType" SG_ 493 CmmndAirFuelRatio "UNM";
BA_ "VNSigAllNodes" SG_ 493 CmmndAirFuelRatio 1;
BA_ "SignalLongName" SG_ 493 AdvFuelFlowEst "Advanced Fuel Flow Estimate";
BA_ "SignalType" SG_ 493 AdvFuelFlowEst "UNM";
BA_ "VNSigAllNodes" SG_ 493 AdvFuelFlowEst 1;
BA_ "SignalLongName" SG_ 493 FuelDelPressRqd "Fuel Delivery Pressure Requested";
BA_ "SignalType" SG_ 493 FuelDelPressRqd "UNM";
BA_ "VNSigAllNodes" SG_ 493 FuelDelPressRqd 1;
BA_ "SignalLongName" SG_ 493 FuelCntlSysFltPrsnt "Fuel Control System Fault Present";
BA_ "SignalType" SG_ 493 FuelCntlSysFltPrsnt "BLN";
BA_ "VNSigAllNodes" SG_ 493 FuelCntlSysFltPrsnt 1;
BA_ "SignalLongName" SG_ 493 InstFuelFlowEst "Instantaneous Fuel Flow Estimate";
BA_ "SignalType" SG_ 493 InstFuelFlowEst "UNM";
BA_ "VNSigAllNodes" SG_ 493 InstFuelFlowEst 1;
BA_ "SignalLongName" SG_ 2015 DgnInf "Diagnostic Information";
BA_ "SignalType" SG_ 2015 DgnInf "UNM";
BA_ "VNSigSLHSSharedDiagnostic" SG_ 2015 DgnInf 1;
BA_ "VNSigAllNodes" SG_ 2015 DgnInf 1;
BA_ "GenSigDeltaValue" SG_ 2015 DgnInf 1;
BA_ "GenSigSendType" SG_ 2015 DgnInf 12;
BA_ "SignalLongName" SG_ 989 RdChrgrCntctrStatus "Redundant Charger Contactor Status";
BA_ "SignalType" SG_ 989 RdChrgrCntctrStatus "ENM";
BA_ "VNSigAllNodes" SG_ 989 RdChrgrCntctrStatus 1;
BA_ "SignalLongName" SG_ 989 RdHVCntctrShdwnReq "Redundant High Voltage Contactor Shutdown Request";
BA_ "SignalType" SG_ 989 RdHVCntctrShdwnReq "ENM";
BA_ "VNSigAllNodes" SG_ 989 RdHVCntctrShdwnReq 1;
BA_ "SignalLongName" SG_ 989 AuxClntHtrVlvStat "Auxiliary Coolant Heater Valve Status";
BA_ "SignalType" SG_ 989 AuxClntHtrVlvStat "ENM";
BA_ "VNSigAllNodes" SG_ 989 AuxClntHtrVlvStat 1;
BA_ "GenSigSendType" SG_ 989 AuxClntHtrVlvStat 10;
BA_ "GenSigSendOnInit" SG_ 989 AuxClntHtrVlvStat 1;
BA_ "SignalLongName" SG_ 989 EngCoolFanOpEnbl "Engine Cooling Fan Operation Enable";
BA_ "SignalType" SG_ 989 EngCoolFanOpEnbl "BLN";
BA_ "VNSigAllNodes" SG_ 989 EngCoolFanOpEnbl 1;
BA_ "SignalLongName" SG_ 989 DiagFreeRunCntrV "Diagnostic Free Running Counter Validity";
BA_ "SignalType" SG_ 989 DiagFreeRunCntrV "ENM";
BA_ "VNSigAllNodes" SG_ 989 DiagFreeRunCntrV 1;
BA_ "SignalLongName" SG_ 989 DiagFreeRunCntr "Diagnostic Free Running Counter";
BA_ "SignalType" SG_ 989 DiagFreeRunCntr "UNM";
BA_ "VNSigAllNodes" SG_ 989 DiagFreeRunCntr 1;
BA_ "SignalLongName" SG_ 989 JmpStrtEnbld "Jump Start Enabled";
BA_ "SignalType" SG_ 989 JmpStrtEnbld "BLN";
BA_ "VNSigAllNodes" SG_ 989 JmpStrtEnbld 1;
BA_ "SignalLongName" SG_ 989 HybFanSpdRq "Hybrid Fan Speed Percent Request";
BA_ "SignalType" SG_ 989 HybFanSpdRq "UNM";
BA_ "VNSigAllNodes" SG_ 989 HybFanSpdRq 1;
BA_ "SignalLongName" SG_ 989 MntnceMdStEngRq "Maintenance Mode Start Engine Request";
BA_ "SignalType" SG_ 989 MntnceMdStEngRq "BLN";
BA_ "VNSigAllNodes" SG_ 989 MntnceMdStEngRq 1;
BA_ "GenSigSendType" SG_ 989 MntnceMdStEngRq 10;
BA_ "GenSigSendOnInit" SG_ 989 MntnceMdStEngRq 2;
BA_ "SignalLongName" SG_ 989 ThrmlRefCompSpdV "Thermal Refrigerant Compressor Speed Validity";
BA_ "SignalType" SG_ 989 ThrmlRefCompSpdV "ENM";
BA_ "VNSigAllNodes" SG_ 989 ThrmlRefCompSpdV 1;
BA_ "GenSigSendType" SG_ 989 ThrmlRefCompSpdV 10;
BA_ "GenSigSendOnInit" SG_ 989 ThrmlRefCompSpdV 1;
BA_ "SignalLongName" SG_ 989 ThrmlRefCompSpd "Thermal Refrigerant Compressor Speed";
BA_ "SignalType" SG_ 989 ThrmlRefCompSpd "UNM";
BA_ "VNSigAllNodes" SG_ 989 ThrmlRefCompSpd 1;
BA_ "GenSigDeltaValue" SG_ 989 ThrmlRefCompSpd 1;
BA_ "GenSigSendType" SG_ 989 ThrmlRefCompSpd 12;
BA_ "GenSigSendOnInit" SG_ 989 ThrmlRefCompSpd 1;
BA_ "SignalLongName" SG_ 989 RdHVCntctrCmdStat "Redundant High Voltage Contactor Command Status";
BA_ "SignalType" SG_ 989 RdHVCntctrCmdStat "ENM";
BA_ "VNSigAllNodes" SG_ 989 RdHVCntctrCmdStat 1;
BA_ "SignalLongName" SG_ 1927 DTCI_CodeSupported_787 "Diagnostic Trouble Code Information Extended 787 : Code Supported";
BA_ "PacketOrder" SG_ 1927 DTCI_CodeSupported_787 19;
BA_ "SignalType" SG_ 1927 DTCI_CodeSupported_787 "BLN";
BA_ "VNSigAllNodes" SG_ 1927 DTCI_CodeSupported_787 1;
BA_ "SignalLongName" SG_ 1927 DTCI_CurrentStatus_787 "Diagnostic Trouble Code Information Extended 787 : Current Status";
BA_ "PacketOrder" SG_ 1927 DTCI_CurrentStatus_787 18;
BA_ "SignalType" SG_ 1927 DTCI_CurrentStatus_787 "BLN";
BA_ "VNSigAllNodes" SG_ 1927 DTCI_CurrentStatus_787 1;
BA_ "SignalLongName" SG_ 1927 DTCI_DTCFailType_787 "Diagnostic Trouble Code Information Extended 787 : Diagnostic Trouble Code Failure Type";
BA_ "PacketOrder" SG_ 1927 DTCI_DTCFailType_787 11;
BA_ "SignalType" SG_ 1927 DTCI_DTCFailType_787 "UNM";
BA_ "VNSigAllNodes" SG_ 1927 DTCI_DTCFailType_787 1;
BA_ "SignalLongName" SG_ 1927 DTCI_DTCFaultType_787 "Diagnostic Trouble Code Information Extended 787 : Diagnostic Trouble Code Fault Type";
BA_ "PacketOrder" SG_ 1927 DTCI_DTCFaultType_787 20;
BA_ "SignalType" SG_ 1927 DTCI_DTCFaultType_787 "ENM";
BA_ "VNSigAllNodes" SG_ 1927 DTCI_DTCFaultType_787 1;
BA_ "SignalLongName" SG_ 1927 DTCI_DTCNumber_787 "Diagnostic Trouble Code Information Extended 787 : Diagnostic Trouble Code Number";
BA_ "PacketOrder" SG_ 1927 DTCI_DTCNumber_787 10;
BA_ "SignalType" SG_ 1927 DTCI_DTCNumber_787 "UNM";
BA_ "VNSigAllNodes" SG_ 1927 DTCI_DTCNumber_787 1;
BA_ "SignalLongName" SG_ 1927 DTCI_DTCSource_787 "Diagnostic Trouble Code Information Extended 787 : Diagnostic Trouble Code Source";
BA_ "PacketOrder" SG_ 1927 DTCI_DTCSource_787 9;
BA_ "SignalType" SG_ 1927 DTCI_DTCSource_787 "UNM";
BA_ "VNSigAllNodes" SG_ 1927 DTCI_DTCSource_787 1;
BA_ "SignalLongName" SG_ 1927 DTCI_DTCTriggered_787 "Diagnostic Trouble Code Information Extended 787 : Diagnostic Trouble Code Triggered";
BA_ "PacketOrder" SG_ 1927 DTCI_DTCTriggered_787 8;
BA_ "SignalType" SG_ 1927 DTCI_DTCTriggered_787 "BLN";
BA_ "VNSigAllNodes" SG_ 1927 DTCI_DTCTriggered_787 1;
BA_ "SignalLongName" SG_ 1927 DTCI_HistStat_787 "Diagnostic Trouble Code Information Extended 787 : History Status";
BA_ "PacketOrder" SG_ 1927 DTCI_HistStat_787 15;
BA_ "SignalType" SG_ 1927 DTCI_HistStat_787 "BLN";
BA_ "VNSigAllNodes" SG_ 1927 DTCI_HistStat_787 1;
BA_ "SignalLongName" SG_ 1927 DTCI_TstFldCdClrdStat_787 "Diagnostic Trouble Code Information Extended 787 : Test Failed Since Code Cleared Status";
BA_ "PacketOrder" SG_ 1927 DTCI_TstFldCdClrdStat_787 16;
BA_ "SignalType" SG_ 1927 DTCI_TstFldCdClrdStat_787 "BLN";
BA_ "VNSigAllNodes" SG_ 1927 DTCI_TstFldCdClrdStat_787 1;
BA_ "SignalLongName" SG_ 1927 DTCI_TstFldPwrUpSt_787 "Diagnostic Trouble Code Information Extended 787 : Test Failed Since Power Up Status";
BA_ "PacketOrder" SG_ 1927 DTCI_TstFldPwrUpSt_787 13;
BA_ "SignalType" SG_ 1927 DTCI_TstFldPwrUpSt_787 "BLN";
BA_ "VNSigAllNodes" SG_ 1927 DTCI_TstFldPwrUpSt_787 1;
BA_ "SignalLongName" SG_ 1927 DTCI_TstNPsdCdClrdSt_787 "Diagnostic Trouble Code Information Extended 787 : Test Not Passed Since Code Cleared Status";
BA_ "PacketOrder" SG_ 1927 DTCI_TstNPsdCdClrdSt_787 17;
BA_ "SignalType" SG_ 1927 DTCI_TstNPsdCdClrdSt_787 "BLN";
BA_ "VNSigAllNodes" SG_ 1927 DTCI_TstNPsdCdClrdSt_787 1;
BA_ "SignalLongName" SG_ 1927 DTCI_TstNPsdPwrUpSt_787 "Diagnostic Trouble Code Information Extended 787 : Test Not Passed Since Power Up Status";
BA_ "PacketOrder" SG_ 1927 DTCI_TstNPsdPwrUpSt_787 14;
BA_ "SignalType" SG_ 1927 DTCI_TstNPsdPwrUpSt_787 "BLN";
BA_ "VNSigAllNodes" SG_ 1927 DTCI_TstNPsdPwrUpSt_787 1;
BA_ "SignalLongName" SG_ 1927 DTCIUnused1_787 "Diagnostic Trouble Code Information Extended 787 : Unused 1";
BA_ "PacketOrder" SG_ 1927 DTCIUnused1_787 1;
BA_ "SignalType" SG_ 1927 DTCIUnused1_787 "BLN";
BA_ "VNSigAllNodes" SG_ 1927 DTCIUnused1_787 1;
BA_ "SignalLongName" SG_ 1927 DTCIUnused2_787 "Diagnostic Trouble Code Information Extended 787 : Unused 2";
BA_ "PacketOrder" SG_ 1927 DTCIUnused2_787 2;
BA_ "SignalType" SG_ 1927 DTCIUnused2_787 "BLN";
BA_ "VNSigAllNodes" SG_ 1927 DTCIUnused2_787 1;
BA_ "SignalLongName" SG_ 1927 DTCIUnused3_787 "Diagnostic Trouble Code Information Extended 787 : Unused 3";
BA_ "PacketOrder" SG_ 1927 DTCIUnused3_787 3;
BA_ "SignalType" SG_ 1927 DTCIUnused3_787 "BLN";
BA_ "VNSigAllNodes" SG_ 1927 DTCIUnused3_787 1;
BA_ "SignalLongName" SG_ 1927 DTCIUnused4_787 "Diagnostic Trouble Code Information Extended 787 : Unused 4";
BA_ "PacketOrder" SG_ 1927 DTCIUnused4_787 4;
BA_ "SignalType" SG_ 1927 DTCIUnused4_787 "BLN";
BA_ "VNSigAllNodes" SG_ 1927 DTCIUnused4_787 1;
BA_ "SignalLongName" SG_ 1927 DTCIUnused5_787 "Diagnostic Trouble Code Information Extended 787 : Unused 5";
BA_ "PacketOrder" SG_ 1927 DTCIUnused5_787 5;
BA_ "SignalType" SG_ 1927 DTCIUnused5_787 "BLN";
BA_ "VNSigAllNodes" SG_ 1927 DTCIUnused5_787 1;
BA_ "SignalLongName" SG_ 1927 DTCIUnused6_787 "Diagnostic Trouble Code Information Extended 787 : Unused 6";
BA_ "PacketOrder" SG_ 1927 DTCIUnused6_787 6;
BA_ "SignalType" SG_ 1927 DTCIUnused6_787 "BLN";
BA_ "VNSigAllNodes" SG_ 1927 DTCIUnused6_787 1;
BA_ "SignalLongName" SG_ 1927 DTCIUnused7_787 "Diagnostic Trouble Code Information Extended 787 : Unused 7";
BA_ "PacketOrder" SG_ 1927 DTCIUnused7_787 7;
BA_ "SignalType" SG_ 1927 DTCIUnused7_787 "BLN";
BA_ "VNSigAllNodes" SG_ 1927 DTCIUnused7_787 1;
BA_ "SignalLongName" SG_ 1927 DTCI_WrnIndRqdSt_787 "Diagnostic Trouble Code Information Extended 787 : Warning Indicator Requested Status";
BA_ "PacketOrder" SG_ 1927 DTCI_WrnIndRqdSt_787 12;
BA_ "SignalType" SG_ 1927 DTCI_WrnIndRqdSt_787 "BLN";
BA_ "VNSigAllNodes" SG_ 1927 DTCI_WrnIndRqdSt_787 1;
BA_ "SignalLongName" SG_ 2028 DgnInf "Diagnostic Information";
BA_ "SignalType" SG_ 2028 DgnInf "UNM";
BA_ "VNSigSLHSSharedDiagnostic" SG_ 2028 DgnInf 1;
BA_ "VNSigAllNodes" SG_ 2028 DgnInf 1;
BA_ "GenSigDeltaValue" SG_ 2028 DgnInf 1;
BA_ "GenSigSendType" SG_ 2028 DgnInf 12;
BA_ "SignalLongName" SG_ 1516 DgnInf "Diagnostic Information";
BA_ "SignalType" SG_ 1516 DgnInf "UNM";
BA_ "VNSigSLHSSharedDiagnostic" SG_ 1516 DgnInf 1;
BA_ "VNSigAllNodes" SG_ 1516 DgnInf 1;
BA_ "GenSigDeltaValue" SG_ 1516 DgnInf 1;
BA_ "GenSigSendType" SG_ 1516 DgnInf 12;
BA_ "GenSigStartValue" SG_ 1278 EHCCT_EHtrCrOutClntTmp 565.428109854604;
BA_ "SignalLongName" SG_ 1278 EHCCT_EHtrCrOutClntTmp "Estimated Heater Core Coolant Temperature : Estimated Heater Core Out Coolant Temperature";
BA_ "PacketOrder" SG_ 1278 EHCCT_EHtrCrOutClntTmp 4;
BA_ "SignalType" SG_ 1278 EHCCT_EHtrCrOutClntTmp "UNM";
BA_ "VNSigAllNodes" SG_ 1278 EHCCT_EHtrCrOutClntTmp 1;
BA_ "GenSigStartValue" SG_ 1278 EHCCT_EHtrCrInClntTmp 619.278406031233;
BA_ "SignalLongName" SG_ 1278 EHCCT_EHtrCrInClntTmp "Estimated Heater Core Coolant Temperature : Estimated Heater Core In Coolant Temperature";
BA_ "PacketOrder" SG_ 1278 EHCCT_EHtrCrInClntTmp 3;
BA_ "SignalType" SG_ 1278 EHCCT_EHtrCrInClntTmp "UNM";
BA_ "VNSigAllNodes" SG_ 1278 EHCCT_EHtrCrInClntTmp 1;
BA_ "SignalLongName" SG_ 1278 EHCCT_EHtrCrOutClntTmpV "Estimated Heater Core Coolant Temperature : Estimated Heater Core Out Coolant Temperature Validity";
BA_ "PacketOrder" SG_ 1278 EHCCT_EHtrCrOutClntTmpV 2;
BA_ "SignalType" SG_ 1278 EHCCT_EHtrCrOutClntTmpV "ENM";
BA_ "VNSigAllNodes" SG_ 1278 EHCCT_EHtrCrOutClntTmpV 1;
BA_ "SignalLongName" SG_ 1278 EHCCT_EHtrCrInClntTmpV "Estimated Heater Core Coolant Temperature : Estimated Heater Core In Coolant Temperature Validity";
BA_ "PacketOrder" SG_ 1278 EHCCT_EHtrCrInClntTmpV 1;
BA_ "SignalType" SG_ 1278 EHCCT_EHtrCrInClntTmpV "ENM";
BA_ "VNSigAllNodes" SG_ 1278 EHCCT_EHtrCrInClntTmpV 1;
BA_ "SignalLongName" SG_ 1278 EstHtrCrClntFlwrtFdbkV "Estimated Heater Core Coolant Flowrate Feedback Validity";
BA_ "SignalType" SG_ 1278 EstHtrCrClntFlwrtFdbkV "ENM";
BA_ "VNSigAllNodes" SG_ 1278 EstHtrCrClntFlwrtFdbkV 1;
BA_ "SignalLongName" SG_ 1278 EstHtrCrClntFlwrtFdbk "Estimated Heater Core Coolant Flowrate Feedback";
BA_ "SignalType" SG_ 1278 EstHtrCrClntFlwrtFdbk "UNM";
BA_ "VNSigAllNodes" SG_ 1278 EstHtrCrClntFlwrtFdbk 1;
BA_ "SignalLongName" SG_ 1276 CCFrBlwFnSpdFbkRatV "Climate Control Front Blower Fan Speed Feedback Rationalized Validity";
BA_ "SignalType" SG_ 1276 CCFrBlwFnSpdFbkRatV "ENM";
BA_ "VNSigAllNodes" SG_ 1276 CCFrBlwFnSpdFbkRatV 1;
BA_ "SignalLongName" SG_ 1276 CCFrBlwFnSpdFbkRat "Climate Control Front Blower Fan Speed Feedback Rationalized";
BA_ "SignalType" SG_ 1276 CCFrBlwFnSpdFbkRat "UNM";
BA_ "VNSigAllNodes" SG_ 1276 CCFrBlwFnSpdFbkRat 1;
BA_ "SignalLongName" SG_ 1037 BrkPdLfRrCnfrmReplcmntIO "Brake Pad Life Rear Confirm Replacement Indication On";
BA_ "SignalType" SG_ 1037 BrkPdLfRrCnfrmReplcmntIO "BLN";
BA_ "VNSigAllNodes" SG_ 1037 BrkPdLfRrCnfrmReplcmntIO 1;
BA_ "GenSigSendType" SG_ 1037 BrkPdLfRrCnfrmReplcmntIO 10;
BA_ "SignalLongName" SG_ 1037 BrkPdLfFrtCnfrmReplcmntIO "Brake Pad Life Front Confirm Replacement Indication On";
BA_ "SignalType" SG_ 1037 BrkPdLfFrtCnfrmReplcmntIO "BLN";
BA_ "VNSigAllNodes" SG_ 1037 BrkPdLfFrtCnfrmReplcmntIO 1;
BA_ "GenSigSendType" SG_ 1037 BrkPdLfFrtCnfrmReplcmntIO 10;
BA_ "SignalLongName" SG_ 1037 BrkPdLfRrDstRmng "Brake Pad Life Rear Distance Remaining";
BA_ "SignalType" SG_ 1037 BrkPdLfRrDstRmng "UNM";
BA_ "VNSigAllNodes" SG_ 1037 BrkPdLfRrDstRmng 1;
BA_ "GenSigDeltaValue" SG_ 1037 BrkPdLfRrDstRmng 1;
BA_ "GenSigSendType" SG_ 1037 BrkPdLfRrDstRmng 12;
BA_ "SignalLongName" SG_ 1037 BrkPdLfRrDstWrnIndRq "Brake Pad Life Rear Distance Warning Indication Request";
BA_ "SignalType" SG_ 1037 BrkPdLfRrDstWrnIndRq "ENM";
BA_ "VNSigAllNodes" SG_ 1037 BrkPdLfRrDstWrnIndRq 1;
BA_ "GenSigSendType" SG_ 1037 BrkPdLfRrDstWrnIndRq 10;
BA_ "SignalLongName" SG_ 1037 BrkPdLfFrtDstRmng "Brake Pad Life Front Distance Remaining";
BA_ "SignalType" SG_ 1037 BrkPdLfFrtDstRmng "UNM";
BA_ "VNSigAllNodes" SG_ 1037 BrkPdLfFrtDstRmng 1;
BA_ "GenSigDeltaValue" SG_ 1037 BrkPdLfFrtDstRmng 1;
BA_ "GenSigSendType" SG_ 1037 BrkPdLfFrtDstRmng 12;
BA_ "SignalLongName" SG_ 1037 BrkPdLfFrtDstWrnIndRq "Brake Pad Life Front Distance Warning Indication Request";
BA_ "SignalType" SG_ 1037 BrkPdLfFrtDstWrnIndRq "ENM";
BA_ "VNSigAllNodes" SG_ 1037 BrkPdLfFrtDstWrnIndRq 1;
BA_ "GenSigSendType" SG_ 1037 BrkPdLfFrtDstWrnIndRq 10;
BA_ "SignalLongName" SG_ 1037 BrkPdLfRrRstAvail "Brake Pad Life Rear Reset Available";
BA_ "SignalType" SG_ 1037 BrkPdLfRrRstAvail "BLN";
BA_ "VNSigAllNodes" SG_ 1037 BrkPdLfRrRstAvail 1;
BA_ "GenSigSendType" SG_ 1037 BrkPdLfRrRstAvail 10;
BA_ "SignalLongName" SG_ 1037 BrkPdLfFrtRstAvail "Brake Pad Life Front Reset Available";
BA_ "SignalType" SG_ 1037 BrkPdLfFrtRstAvail "BLN";
BA_ "VNSigAllNodes" SG_ 1037 BrkPdLfFrtRstAvail 1;
BA_ "GenSigSendType" SG_ 1037 BrkPdLfFrtRstAvail 10;
BA_ "SignalLongName" SG_ 1037 BrkPdLfRrV "Brake Pad Life Rear Validity";
BA_ "SignalType" SG_ 1037 BrkPdLfRrV "ENM";
BA_ "VNSigAllNodes" SG_ 1037 BrkPdLfRrV 1;
BA_ "GenSigSendType" SG_ 1037 BrkPdLfRrV 10;
BA_ "SignalLongName" SG_ 1037 BrkPdLfRr "Brake Pad Life Rear";
BA_ "SignalType" SG_ 1037 BrkPdLfRr "UNM";
BA_ "VNSigAllNodes" SG_ 1037 BrkPdLfRr 1;
BA_ "GenSigDeltaValue" SG_ 1037 BrkPdLfRr 1;
BA_ "GenSigSendType" SG_ 1037 BrkPdLfRr 12;
BA_ "SignalLongName" SG_ 1037 BrkPdLfFrtV "Brake Pad Life Front Validity";
BA_ "SignalType" SG_ 1037 BrkPdLfFrtV "ENM";
BA_ "VNSigAllNodes" SG_ 1037 BrkPdLfFrtV 1;
BA_ "GenSigSendType" SG_ 1037 BrkPdLfFrtV 10;
BA_ "SignalLongName" SG_ 1037 BrkPdLfFrt "Brake Pad Life Front";
BA_ "SignalType" SG_ 1037 BrkPdLfFrt "UNM";
BA_ "VNSigAllNodes" SG_ 1037 BrkPdLfFrt 1;
BA_ "GenSigDeltaValue" SG_ 1037 BrkPdLfFrt 1;
BA_ "GenSigSendType" SG_ 1037 BrkPdLfFrt 12;
BA_ "SignalLongName" SG_ 569 CrwlModeDndRsnIndReq "Crawl Mode Denied Reason Indication Request";
BA_ "SignalType" SG_ 569 CrwlModeDndRsnIndReq "ENM";
BA_ "VNSigAllNodes" SG_ 569 CrwlModeDndRsnIndReq 1;
BA_ "GenSigSendType" SG_ 569 CrwlModeDndRsnIndReq 10;
BA_ "SignalLongName" SG_ 569 LnchCtrlBrkPresVal "Launch Control Brake Pressure Value";
BA_ "SignalType" SG_ 569 LnchCtrlBrkPresVal "UNM";
BA_ "VNSigAllNodes" SG_ 569 LnchCtrlBrkPresVal 1;
BA_ "GenSigDeltaValue" SG_ 569 LnchCtrlBrkPresVal 1;
BA_ "GenSigSendType" SG_ 569 LnchCtrlBrkPresVal 12;
BA_ "SignalLongName" SG_ 569 LnchCtrlTmrVal "Launch Control Timer Value";
BA_ "SignalType" SG_ 569 LnchCtrlTmrVal "UNM";
BA_ "VNSigAllNodes" SG_ 569 LnchCtrlTmrVal 1;
BA_ "GenSigDeltaValue" SG_ 569 LnchCtrlTmrVal 1;
BA_ "GenSigSendType" SG_ 569 LnchCtrlTmrVal 12;
BA_REL_ "GenSigTimeoutTime" BU_SG_REL_ TCM_HS SG_ 398 EngActStdyStTorq 250;
BA_REL_ "GenSigTimeoutMsg" BU_SG_REL_ TCM_HS SG_ 398 EngActStdyStTorq 398;
BA_REL_ "GenSigSuprvResp" BU_SG_REL_ TCM_HS SG_ 398 EngActStdyStTorq 1;
BA_REL_ "GenSigTimeoutTime" BU_SG_REL_ TCM_HS SG_ 398 AccKdwnAtv 250;
BA_REL_ "GenSigTimeoutMsg" BU_SG_REL_ TCM_HS SG_ 398 AccKdwnAtv 398;
BA_REL_ "GenSigSuprvResp" BU_SG_REL_ TCM_HS SG_ 398 AccKdwnAtv 1;
BA_REL_ "GenSigTimeoutTime" BU_SG_REL_ TCM_HS SG_ 398 TrnsEngSpdReqFld 250;
BA_REL_ "GenSigTimeoutMsg" BU_SG_REL_ TCM_HS SG_ 398 TrnsEngSpdReqFld 398;
BA_REL_ "GenSigSuprvResp" BU_SG_REL_ TCM_HS SG_ 398 TrnsEngSpdReqFld 1;
BA_REL_ "GenSigTimeoutTime" BU_SG_REL_ CGM_HS SG_ 1267 VehMassNom 2500;
BA_REL_ "GenSigTimeoutMsg" BU_SG_REL_ CGM_HS SG_ 1267 VehMassNom 1267;
BA_REL_ "GenSigSuprvResp" BU_SG_REL_ CGM_HS SG_ 1267 VehMassNom 1;
BA_REL_ "GenSigTimeoutTime" BU_SG_REL_ CGM_HS SG_ 1906 DTCI_DTCFaultType_772 2500;
BA_REL_ "GenSigTimeoutMsg" BU_SG_REL_ CGM_HS SG_ 1906 DTCI_DTCFaultType_772 1906;
BA_REL_ "GenSigSuprvResp" BU_SG_REL_ CGM_HS SG_ 1906 DTCI_DTCFaultType_772 1;
BA_REL_ "GenSigTimeoutTime" BU_SG_REL_ CGM_HS SG_ 1906 DTCI_CodeSupported_772 2500;
BA_REL_ "GenSigTimeoutMsg" BU_SG_REL_ CGM_HS SG_ 1906 DTCI_CodeSupported_772 1906;
BA_REL_ "GenSigSuprvResp" BU_SG_REL_ CGM_HS SG_ 1906 DTCI_CodeSupported_772 1;
BA_REL_ "GenSigTimeoutTime" BU_SG_REL_ CGM_HS SG_ 1906 DTCI_CurrentStatus_772 2500;
BA_REL_ "GenSigTimeoutMsg" BU_SG_REL_ CGM_HS SG_ 1906 DTCI_CurrentStatus_772 1906;
BA_REL_ "GenSigSuprvResp" BU_SG_REL_ CGM_HS SG_ 1906 DTCI_CurrentStatus_772 1;
BA_REL_ "GenSigTimeoutTime" BU_SG_REL_ CGM_HS SG_ 1906 DTCI_TstNPsdCdClrdSt_772 2500;
BA_REL_ "GenSigTimeoutMsg" BU_SG_REL_ CGM_HS SG_ 1906 DTCI_TstNPsdCdClrdSt_772 1906;
BA_REL_ "GenSigSuprvResp" BU_SG_REL_ CGM_HS SG_ 1906 DTCI_TstNPsdCdClrdSt_772 1;
BA_REL_ "GenSigTimeoutTime" BU_SG_REL_ CGM_HS SG_ 1906 DTCI_TstFldCdClrdStat_772 2500;
BA_REL_ "GenSigTimeoutMsg" BU_SG_REL_ CGM_HS SG_ 1906 DTCI_TstFldCdClrdStat_772 1906;
BA_REL_ "GenSigSuprvResp" BU_SG_REL_ CGM_HS SG_ 1906 DTCI_TstFldCdClrdStat_772 1;
BA_REL_ "GenSigTimeoutTime" BU_SG_REL_ CGM_HS SG_ 1906 DTCI_HistStat_772 2500;
BA_REL_ "GenSigTimeoutMsg" BU_SG_REL_ CGM_HS SG_ 1906 DTCI_HistStat_772 1906;
BA_REL_ "GenSigSuprvResp" BU_SG_REL_ CGM_HS SG_ 1906 DTCI_HistStat_772 1;
BA_REL_ "GenSigTimeoutTime" BU_SG_REL_ CGM_HS SG_ 1906 DTCI_TstNPsdPwrUpSt_772 2500;
BA_REL_ "GenSigTimeoutMsg" BU_SG_REL_ CGM_HS SG_ 1906 DTCI_TstNPsdPwrUpSt_772 1906;
BA_REL_ "GenSigSuprvResp" BU_SG_REL_ CGM_HS SG_ 1906 DTCI_TstNPsdPwrUpSt_772 1;
BA_REL_ "GenSigTimeoutTime" BU_SG_REL_ CGM_HS SG_ 1906 DTCI_TstFldPwrUpSt_772 2500;
BA_REL_ "GenSigTimeoutMsg" BU_SG_REL_ CGM_HS SG_ 1906 DTCI_TstFldPwrUpSt_772 1906;
BA_REL_ "GenSigSuprvResp" BU_SG_REL_ CGM_HS SG_ 1906 DTCI_TstFldPwrUpSt_772 1;
BA_REL_ "GenSigTimeoutTime" BU_SG_REL_ CGM_HS SG_ 1906 DTCI_WrnIndRqdSt_772 2500;
BA_REL_ "GenSigTimeoutMsg" BU_SG_REL_ CGM_HS SG_ 1906 DTCI_WrnIndRqdSt_772 1906;
BA_REL_ "GenSigSuprvResp" BU_SG_REL_ CGM_HS SG_ 1906 DTCI_WrnIndRqdSt_772 1;
BA_REL_ "GenSigTimeoutTime" BU_SG_REL_ CGM_HS SG_ 1906 DTCI_DTCFailType_772 2500;
BA_REL_ "GenSigTimeoutMsg" BU_SG_REL_ CGM_HS SG_ 1906 DTCI_DTCFailType_772 1906;
BA_REL_ "GenSigSuprvResp" BU_SG_REL_ CGM_HS SG_ 1906 DTCI_DTCFailType_772 1;
BA_REL_ "GenSigTimeoutTime" BU_SG_REL_ CGM_HS SG_ 1906 DTCI_DTCNumber_772 2500;
BA_REL_ "GenSigTimeoutMsg" BU_SG_REL_ CGM_HS SG_ 1906 DTCI_DTCNumber_772 1906;
BA_REL_ "GenSigSuprvResp" BU_SG_REL_ CGM_HS SG_ 1906 DTCI_DTCNumber_772 1;
BA_REL_ "GenSigTimeoutTime" BU_SG_REL_ CGM_HS SG_ 1906 DTCI_DTCSource_772 2500;
BA_REL_ "GenSigTimeoutMsg" BU_SG_REL_ CGM_HS SG_ 1906 DTCI_DTCSource_772 1906;
BA_REL_ "GenSigSuprvResp" BU_SG_REL_ CGM_HS SG_ 1906 DTCI_DTCSource_772 1;
BA_REL_ "GenSigTimeoutTime" BU_SG_REL_ CGM_HS SG_ 1906 DTCI_DTCTriggered_772 2500;
BA_REL_ "GenSigTimeoutMsg" BU_SG_REL_ CGM_HS SG_ 1906 DTCI_DTCTriggered_772 1906;
BA_REL_ "GenSigSuprvResp" BU_SG_REL_ CGM_HS SG_ 1906 DTCI_DTCTriggered_772 1;
BA_REL_ "GenSigTimeoutTime" BU_SG_REL_ CGM_HS SG_ 1906 DTCIUnused7_772 2500;
BA_REL_ "GenSigTimeoutMsg" BU_SG_REL_ CGM_HS SG_ 1906 DTCIUnused7_772 1906;
BA_REL_ "GenSigSuprvResp" BU_SG_REL_ CGM_HS SG_ 1906 DTCIUnused7_772 1;
BA_REL_ "GenSigTimeoutTime" BU_SG_REL_ CGM_HS SG_ 1906 DTCIUnused6_772 2500;
BA_REL_ "GenSigTimeoutMsg" BU_SG_REL_ CGM_HS SG_ 1906 DTCIUnused6_772 1906;
BA_REL_ "GenSigSuprvResp" BU_SG_REL_ CGM_HS SG_ 1906 DTCIUnused6_772 1;
BA_REL_ "GenSigTimeoutTime" BU_SG_REL_ CGM_HS SG_ 1906 DTCIUnused5_772 2500;
BA_REL_ "GenSigTimeoutMsg" BU_SG_REL_ CGM_HS SG_ 1906 DTCIUnused5_772 1906;
BA_REL_ "GenSigSuprvResp" BU_SG_REL_ CGM_HS SG_ 1906 DTCIUnused5_772 1;
BA_REL_ "GenSigTimeoutTime" BU_SG_REL_ CGM_HS SG_ 1906 DTCIUnused4_772 2500;
BA_REL_ "GenSigTimeoutMsg" BU_SG_REL_ CGM_HS SG_ 1906 DTCIUnused4_772 1906;
BA_REL_ "GenSigSuprvResp" BU_SG_REL_ CGM_HS SG_ 1906 DTCIUnused4_772 1;
BA_REL_ "GenSigTimeoutTime" BU_SG_REL_ CGM_HS SG_ 1906 DTCIUnused3_772 2500;
BA_REL_ "GenSigTimeoutMsg" BU_SG_REL_ CGM_HS SG_ 1906 DTCIUnused3_772 1906;
BA_REL_ "GenSigSuprvResp" BU_SG_REL_ CGM_HS SG_ 1906 DTCIUnused3_772 1;
BA_REL_ "GenSigTimeoutTime" BU_SG_REL_ CGM_HS SG_ 1906 DTCIUnused2_772 2500;
BA_REL_ "GenSigTimeoutMsg" BU_SG_REL_ CGM_HS SG_ 1906 DTCIUnused2_772 1906;
BA_REL_ "GenSigSuprvResp" BU_SG_REL_ CGM_HS SG_ 1906 DTCIUnused2_772 1;
BA_REL_ "GenSigTimeoutTime" BU_SG_REL_ CGM_HS SG_ 1906 DTCIUnused1_772 2500;
BA_REL_ "GenSigTimeoutMsg" BU_SG_REL_ CGM_HS SG_ 1906 DTCIUnused1_772 1906;
BA_REL_ "GenSigSuprvResp" BU_SG_REL_ CGM_HS SG_ 1906 DTCIUnused1_772 1;
BA_REL_ "GenSigTimeoutTime" BU_SG_REL_ TCM_HS SG_ 401 TrnsEngSpdReqFld 31;
BA_REL_ "GenSigTimeoutMsg" BU_SG_REL_ TCM_HS SG_ 401 TrnsEngSpdReqFld 401;
BA_REL_ "GenSigSuprvResp" BU_SG_REL_ TCM_HS SG_ 401 TrnsEngSpdReqFld 1;
BA_REL_ "GenSigTimeoutTime" BU_SG_REL_ TCM_HS SG_ 401 EngTrqTnsRqFld 31;
BA_REL_ "GenSigTimeoutMsg" BU_SG_REL_ TCM_HS SG_ 401 EngTrqTnsRqFld 401;
BA_REL_ "GenSigSuprvResp" BU_SG_REL_ TCM_HS SG_ 401 EngTrqTnsRqFld 1;
BA_REL_ "GenSigTimeoutTime" BU_SG_REL_ EBCM_HS SG_ 872 ESBR_AutoBrkgRqTyp 250;
BA_REL_ "GenSigTimeoutMsg" BU_SG_REL_ EBCM_HS SG_ 872 ESBR_AutoBrkgRqTyp 872;
BA_REL_ "GenSigSuprvResp" BU_SG_REL_ EBCM_HS SG_ 872 ESBR_AutoBrkgRqTyp 1;
BA_REL_ "GenSigTimeoutTime" BU_SG_REL_ EBCM_HS SG_ 872 ESBR_AutoBrkgRqd 250;
BA_REL_ "GenSigTimeoutMsg" BU_SG_REL_ EBCM_HS SG_ 872 ESBR_AutoBrkgRqd 872;
BA_REL_ "GenSigSuprvResp" BU_SG_REL_ EBCM_HS SG_ 872 ESBR_AutoBrkgRqd 1;
BA_REL_ "GenSigTimeoutTime" BU_SG_REL_ EBCM_HS SG_ 331 TrlrProfSel 2500;
BA_REL_ "GenSigTimeoutMsg" BU_SG_REL_ EBCM_HS SG_ 331 TrlrProfSel 331;
BA_REL_ "GenSigSuprvResp" BU_SG_REL_ EBCM_HS SG_ 331 TrlrProfSel 1;
BA_REL_ "GenSigTimeoutTime" BU_SG_REL_ EBCM_HS SG_ 1034 CRL_Cnfdnc 1000;
BA_REL_ "GenSigTimeoutMsg" BU_SG_REL_ EBCM_HS SG_ 1034 CRL_Cnfdnc 1034;
BA_REL_ "GenSigSuprvResp" BU_SG_REL_ EBCM_HS SG_ 1034 CRL_Cnfdnc 1;
BA_REL_ "GenSigTimeoutTime" BU_SG_REL_ EBCM_HS SG_ 1034 CRL_ViewRng 1000;
BA_REL_ "GenSigTimeoutMsg" BU_SG_REL_ EBCM_HS SG_ 1034 CRL_ViewRng 1034;
BA_REL_ "GenSigSuprvResp" BU_SG_REL_ EBCM_HS SG_ 1034 CRL_ViewRng 1;
BA_REL_ "GenSigTimeoutTime" BU_SG_REL_ EBCM_HS SG_ 1034 CRL_CoefdA 1000;
BA_REL_ "GenSigTimeoutMsg" BU_SG_REL_ EBCM_HS SG_ 1034 CRL_CoefdA 1034;
BA_REL_ "GenSigSuprvResp" BU_SG_REL_ EBCM_HS SG_ 1034 CRL_CoefdA 1;
BA_REL_ "GenSigTimeoutTime" BU_SG_REL_ EBCM_HS SG_ 1034 CRL_CoefA 1000;
BA_REL_ "GenSigTimeoutMsg" BU_SG_REL_ EBCM_HS SG_ 1034 CRL_CoefA 1034;
BA_REL_ "GenSigSuprvResp" BU_SG_REL_ EBCM_HS SG_ 1034 CRL_CoefA 1;
BA_REL_ "GenSigTimeoutTime" BU_SG_REL_ EBCM_HS SG_ 1033 CLL_Cnfdnc 1000;
BA_REL_ "GenSigTimeoutMsg" BU_SG_REL_ EBCM_HS SG_ 1033 CLL_Cnfdnc 1033;
BA_REL_ "GenSigSuprvResp" BU_SG_REL_ EBCM_HS SG_ 1033 CLL_Cnfdnc 1;
BA_REL_ "GenSigTimeoutTime" BU_SG_REL_ EBCM_HS SG_ 1033 CLL_ViewRng 1000;
BA_REL_ "GenSigTimeoutMsg" BU_SG_REL_ EBCM_HS SG_ 1033 CLL_ViewRng 1033;
BA_REL_ "GenSigSuprvResp" BU_SG_REL_ EBCM_HS SG_ 1033 CLL_ViewRng 1;
BA_REL_ "GenSigTimeoutTime" BU_SG_REL_ EBCM_HS SG_ 1033 CLL_CoefdA 1000;
BA_REL_ "GenSigTimeoutMsg" BU_SG_REL_ EBCM_HS SG_ 1033 CLL_CoefdA 1033;
BA_REL_ "GenSigSuprvResp" BU_SG_REL_ EBCM_HS SG_ 1033 CLL_CoefdA 1;
BA_REL_ "GenSigTimeoutTime" BU_SG_REL_ EBCM_HS SG_ 1033 CLL_CoefA 1000;
BA_REL_ "GenSigTimeoutMsg" BU_SG_REL_ EBCM_HS SG_ 1033 CLL_CoefA 1033;
BA_REL_ "GenSigSuprvResp" BU_SG_REL_ EBCM_HS SG_ 1033 CLL_CoefA 1;
BA_REL_ "GenSigTimeoutTime" BU_SG_REL_ EBCM_HS SG_ 1013 TrnRqHRBkCtlTgtVSpd 625;
BA_REL_ "GenSigTimeoutMsg" BU_SG_REL_ EBCM_HS SG_ 1013 TrnRqHRBkCtlTgtVSpd 1013;
BA_REL_ "GenSigSuprvResp" BU_SG_REL_ EBCM_HS SG_ 1013 TrnRqHRBkCtlTgtVSpd 1;
BA_REL_ "GenSigTimeoutTime" BU_SG_REL_ EBCM_HS SG_ 1013 TransReqHSAAval 625;
BA_REL_ "GenSigTimeoutMsg" BU_SG_REL_ EBCM_HS SG_ 1013 TransReqHSAAval 1013;
BA_REL_ "GenSigSuprvResp" BU_SG_REL_ EBCM_HS SG_ 1013 TransReqHSAAval 1;
BA_REL_ "GenSigTimeoutTime" BU_SG_REL_ TCM_HS SG_ 1013 MtrBCoolFlwCmd 625;
BA_REL_ "GenSigTimeoutMsg" BU_SG_REL_ TCM_HS SG_ 1013 MtrBCoolFlwCmd 1013;
BA_REL_ "GenSigSuprvResp" BU_SG_REL_ TCM_HS SG_ 1013 MtrBCoolFlwCmd 1;
BA_REL_ "GenSigTimeoutTime" BU_SG_REL_ TCM_HS SG_ 1013 MtrACoolFlwCmd 625;
BA_REL_ "GenSigTimeoutMsg" BU_SG_REL_ TCM_HS SG_ 1013 MtrACoolFlwCmd 1013;
BA_REL_ "GenSigSuprvResp" BU_SG_REL_ TCM_HS SG_ 1013 MtrACoolFlwCmd 1;
BA_REL_ "GenSigTimeoutTime" BU_SG_REL_ ECM_HS SG_ 1013 TRDLF_TrnsFwDrvRDLFlt 625;
BA_REL_ "GenSigTimeoutMsg" BU_SG_REL_ ECM_HS SG_ 1013 TRDLF_TrnsFwDrvRDLFlt 1013;
BA_REL_ "GenSigSuprvResp" BU_SG_REL_ ECM_HS SG_ 1013 TRDLF_TrnsFwDrvRDLFlt 1;
BA_REL_ "GenSigTimeoutTime" BU_SG_REL_ ECM_HS SG_ 1013 TRDLF_TrnsNtRgDgLtFlt 625;
BA_REL_ "GenSigTimeoutMsg" BU_SG_REL_ ECM_HS SG_ 1013 TRDLF_TrnsNtRgDgLtFlt 1013;
BA_REL_ "GenSigSuprvResp" BU_SG_REL_ ECM_HS SG_ 1013 TRDLF_TrnsNtRgDgLtFlt 1;
BA_REL_ "GenSigTimeoutTime" BU_SG_REL_ ECM_HS SG_ 1013 TRDLF_TrnsRvRgDgLtFlt 625;
BA_REL_ "GenSigTimeoutMsg" BU_SG_REL_ ECM_HS SG_ 1013 TRDLF_TrnsRvRgDgLtFlt 1013;
BA_REL_ "GenSigSuprvResp" BU_SG_REL_ ECM_HS SG_ 1013 TRDLF_TrnsRvRgDgLtFlt 1;
BA_REL_ "GenSigTimeoutTime" BU_SG_REL_ ECM_HS SG_ 1013 TRDLF_TrnsPkRgDgLtFlt 625;
BA_REL_ "GenSigTimeoutMsg" BU_SG_REL_ ECM_HS SG_ 1013 TRDLF_TrnsPkRgDgLtFlt 1013;
BA_REL_ "GenSigSuprvResp" BU_SG_REL_ ECM_HS SG_ 1013 TRDLF_TrnsPkRgDgLtFlt 1;
BA_REL_ "GenSigTimeoutTime" BU_SG_REL_ ECM_HS SG_ 1013 TRDCF_TrnsFwDrvRDCFlt 625;
BA_REL_ "GenSigTimeoutMsg" BU_SG_REL_ ECM_HS SG_ 1013 TRDCF_TrnsFwDrvRDCFlt 1013;
BA_REL_ "GenSigSuprvResp" BU_SG_REL_ ECM_HS SG_ 1013 TRDCF_TrnsFwDrvRDCFlt 1;
BA_REL_ "GenSigTimeoutTime" BU_SG_REL_ ECM_HS SG_ 1013 TRDCF_TrnsNtRgDgCtFlt 625;
BA_REL_ "GenSigTimeoutMsg" BU_SG_REL_ ECM_HS SG_ 1013 TRDCF_TrnsNtRgDgCtFlt 1013;
BA_REL_ "GenSigSuprvResp" BU_SG_REL_ ECM_HS SG_ 1013 TRDCF_TrnsNtRgDgCtFlt 1;
BA_REL_ "GenSigTimeoutTime" BU_SG_REL_ ECM_HS SG_ 1013 TRDCF_TrnsRvRgDgCtFlt 625;
BA_REL_ "GenSigTimeoutMsg" BU_SG_REL_ ECM_HS SG_ 1013 TRDCF_TrnsRvRgDgCtFlt 1013;
BA_REL_ "GenSigSuprvResp" BU_SG_REL_ ECM_HS SG_ 1013 TRDCF_TrnsRvRgDgCtFlt 1;
BA_REL_ "GenSigTimeoutTime" BU_SG_REL_ ECM_HS SG_ 1013 TRDCF_TrnsPkRgDgCtFlt 625;
BA_REL_ "GenSigTimeoutMsg" BU_SG_REL_ ECM_HS SG_ 1013 TRDCF_TrnsPkRgDgCtFlt 1013;
BA_REL_ "GenSigSuprvResp" BU_SG_REL_ ECM_HS SG_ 1013 TRDCF_TrnsPkRgDgCtFlt 1;
BA_REL_ "GenSigTimeoutTime" BU_SG_REL_ TCM_HS SG_ 170 AccPos 250;
BA_REL_ "GenSigTimeoutMsg" BU_SG_REL_ TCM_HS SG_ 170 AccPos 170;
BA_REL_ "GenSigSuprvResp" BU_SG_REL_ TCM_HS SG_ 170 AccPos 1;
BA_REL_ "GenSigTimeoutTime" BU_SG_REL_ EBCM_HS SG_ 170 CmndAxlTrqPredct 250;
BA_REL_ "GenSigTimeoutMsg" BU_SG_REL_ EBCM_HS SG_ 170 CmndAxlTrqPredct 170;
BA_REL_ "GenSigSuprvResp" BU_SG_REL_ EBCM_HS SG_ 170 CmndAxlTrqPredct 1;
BA_REL_ "GenSigTimeoutTime" BU_SG_REL_ TCM_HS SG_ 647 DrvTrkModeCmnd 62;
BA_REL_ "GenSigTimeoutMsg" BU_SG_REL_ TCM_HS SG_ 647 DrvTrkModeCmnd 647;
BA_REL_ "GenSigSuprvResp" BU_SG_REL_ TCM_HS SG_ 647 DrvTrkModeCmnd 1;
BA_REL_ "GenSigTimeoutTime" BU_SG_REL_ TCM_HS SG_ 647 DrvCrwlModeCmnd 62;
BA_REL_ "GenSigTimeoutMsg" BU_SG_REL_ TCM_HS SG_ 647 DrvCrwlModeCmnd 647;
BA_REL_ "GenSigSuprvResp" BU_SG_REL_ TCM_HS SG_ 647 DrvCrwlModeCmnd 1;
BA_REL_ "GenSigTimeoutTime" BU_SG_REL_ TCM_HS SG_ 647 CrnksftTqModRspMxCap 62;
BA_REL_ "GenSigTimeoutMsg" BU_SG_REL_ TCM_HS SG_ 647 CrnksftTqModRspMxCap 647;
BA_REL_ "GenSigSuprvResp" BU_SG_REL_ TCM_HS SG_ 647 CrnksftTqModRspMxCap 1;
BA_REL_ "GenSigTimeoutTime" BU_SG_REL_ TCM_HS SG_ 647 EngDetPndTrnCsRngShf 62;
BA_REL_ "GenSigTimeoutMsg" BU_SG_REL_ TCM_HS SG_ 647 EngDetPndTrnCsRngShf 647;
BA_REL_ "GenSigSuprvResp" BU_SG_REL_ TCM_HS SG_ 647 EngDetPndTrnCsRngShf 1;
BA_REL_ "GenSigTimeoutTime" BU_SG_REL_ TCM_HS SG_ 647 EngCntDtIntRSnsPsWdt 62;
BA_REL_ "GenSigTimeoutMsg" BU_SG_REL_ TCM_HS SG_ 647 EngCntDtIntRSnsPsWdt 647;
BA_REL_ "GenSigSuprvResp" BU_SG_REL_ TCM_HS SG_ 647 EngCntDtIntRSnsPsWdt 1;
BA_REL_ "GenSigTimeoutTime" BU_SG_REL_ TCM_HS SG_ 647 CrpCstCrvCmd 62;
BA_REL_ "GenSigTimeoutMsg" BU_SG_REL_ TCM_HS SG_ 647 CrpCstCrvCmd 647;
BA_REL_ "GenSigSuprvResp" BU_SG_REL_ TCM_HS SG_ 647 CrpCstCrvCmd 1;
BA_REL_ "GenSigTimeoutTime" BU_SG_REL_ TCM_HS SG_ 647 DrPTGrdBrkDsbMdCmd 62;
BA_REL_ "GenSigTimeoutMsg" BU_SG_REL_ TCM_HS SG_ 647 DrPTGrdBrkDsbMdCmd 647;
BA_REL_ "GenSigSuprvResp" BU_SG_REL_ TCM_HS SG_ 647 DrPTGrdBrkDsbMdCmd 1;
BA_REL_ "GenSigTimeoutTime" BU_SG_REL_ TCM_HS SG_ 647 DrvWntrMdCmd 62;
BA_REL_ "GenSigTimeoutMsg" BU_SG_REL_ TCM_HS SG_ 647 DrvWntrMdCmd 647;
BA_REL_ "GenSigSuprvResp" BU_SG_REL_ TCM_HS SG_ 647 DrvWntrMdCmd 1;
BA_REL_ "GenSigTimeoutTime" BU_SG_REL_ TCM_HS SG_ 647 DrvTwHaulMdCmd 62;
BA_REL_ "GenSigTimeoutMsg" BU_SG_REL_ TCM_HS SG_ 647 DrvTwHaulMdCmd 647;
BA_REL_ "GenSigSuprvResp" BU_SG_REL_ TCM_HS SG_ 647 DrvTwHaulMdCmd 1;
BA_REL_ "GenSigTimeoutTime" BU_SG_REL_ TCM_HS SG_ 647 DrvSprtMdCmd 62;
BA_REL_ "GenSigTimeoutMsg" BU_SG_REL_ TCM_HS SG_ 647 DrvSprtMdCmd 647;
BA_REL_ "GenSigSuprvResp" BU_SG_REL_ TCM_HS SG_ 647 DrvSprtMdCmd 1;
BA_REL_ "GenSigTimeoutTime" BU_SG_REL_ TCM_HS SG_ 647 DrvEconMdCmd 62;
BA_REL_ "GenSigTimeoutMsg" BU_SG_REL_ TCM_HS SG_ 647 DrvEconMdCmd 647;
BA_REL_ "GenSigSuprvResp" BU_SG_REL_ TCM_HS SG_ 647 DrvEconMdCmd 1;
BA_REL_ "GenSigTimeoutTime" BU_SG_REL_ EBCM_HS SG_ 647 EngCtrlUtldTrnCRgPVal 250;
BA_REL_ "GenSigTimeoutMsg" BU_SG_REL_ EBCM_HS SG_ 647 EngCtrlUtldTrnCRgPVal 647;
BA_REL_ "GenSigSuprvResp" BU_SG_REL_ EBCM_HS SG_ 647 EngCtrlUtldTrnCRgPVal 1;
BA_REL_ "GenSigTimeoutTime" BU_SG_REL_ EBCM_HS SG_ 647 EngCntrlUtldTrnCsRng 250;
BA_REL_ "GenSigTimeoutMsg" BU_SG_REL_ EBCM_HS SG_ 647 EngCntrlUtldTrnCsRng 647;
BA_REL_ "GenSigSuprvResp" BU_SG_REL_ EBCM_HS SG_ 647 EngCntrlUtldTrnCsRng 1;
BA_REL_ "GenSigTimeoutTime" BU_SG_REL_ EBCM_HS SG_ 647 EngCntrlUtldTrnCsRgIn 250;
BA_REL_ "GenSigTimeoutMsg" BU_SG_REL_ EBCM_HS SG_ 647 EngCntrlUtldTrnCsRgIn 647;
BA_REL_ "GenSigSuprvResp" BU_SG_REL_ EBCM_HS SG_ 647 EngCntrlUtldTrnCsRgIn 1;
BA_REL_ "GenSigTimeoutTime" BU_SG_REL_ EBCM_HS SG_ 647 EngCtrlUtldTrnCRgARC 250;
BA_REL_ "GenSigTimeoutMsg" BU_SG_REL_ EBCM_HS SG_ 647 EngCtrlUtldTrnCRgARC 647;
BA_REL_ "GenSigSuprvResp" BU_SG_REL_ EBCM_HS SG_ 647 EngCtrlUtldTrnCRgARC 1;
BA_REL_ "GenSigTimeoutTime" BU_SG_REL_ ECM_HS SG_ 199 TORSTimestamp 250;
BA_REL_ "GenSigTimeoutMsg" BU_SG_REL_ ECM_HS SG_ 199 TORSTimestamp 199;
BA_REL_ "GenSigSuprvResp" BU_SG_REL_ ECM_HS SG_ 199 TORSTimestamp 1;
BA_REL_ "GenSigTimeoutTime" BU_SG_REL_ EBCM_HS SG_ 199 TORSTimestamp 250;
BA_REL_ "GenSigTimeoutMsg" BU_SG_REL_ EBCM_HS SG_ 199 TORSTimestamp 199;
BA_REL_ "GenSigSuprvResp" BU_SG_REL_ EBCM_HS SG_ 199 TORSTimestamp 1;
BA_REL_ "GenSigTimeoutTime" BU_SG_REL_ ECM_HS SG_ 199 TORSPulsCntr 250;
BA_REL_ "GenSigTimeoutMsg" BU_SG_REL_ ECM_HS SG_ 199 TORSPulsCntr 199;
BA_REL_ "GenSigSuprvResp" BU_SG_REL_ ECM_HS SG_ 199 TORSPulsCntr 1;
BA_REL_ "GenSigTimeoutTime" BU_SG_REL_ EBCM_HS SG_ 199 TORSPulsCntr 250;
BA_REL_ "GenSigTimeoutMsg" BU_SG_REL_ EBCM_HS SG_ 199 TORSPulsCntr 199;
BA_REL_ "GenSigSuprvResp" BU_SG_REL_ EBCM_HS SG_ 199 TORSPulsCntr 1;
BA_REL_ "GenSigTimeoutTime" BU_SG_REL_ ECM_HS SG_ 199 TORSValidity 250;
BA_REL_ "GenSigTimeoutMsg" BU_SG_REL_ ECM_HS SG_ 199 TORSValidity 199;
BA_REL_ "GenSigSuprvResp" BU_SG_REL_ ECM_HS SG_ 199 TORSValidity 1;
BA_REL_ "GenSigTimeoutTime" BU_SG_REL_ EBCM_HS SG_ 199 TORSValidity 250;
BA_REL_ "GenSigTimeoutMsg" BU_SG_REL_ EBCM_HS SG_ 199 TORSValidity 199;
BA_REL_ "GenSigSuprvResp" BU_SG_REL_ EBCM_HS SG_ 199 TORSValidity 1;
BA_REL_ "GenSigTimeoutTime" BU_SG_REL_ ECM_HS SG_ 199 TORSRstOcrd 250;
BA_REL_ "GenSigTimeoutMsg" BU_SG_REL_ ECM_HS SG_ 199 TORSRstOcrd 199;
BA_REL_ "GenSigSuprvResp" BU_SG_REL_ ECM_HS SG_ 199 TORSRstOcrd 1;
BA_REL_ "GenSigTimeoutTime" BU_SG_REL_ EBCM_HS SG_ 199 TORSRstOcrd 250;
BA_REL_ "GenSigTimeoutMsg" BU_SG_REL_ EBCM_HS SG_ 199 TORSRstOcrd 199;
BA_REL_ "GenSigSuprvResp" BU_SG_REL_ EBCM_HS SG_ 199 TORSRstOcrd 1;
BA_REL_ "GenSigTimeoutTime" BU_SG_REL_ ECM_HS SG_ 199 TORSLstTransType 250;
BA_REL_ "GenSigTimeoutMsg" BU_SG_REL_ ECM_HS SG_ 199 TORSLstTransType 199;
BA_REL_ "GenSigSuprvResp" BU_SG_REL_ ECM_HS SG_ 199 TORSLstTransType 1;
BA_REL_ "GenSigTimeoutTime" BU_SG_REL_ EBCM_HS SG_ 199 TORSLstTransType 250;
BA_REL_ "GenSigTimeoutMsg" BU_SG_REL_ EBCM_HS SG_ 199 TORSLstTransType 199;
BA_REL_ "GenSigSuprvResp" BU_SG_REL_ EBCM_HS SG_ 199 TORSLstTransType 1;
BA_REL_ "GenSigTimeoutTime" BU_SG_REL_ ECM_HS SG_ 199 TORSRotDir 250;
BA_REL_ "GenSigTimeoutMsg" BU_SG_REL_ ECM_HS SG_ 199 TORSRotDir 199;
BA_REL_ "GenSigSuprvResp" BU_SG_REL_ ECM_HS SG_ 199 TORSRotDir 1;
BA_REL_ "GenSigTimeoutTime" BU_SG_REL_ EBCM_HS SG_ 199 TORSRotDir 250;
BA_REL_ "GenSigTimeoutMsg" BU_SG_REL_ EBCM_HS SG_ 199 TORSRotDir 199;
BA_REL_ "GenSigSuprvResp" BU_SG_REL_ EBCM_HS SG_ 199 TORSRotDir 1;
BA_REL_ "GenSigTimeoutTime" BU_SG_REL_ TCM_HS SG_ 190 EngSpdMaxCapRdcdRng 250;
BA_REL_ "GenSigTimeoutMsg" BU_SG_REL_ TCM_HS SG_ 190 EngSpdMaxCapRdcdRng 190;
BA_REL_ "GenSigSuprvResp" BU_SG_REL_ TCM_HS SG_ 190 EngSpdMaxCapRdcdRng 1;
BA_REL_ "GenSigTimeoutTime" BU_SG_REL_ TCM_HS SG_ 190 TrnsAuxPmpAct 250;
BA_REL_ "GenSigTimeoutMsg" BU_SG_REL_ TCM_HS SG_ 190 TrnsAuxPmpAct 190;
BA_REL_ "GenSigSuprvResp" BU_SG_REL_ TCM_HS SG_ 190 TrnsAuxPmpAct 1;
BA_REL_ "GenSigTimeoutTime" BU_SG_REL_ TCM_HS SG_ 190 AccPos 250;
BA_REL_ "GenSigTimeoutMsg" BU_SG_REL_ TCM_HS SG_ 190 AccPos 190;
BA_REL_ "GenSigSuprvResp" BU_SG_REL_ TCM_HS SG_ 190 AccPos 1;
BA_REL_ "GenSigTimeoutTime" BU_SG_REL_ EBCM_HS SG_ 190 PSBPI_PTSnBrkPdlPsV 250;
BA_REL_ "GenSigTimeoutMsg" BU_SG_REL_ EBCM_HS SG_ 190 PSBPI_PTSnBrkPdlPsV 190;
BA_REL_ "GenSigSuprvResp" BU_SG_REL_ EBCM_HS SG_ 190 PSBPI_PTSnBrkPdlPsV 1;
BA_REL_ "GenSigTimeoutTime" BU_SG_REL_ EBCM_HS SG_ 190 PSBPI_PTSnBrkPdlPs 250;
BA_REL_ "GenSigTimeoutMsg" BU_SG_REL_ EBCM_HS SG_ 190 PSBPI_PTSnBrkPdlPs 190;
BA_REL_ "GenSigSuprvResp" BU_SG_REL_ EBCM_HS SG_ 190 PSBPI_PTSnBrkPdlPs 1;
BA_REL_ "GenSigTimeoutTime" BU_SG_REL_ EBCM_HS SG_ 707 CSTATRS_ReqStat 250;
BA_REL_ "GenSigTimeoutMsg" BU_SG_REL_ EBCM_HS SG_ 707 CSTATRS_ReqStat 707;
BA_REL_ "GenSigSuprvResp" BU_SG_REL_ EBCM_HS SG_ 707 CSTATRS_ReqStat 1;
BA_REL_ "GenSigTimeoutTime" BU_SG_REL_ EBCM_HS SG_ 707 CSTATRS_LmtgStat 250;
BA_REL_ "GenSigTimeoutMsg" BU_SG_REL_ EBCM_HS SG_ 707 CSTATRS_LmtgStat 707;
BA_REL_ "GenSigSuprvResp" BU_SG_REL_ EBCM_HS SG_ 707 CSTATRS_LmtgStat 1;
BA_REL_ "GenSigTimeoutTime" BU_SG_REL_ EBCM_HS SG_ 707 EngManfldAbsPrs 250;
BA_REL_ "GenSigTimeoutMsg" BU_SG_REL_ EBCM_HS SG_ 707 EngManfldAbsPrs 707;
BA_REL_ "GenSigSuprvResp" BU_SG_REL_ EBCM_HS SG_ 707 EngManfldAbsPrs 1;
BA_REL_ "GenSigTimeoutTime" BU_SG_REL_ EBCM_HS SG_ 707 EngTrqMinExtRng 250;
BA_REL_ "GenSigTimeoutMsg" BU_SG_REL_ EBCM_HS SG_ 707 EngTrqMinExtRng 707;
BA_REL_ "GenSigSuprvResp" BU_SG_REL_ EBCM_HS SG_ 707 EngTrqMinExtRng 1;
BA_REL_ "GenSigTimeoutTime" BU_SG_REL_ RDCM_HS SG_ 707 EngTrqMaxExtRng 250;
BA_REL_ "GenSigTimeoutMsg" BU_SG_REL_ RDCM_HS SG_ 707 EngTrqMaxExtRng 707;
BA_REL_ "GenSigVBitResp" BU_SG_REL_ RDCM_HS SG_ 707 EngTrqMaxExtRng 1;
BA_REL_ "GenSigSuprvResp" BU_SG_REL_ RDCM_HS SG_ 707 EngTrqMaxExtRng 1;
BA_REL_ "GenSigTimeoutTime" BU_SG_REL_ EBCM_HS SG_ 707 EngTrqMaxExtRng 250;
BA_REL_ "GenSigTimeoutMsg" BU_SG_REL_ EBCM_HS SG_ 707 EngTrqMaxExtRng 707;
BA_REL_ "GenSigSuprvResp" BU_SG_REL_ EBCM_HS SG_ 707 EngTrqMaxExtRng 1;
BA_REL_ "GenSigTimeoutTime" BU_SG_REL_ EBCM_HS SG_ 249 TrnsRqHSABrkPrDcyRt 250;
BA_REL_ "GenSigTimeoutMsg" BU_SG_REL_ EBCM_HS SG_ 249 TrnsRqHSABrkPrDcyRt 249;
BA_REL_ "GenSigSuprvResp" BU_SG_REL_ EBCM_HS SG_ 249 TrnsRqHSABrkPrDcyRt 1;
BA_REL_ "GenSigTimeoutTime" BU_SG_REL_ EBCM_HS SG_ 249 TrnsOtptRotRC 250;
BA_REL_ "GenSigTimeoutMsg" BU_SG_REL_ EBCM_HS SG_ 249 TrnsOtptRotRC 249;
BA_REL_ "GenSigSuprvResp" BU_SG_REL_ EBCM_HS SG_ 249 TrnsOtptRotRC 1;
BA_REL_ "GenSigTimeoutTime" BU_SG_REL_ EBCM_HS SG_ 249 TrnsOtptRotRCRstOcc 250;
BA_REL_ "GenSigTimeoutMsg" BU_SG_REL_ EBCM_HS SG_ 249 TrnsOtptRotRCRstOcc 249;
BA_REL_ "GenSigSuprvResp" BU_SG_REL_ EBCM_HS SG_ 249 TrnsOtptRotRCRstOcc 1;
BA_REL_ "GenSigTimeoutTime" BU_SG_REL_ EBCM_HS SG_ 249 TrnsOutShftAngVel 250;
BA_REL_ "GenSigTimeoutMsg" BU_SG_REL_ EBCM_HS SG_ 249 TrnsOutShftAngVel 249;
BA_REL_ "GenSigSuprvResp" BU_SG_REL_ EBCM_HS SG_ 249 TrnsOutShftAngVel 1;
BA_REL_ "GenSigTimeoutTime" BU_SG_REL_ RDCM_HS SG_ 249 TrnsOvrallEstTorqRatio 250;
BA_REL_ "GenSigTimeoutMsg" BU_SG_REL_ RDCM_HS SG_ 249 TrnsOvrallEstTorqRatio 249;
BA_REL_ "GenSigVBitResp" BU_SG_REL_ RDCM_HS SG_ 249 TrnsOvrallEstTorqRatio 1;
BA_REL_ "GenSigSuprvResp" BU_SG_REL_ RDCM_HS SG_ 249 TrnsOvrallEstTorqRatio 1;
BA_REL_ "GenSigTimeoutTime" BU_SG_REL_ EBCM_HS SG_ 249 TrnsOvrallEstTorqRatio 250;
BA_REL_ "GenSigTimeoutMsg" BU_SG_REL_ EBCM_HS SG_ 249 TrnsOvrallEstTorqRatio 249;
BA_REL_ "GenSigSuprvResp" BU_SG_REL_ EBCM_HS SG_ 249 TrnsOvrallEstTorqRatio 1;
BA_REL_ "GenSigTimeoutTime" BU_SG_REL_ ECM_HS SG_ 1273 BrkSyCtl1EmsRldMlfAct 1250;
BA_REL_ "GenSigTimeoutMsg" BU_SG_REL_ ECM_HS SG_ 1273 BrkSyCtl1EmsRldMlfAct 1273;
BA_REL_ "GenSigSuprvResp" BU_SG_REL_ ECM_HS SG_ 1273 BrkSyCtl1EmsRldMlfAct 1;
BA_REL_ "GenSigTimeoutTime" BU_SG_REL_ CGM_HS SG_ 1273 BSC1ERDTC_CdNum 1250;
BA_REL_ "GenSigTimeoutMsg" BU_SG_REL_ CGM_HS SG_ 1273 BSC1ERDTC_CdNum 1273;
BA_REL_ "GenSigSuprvResp" BU_SG_REL_ CGM_HS SG_ 1273 BSC1ERDTC_CdNum 1;
BA_REL_ "GenSigTimeoutTime" BU_SG_REL_ ECM_HS SG_ 1273 BSC1ERDTC_CdNum 1250;
BA_REL_ "GenSigTimeoutMsg" BU_SG_REL_ ECM_HS SG_ 1273 BSC1ERDTC_CdNum 1273;
BA_REL_ "GenSigSuprvResp" BU_SG_REL_ ECM_HS SG_ 1273 BSC1ERDTC_CdNum 1;
BA_REL_ "GenSigTimeoutTime" BU_SG_REL_ CGM_HS SG_ 1273 BSC1ERDTC_SysDes 1250;
BA_REL_ "GenSigTimeoutMsg" BU_SG_REL_ CGM_HS SG_ 1273 BSC1ERDTC_SysDes 1273;
BA_REL_ "GenSigSuprvResp" BU_SG_REL_ CGM_HS SG_ 1273 BSC1ERDTC_SysDes 1;
BA_REL_ "GenSigTimeoutTime" BU_SG_REL_ ECM_HS SG_ 1273 BSC1ERDTC_SysDes 1250;
BA_REL_ "GenSigTimeoutMsg" BU_SG_REL_ ECM_HS SG_ 1273 BSC1ERDTC_SysDes 1273;
BA_REL_ "GenSigSuprvResp" BU_SG_REL_ ECM_HS SG_ 1273 BSC1ERDTC_SysDes 1;
BA_REL_ "GenSigTimeoutTime" BU_SG_REL_ TCM_HS SG_ 208 WhlSlipRRWhl 250;
BA_REL_ "GenSigTimeoutMsg" BU_SG_REL_ TCM_HS SG_ 208 WhlSlipRRWhl 208;
BA_REL_ "GenSigSuprvResp" BU_SG_REL_ TCM_HS SG_ 208 WhlSlipRRWhl 1;
BA_REL_ "GenSigTimeoutTime" BU_SG_REL_ TCM_HS SG_ 208 WhlSlipRFWhl 250;
BA_REL_ "GenSigTimeoutMsg" BU_SG_REL_ TCM_HS SG_ 208 WhlSlipRFWhl 208;
BA_REL_ "GenSigSuprvResp" BU_SG_REL_ TCM_HS SG_ 208 WhlSlipRFWhl 1;
BA_REL_ "GenSigTimeoutTime" BU_SG_REL_ TCM_HS SG_ 208 WhlSlipLRWhl 250;
BA_REL_ "GenSigTimeoutMsg" BU_SG_REL_ TCM_HS SG_ 208 WhlSlipLRWhl 208;
BA_REL_ "GenSigSuprvResp" BU_SG_REL_ TCM_HS SG_ 208 WhlSlipLRWhl 1;
BA_REL_ "GenSigTimeoutTime" BU_SG_REL_ TCM_HS SG_ 208 WhlSlipLFWhl 250;
BA_REL_ "GenSigTimeoutMsg" BU_SG_REL_ TCM_HS SG_ 208 WhlSlipLFWhl 208;
BA_REL_ "GenSigSuprvResp" BU_SG_REL_ TCM_HS SG_ 208 WhlSlipLFWhl 1;
BA_REL_ "GenSigTimeoutTime" BU_SG_REL_ TCM_HS SG_ 508 LonLatAccSnsChk 125;
BA_REL_ "GenSigTimeoutMsg" BU_SG_REL_ TCM_HS SG_ 508 LonLatAccSnsChk 508;
BA_REL_ "GenSigSuprvResp" BU_SG_REL_ TCM_HS SG_ 508 LonLatAccSnsChk 1;
BA_REL_ "GenSigTimeoutTime" BU_SG_REL_ TCM_HS SG_ 508 LonLatAccSnsValARC 125;
BA_REL_ "GenSigTimeoutMsg" BU_SG_REL_ TCM_HS SG_ 508 LonLatAccSnsValARC 508;
BA_REL_ "GenSigSuprvResp" BU_SG_REL_ TCM_HS SG_ 508 LonLatAccSnsValARC 1;
BA_REL_ "GenSigTimeoutTime" BU_SG_REL_ TCM_HS SG_ 508 LatAccSnsVal 125;
BA_REL_ "GenSigTimeoutMsg" BU_SG_REL_ TCM_HS SG_ 508 LatAccSnsVal 508;
BA_REL_ "GenSigSuprvResp" BU_SG_REL_ TCM_HS SG_ 508 LatAccSnsVal 1;
BA_REL_ "GenSigTimeoutTime" BU_SG_REL_ ECM_HS SG_ 508 LatAccSnsVal 250;
BA_REL_ "GenSigTimeoutMsg" BU_SG_REL_ ECM_HS SG_ 508 LatAccSnsVal 508;
BA_REL_ "GenSigSuprvResp" BU_SG_REL_ ECM_HS SG_ 508 LatAccSnsVal 1;
BA_REL_ "GenSigTimeoutTime" BU_SG_REL_ TCM_HS SG_ 508 LonAccSnsVal 125;
BA_REL_ "GenSigTimeoutMsg" BU_SG_REL_ TCM_HS SG_ 508 LonAccSnsVal 508;
BA_REL_ "GenSigSuprvResp" BU_SG_REL_ TCM_HS SG_ 508 LonAccSnsVal 1;
BA_REL_ "GenSigTimeoutTime" BU_SG_REL_ ECM_HS SG_ 508 LonAccSnsVal 250;
BA_REL_ "GenSigTimeoutMsg" BU_SG_REL_ ECM_HS SG_ 508 LonAccSnsVal 508;
BA_REL_ "GenSigSuprvResp" BU_SG_REL_ ECM_HS SG_ 508 LonAccSnsVal 1;
BA_REL_ "GenSigTimeoutTime" BU_SG_REL_ TCM_HS SG_ 508 CSTBATS_TrqVl 125;
BA_REL_ "GenSigTimeoutMsg" BU_SG_REL_ TCM_HS SG_ 508 CSTBATS_TrqVl 508;
BA_REL_ "GenSigSuprvResp" BU_SG_REL_ TCM_HS SG_ 508 CSTBATS_TrqVl 1;
BA_REL_ "GenSigTimeoutTime" BU_SG_REL_ ECM_HS SG_ 508 CSTBATS_TrqVl 250;
BA_REL_ "GenSigTimeoutMsg" BU_SG_REL_ ECM_HS SG_ 508 CSTBATS_TrqVl 508;
BA_REL_ "GenSigSuprvResp" BU_SG_REL_ ECM_HS SG_ 508 CSTBATS_TrqVl 1;
BA_REL_ "GenSigTimeoutTime" BU_SG_REL_ TCM_HS SG_ 508 CSTBATS_TrqVlV 125;
BA_REL_ "GenSigTimeoutMsg" BU_SG_REL_ TCM_HS SG_ 508 CSTBATS_TrqVlV 508;
BA_REL_ "GenSigSuprvResp" BU_SG_REL_ TCM_HS SG_ 508 CSTBATS_TrqVlV 1;
BA_REL_ "GenSigTimeoutTime" BU_SG_REL_ ECM_HS SG_ 508 CSTBATS_TrqVlV 250;
BA_REL_ "GenSigTimeoutMsg" BU_SG_REL_ ECM_HS SG_ 508 CSTBATS_TrqVlV 508;
BA_REL_ "GenSigSuprvResp" BU_SG_REL_ ECM_HS SG_ 508 CSTBATS_TrqVlV 1;
BA_REL_ "GenSigTimeoutTime" BU_SG_REL_ ECM_HS SG_ 454 APAAxlTrqRdctnAct 250;
BA_REL_ "GenSigTimeoutMsg" BU_SG_REL_ ECM_HS SG_ 454 APAAxlTrqRdctnAct 454;
BA_REL_ "GenSigSuprvResp" BU_SG_REL_ ECM_HS SG_ 454 APAAxlTrqRdctnAct 1;
BA_REL_ "GenSigTimeoutTime" BU_SG_REL_ ECM_HS SG_ 554 BrkSysVTopSpdLimRqTp 250;
BA_REL_ "GenSigTimeoutMsg" BU_SG_REL_ ECM_HS SG_ 554 BrkSysVTopSpdLimRqTp 554;
BA_REL_ "GenSigSuprvResp" BU_SG_REL_ ECM_HS SG_ 554 BrkSysVTopSpdLimRqTp 1;
BA_REL_ "GenSigTimeoutTime" BU_SG_REL_ TCM_HS SG_ 554 ElecPrkBrkAvailStat 250;
BA_REL_ "GenSigTimeoutMsg" BU_SG_REL_ TCM_HS SG_ 554 ElecPrkBrkAvailStat 554;
BA_REL_ "GenSigSuprvResp" BU_SG_REL_ TCM_HS SG_ 554 ElecPrkBrkAvailStat 1;
BA_REL_ "GenSigTimeoutTime" BU_SG_REL_ ECM_HS SG_ 554 ElecPrkBrkAvailStat 250;
BA_REL_ "GenSigTimeoutMsg" BU_SG_REL_ ECM_HS SG_ 554 ElecPrkBrkAvailStat 554;
BA_REL_ "GenSigSuprvResp" BU_SG_REL_ ECM_HS SG_ 554 ElecPrkBrkAvailStat 1;
BA_REL_ "GenSigTimeoutTime" BU_SG_REL_ TCM_HS SG_ 554 ElecPrkBrkApplStat 250;
BA_REL_ "GenSigTimeoutMsg" BU_SG_REL_ TCM_HS SG_ 554 ElecPrkBrkApplStat 554;
BA_REL_ "GenSigSuprvResp" BU_SG_REL_ TCM_HS SG_ 554 ElecPrkBrkApplStat 1;
BA_REL_ "GenSigTimeoutTime" BU_SG_REL_ ECM_HS SG_ 554 ElecPrkBrkApplStat 250;
BA_REL_ "GenSigTimeoutMsg" BU_SG_REL_ ECM_HS SG_ 554 ElecPrkBrkApplStat 554;
BA_REL_ "GenSigSuprvResp" BU_SG_REL_ ECM_HS SG_ 554 ElecPrkBrkApplStat 1;
BA_REL_ "GenSigTimeoutTime" BU_SG_REL_ CGM_HS SG_ 1907 DTCI_DTCFaultType_773 2500;
BA_REL_ "GenSigTimeoutMsg" BU_SG_REL_ CGM_HS SG_ 1907 DTCI_DTCFaultType_773 1907;
BA_REL_ "GenSigSuprvResp" BU_SG_REL_ CGM_HS SG_ 1907 DTCI_DTCFaultType_773 1;
BA_REL_ "GenSigTimeoutTime" BU_SG_REL_ CGM_HS SG_ 1907 DTCI_CodeSupported_773 2500;
BA_REL_ "GenSigTimeoutMsg" BU_SG_REL_ CGM_HS SG_ 1907 DTCI_CodeSupported_773 1907;
BA_REL_ "GenSigSuprvResp" BU_SG_REL_ CGM_HS SG_ 1907 DTCI_CodeSupported_773 1;
BA_REL_ "GenSigTimeoutTime" BU_SG_REL_ CGM_HS SG_ 1907 DTCI_CurrentStatus_773 2500;
BA_REL_ "GenSigTimeoutMsg" BU_SG_REL_ CGM_HS SG_ 1907 DTCI_CurrentStatus_773 1907;
BA_REL_ "GenSigSuprvResp" BU_SG_REL_ CGM_HS SG_ 1907 DTCI_CurrentStatus_773 1;
BA_REL_ "GenSigTimeoutTime" BU_SG_REL_ CGM_HS SG_ 1907 DTCI_TstNPsdCdClrdSt_773 2500;
BA_REL_ "GenSigTimeoutMsg" BU_SG_REL_ CGM_HS SG_ 1907 DTCI_TstNPsdCdClrdSt_773 1907;
BA_REL_ "GenSigSuprvResp" BU_SG_REL_ CGM_HS SG_ 1907 DTCI_TstNPsdCdClrdSt_773 1;
BA_REL_ "GenSigTimeoutTime" BU_SG_REL_ CGM_HS SG_ 1907 DTCI_TstFldCdClrdStat_773 2500;
BA_REL_ "GenSigTimeoutMsg" BU_SG_REL_ CGM_HS SG_ 1907 DTCI_TstFldCdClrdStat_773 1907;
BA_REL_ "GenSigSuprvResp" BU_SG_REL_ CGM_HS SG_ 1907 DTCI_TstFldCdClrdStat_773 1;
BA_REL_ "GenSigTimeoutTime" BU_SG_REL_ CGM_HS SG_ 1907 DTCI_HistStat_773 2500;
BA_REL_ "GenSigTimeoutMsg" BU_SG_REL_ CGM_HS SG_ 1907 DTCI_HistStat_773 1907;
BA_REL_ "GenSigSuprvResp" BU_SG_REL_ CGM_HS SG_ 1907 DTCI_HistStat_773 1;
BA_REL_ "GenSigTimeoutTime" BU_SG_REL_ CGM_HS SG_ 1907 DTCI_TstNPsdPwrUpSt_773 2500;
BA_REL_ "GenSigTimeoutMsg" BU_SG_REL_ CGM_HS SG_ 1907 DTCI_TstNPsdPwrUpSt_773 1907;
BA_REL_ "GenSigSuprvResp" BU_SG_REL_ CGM_HS SG_ 1907 DTCI_TstNPsdPwrUpSt_773 1;
BA_REL_ "GenSigTimeoutTime" BU_SG_REL_ CGM_HS SG_ 1907 DTCI_TstFldPwrUpSt_773 2500;
BA_REL_ "GenSigTimeoutMsg" BU_SG_REL_ CGM_HS SG_ 1907 DTCI_TstFldPwrUpSt_773 1907;
BA_REL_ "GenSigSuprvResp" BU_SG_REL_ CGM_HS SG_ 1907 DTCI_TstFldPwrUpSt_773 1;
BA_REL_ "GenSigTimeoutTime" BU_SG_REL_ CGM_HS SG_ 1907 DTCI_WrnIndRqdSt_773 2500;
BA_REL_ "GenSigTimeoutMsg" BU_SG_REL_ CGM_HS SG_ 1907 DTCI_WrnIndRqdSt_773 1907;
BA_REL_ "GenSigSuprvResp" BU_SG_REL_ CGM_HS SG_ 1907 DTCI_WrnIndRqdSt_773 1;
BA_REL_ "GenSigTimeoutTime" BU_SG_REL_ CGM_HS SG_ 1907 DTCI_DTCFailType_773 2500;
BA_REL_ "GenSigTimeoutMsg" BU_SG_REL_ CGM_HS SG_ 1907 DTCI_DTCFailType_773 1907;
BA_REL_ "GenSigSuprvResp" BU_SG_REL_ CGM_HS SG_ 1907 DTCI_DTCFailType_773 1;
BA_REL_ "GenSigTimeoutTime" BU_SG_REL_ CGM_HS SG_ 1907 DTCI_DTCNumber_773 2500;
BA_REL_ "GenSigTimeoutMsg" BU_SG_REL_ CGM_HS SG_ 1907 DTCI_DTCNumber_773 1907;
BA_REL_ "GenSigSuprvResp" BU_SG_REL_ CGM_HS SG_ 1907 DTCI_DTCNumber_773 1;
BA_REL_ "GenSigTimeoutTime" BU_SG_REL_ CGM_HS SG_ 1907 DTCI_DTCSource_773 2500;
BA_REL_ "GenSigTimeoutMsg" BU_SG_REL_ CGM_HS SG_ 1907 DTCI_DTCSource_773 1907;
BA_REL_ "GenSigSuprvResp" BU_SG_REL_ CGM_HS SG_ 1907 DTCI_DTCSource_773 1;
BA_REL_ "GenSigTimeoutTime" BU_SG_REL_ CGM_HS SG_ 1907 DTCI_DTCTriggered_773 2500;
BA_REL_ "GenSigTimeoutMsg" BU_SG_REL_ CGM_HS SG_ 1907 DTCI_DTCTriggered_773 1907;
BA_REL_ "GenSigSuprvResp" BU_SG_REL_ CGM_HS SG_ 1907 DTCI_DTCTriggered_773 1;
BA_REL_ "GenSigTimeoutTime" BU_SG_REL_ CGM_HS SG_ 1907 DTCIUnused7_773 2500;
BA_REL_ "GenSigTimeoutMsg" BU_SG_REL_ CGM_HS SG_ 1907 DTCIUnused7_773 1907;
BA_REL_ "GenSigSuprvResp" BU_SG_REL_ CGM_HS SG_ 1907 DTCIUnused7_773 1;
BA_REL_ "GenSigTimeoutTime" BU_SG_REL_ CGM_HS SG_ 1907 DTCIUnused6_773 2500;
BA_REL_ "GenSigTimeoutMsg" BU_SG_REL_ CGM_HS SG_ 1907 DTCIUnused6_773 1907;
BA_REL_ "GenSigSuprvResp" BU_SG_REL_ CGM_HS SG_ 1907 DTCIUnused6_773 1;
BA_REL_ "GenSigTimeoutTime" BU_SG_REL_ CGM_HS SG_ 1907 DTCIUnused5_773 2500;
BA_REL_ "GenSigTimeoutMsg" BU_SG_REL_ CGM_HS SG_ 1907 DTCIUnused5_773 1907;
BA_REL_ "GenSigSuprvResp" BU_SG_REL_ CGM_HS SG_ 1907 DTCIUnused5_773 1;
BA_REL_ "GenSigTimeoutTime" BU_SG_REL_ CGM_HS SG_ 1907 DTCIUnused4_773 2500;
BA_REL_ "GenSigTimeoutMsg" BU_SG_REL_ CGM_HS SG_ 1907 DTCIUnused4_773 1907;
BA_REL_ "GenSigSuprvResp" BU_SG_REL_ CGM_HS SG_ 1907 DTCIUnused4_773 1;
BA_REL_ "GenSigTimeoutTime" BU_SG_REL_ CGM_HS SG_ 1907 DTCIUnused3_773 2500;
BA_REL_ "GenSigTimeoutMsg" BU_SG_REL_ CGM_HS SG_ 1907 DTCIUnused3_773 1907;
BA_REL_ "GenSigSuprvResp" BU_SG_REL_ CGM_HS SG_ 1907 DTCIUnused3_773 1;
BA_REL_ "GenSigTimeoutTime" BU_SG_REL_ CGM_HS SG_ 1907 DTCIUnused2_773 2500;
BA_REL_ "GenSigTimeoutMsg" BU_SG_REL_ CGM_HS SG_ 1907 DTCIUnused2_773 1907;
BA_REL_ "GenSigSuprvResp" BU_SG_REL_ CGM_HS SG_ 1907 DTCIUnused2_773 1;
BA_REL_ "GenSigTimeoutTime" BU_SG_REL_ CGM_HS SG_ 1907 DTCIUnused1_773 2500;
BA_REL_ "GenSigTimeoutMsg" BU_SG_REL_ CGM_HS SG_ 1907 DTCIUnused1_773 1907;
BA_REL_ "GenSigSuprvResp" BU_SG_REL_ CGM_HS SG_ 1907 DTCIUnused1_773 1;
BA_REL_ "GenSigTimeoutTime" BU_SG_REL_ ECM_HS SG_ 455 APAEngTrqRdctnAct 250;
BA_REL_ "GenSigTimeoutMsg" BU_SG_REL_ ECM_HS SG_ 455 APAEngTrqRdctnAct 455;
BA_REL_ "GenSigSuprvResp" BU_SG_REL_ ECM_HS SG_ 455 APAEngTrqRdctnAct 1;
BA_REL_ "GenSigRxStartValue" BU_SG_REL_ ECM_HS SG_ 455 CSETRER_TqIntvnTyp "$0 - No intervention";
BA_REL_ "GenSigTimeoutTime" BU_SG_REL_ TCM_HS SG_ 975 CGMDS1_DTCStat 250;
BA_REL_ "GenSigTimeoutMsg" BU_SG_REL_ TCM_HS SG_ 975 CGMDS1_DTCStat 975;
BA_REL_ "GenSigSuprvResp" BU_SG_REL_ TCM_HS SG_ 975 CGMDS1_DTCStat 1;
BA_REL_ "GenSigTimeoutTime" BU_SG_REL_ EBCM_HS SG_ 975 CGMDS1_DTCStat 250;
BA_REL_ "GenSigTimeoutMsg" BU_SG_REL_ EBCM_HS SG_ 975 CGMDS1_DTCStat 975;
BA_REL_ "GenSigSuprvResp" BU_SG_REL_ EBCM_HS SG_ 975 CGMDS1_DTCStat 1;
BA_REL_ "GenSigTimeoutTime" BU_SG_REL_ ECM_HS SG_ 975 CGMDS1_DTCStat 250;
BA_REL_ "GenSigTimeoutMsg" BU_SG_REL_ ECM_HS SG_ 975 CGMDS1_DTCStat 975;
BA_REL_ "GenSigSuprvResp" BU_SG_REL_ ECM_HS SG_ 975 CGMDS1_DTCStat 1;
BA_REL_ "GenSigTimeoutTime" BU_SG_REL_ BSM_HS SG_ 975 CGMDS1_DTCStat 250;
BA_REL_ "GenSigTimeoutMsg" BU_SG_REL_ BSM_HS SG_ 975 CGMDS1_DTCStat 975;
BA_REL_ "GenSigSuprvResp" BU_SG_REL_ BSM_HS SG_ 975 CGMDS1_DTCStat 1;
BA_REL_ "GenSigTimeoutTime" BU_SG_REL_ TCM_HS SG_ 975 CGMDS1_DTCIndx 250;
BA_REL_ "GenSigTimeoutMsg" BU_SG_REL_ TCM_HS SG_ 975 CGMDS1_DTCIndx 975;
BA_REL_ "GenSigSuprvResp" BU_SG_REL_ TCM_HS SG_ 975 CGMDS1_DTCIndx 1;
BA_REL_ "GenSigTimeoutTime" BU_SG_REL_ EBCM_HS SG_ 975 CGMDS1_DTCIndx 250;
BA_REL_ "GenSigTimeoutMsg" BU_SG_REL_ EBCM_HS SG_ 975 CGMDS1_DTCIndx 975;
BA_REL_ "GenSigSuprvResp" BU_SG_REL_ EBCM_HS SG_ 975 CGMDS1_DTCIndx 1;
BA_REL_ "GenSigTimeoutTime" BU_SG_REL_ ECM_HS SG_ 975 CGMDS1_DTCIndx 250;
BA_REL_ "GenSigTimeoutMsg" BU_SG_REL_ ECM_HS SG_ 975 CGMDS1_DTCIndx 975;
BA_REL_ "GenSigSuprvResp" BU_SG_REL_ ECM_HS SG_ 975 CGMDS1_DTCIndx 1;
BA_REL_ "GenSigTimeoutTime" BU_SG_REL_ BSM_HS SG_ 975 CGMDS1_DTCIndx 250;
BA_REL_ "GenSigTimeoutMsg" BU_SG_REL_ BSM_HS SG_ 975 CGMDS1_DTCIndx 975;
BA_REL_ "GenSigSuprvResp" BU_SG_REL_ BSM_HS SG_ 975 CGMDS1_DTCIndx 1;
BA_REL_ "GenSigTimeoutTime" BU_SG_REL_ ECM_HS SG_ 975 CGMDS2_DTCStat 250;
BA_REL_ "GenSigTimeoutMsg" BU_SG_REL_ ECM_HS SG_ 975 CGMDS2_DTCStat 975;
BA_REL_ "GenSigSuprvResp" BU_SG_REL_ ECM_HS SG_ 975 CGMDS2_DTCStat 1;
BA_REL_ "GenSigTimeoutTime" BU_SG_REL_ ECM_HS SG_ 975 CGMDS2_DTCIndx 250;
BA_REL_ "GenSigTimeoutMsg" BU_SG_REL_ ECM_HS SG_ 975 CGMDS2_DTCIndx 975;
BA_REL_ "GenSigSuprvResp" BU_SG_REL_ ECM_HS SG_ 975 CGMDS2_DTCIndx 1;
BA_REL_ "GenSigTimeoutTime" BU_SG_REL_ EBCM_HS SG_ 1223 PropSysOffTme 1250;
BA_REL_ "GenSigTimeoutMsg" BU_SG_REL_ EBCM_HS SG_ 1223 PropSysOffTme 1223;
BA_REL_ "GenSigSuprvResp" BU_SG_REL_ EBCM_HS SG_ 1223 PropSysOffTme 1;
BA_REL_ "GenSigTimeoutTime" BU_SG_REL_ BSM_HS SG_ 1223 PropSysOffTme 1250;
BA_REL_ "GenSigTimeoutMsg" BU_SG_REL_ BSM_HS SG_ 1223 PropSysOffTme 1223;
BA_REL_ "GenSigSuprvResp" BU_SG_REL_ BSM_HS SG_ 1223 PropSysOffTme 1;
BA_REL_ "GenSigTimeoutTime" BU_SG_REL_ CGM_HS SG_ 211 ActAxleTrq 250;
BA_REL_ "GenSigTimeoutMsg" BU_SG_REL_ CGM_HS SG_ 211 ActAxleTrq 211;
BA_REL_ "GenSigSuprvResp" BU_SG_REL_ CGM_HS SG_ 211 ActAxleTrq 1;
BA_REL_ "GenSigTimeoutTime" BU_SG_REL_ EPS_HS SG_ 211 ActAxleTrq 250;
BA_REL_ "GenSigTimeoutMsg" BU_SG_REL_ EPS_HS SG_ 211 ActAxleTrq 211;
BA_REL_ "GenSigSuprvResp" BU_SG_REL_ EPS_HS SG_ 211 ActAxleTrq 1;
BA_REL_ "GenSigTimeoutTime" BU_SG_REL_ BSM_HS SG_ 211 ActAxleTrq 500;
BA_REL_ "GenSigTimeoutMsg" BU_SG_REL_ BSM_HS SG_ 211 ActAxleTrq 211;
BA_REL_ "GenSigSuprvResp" BU_SG_REL_ BSM_HS SG_ 211 ActAxleTrq 1;
BA_REL_ "GenSigTimeoutTime" BU_SG_REL_ BSM_HS SG_ 988 EGHRInhbtRqstd 500;
BA_REL_ "GenSigTimeoutMsg" BU_SG_REL_ BSM_HS SG_ 988 EGHRInhbtRqstd 988;
BA_REL_ "GenSigSuprvResp" BU_SG_REL_ BSM_HS SG_ 988 EGHRInhbtRqstd 1;
BA_REL_ "GenSigTimeoutTime" BU_SG_REL_ BSM_HS SG_ 988 AccPwrModMinCoolRq 500;
BA_REL_ "GenSigTimeoutMsg" BU_SG_REL_ BSM_HS SG_ 988 AccPwrModMinCoolRq 988;
BA_REL_ "GenSigSuprvResp" BU_SG_REL_ BSM_HS SG_ 988 AccPwrModMinCoolRq 1;
BA_REL_ "GenSigTimeoutTime" BU_SG_REL_ BSM_HS SG_ 988 A6ERRAlrmTime 500;
BA_REL_ "GenSigTimeoutMsg" BU_SG_REL_ BSM_HS SG_ 988 A6ERRAlrmTime 988;
BA_REL_ "GenSigSuprvResp" BU_SG_REL_ BSM_HS SG_ 988 A6ERRAlrmTime 1;
BA_REL_ "GenSigTimeoutTime" BU_SG_REL_ BSM_HS SG_ 988 A6ERRAlrmReq 500;
BA_REL_ "GenSigTimeoutMsg" BU_SG_REL_ BSM_HS SG_ 988 A6ERRAlrmReq 988;
BA_REL_ "GenSigSuprvResp" BU_SG_REL_ BSM_HS SG_ 988 A6ERRAlrmReq 1;
BA_REL_ "GenSigTimeoutTime" BU_SG_REL_ ECM_HS SG_ 209 BrkModMinVoltReq 250;
BA_REL_ "GenSigTimeoutMsg" BU_SG_REL_ ECM_HS SG_ 209 BrkModMinVoltReq 209;
BA_REL_ "GenSigSuprvResp" BU_SG_REL_ ECM_HS SG_ 209 BrkModMinVoltReq 1;
BA_REL_ "GenSigTimeoutTime" BU_SG_REL_ ECM_HS SG_ 209 ChsBrkPdlPsERltdPVal 250;
BA_REL_ "GenSigTimeoutMsg" BU_SG_REL_ ECM_HS SG_ 209 ChsBrkPdlPsERltdPVal 209;
BA_REL_ "GenSigSuprvResp" BU_SG_REL_ ECM_HS SG_ 209 ChsBrkPdlPsERltdPVal 1;
BA_REL_ "GenSigTimeoutTime" BU_SG_REL_ ECM_HS SG_ 209 ChsBrkPdlPsERltdARC 250;
BA_REL_ "GenSigTimeoutMsg" BU_SG_REL_ ECM_HS SG_ 209 ChsBrkPdlPsERltdARC 209;
BA_REL_ "GenSigSuprvResp" BU_SG_REL_ ECM_HS SG_ 209 ChsBrkPdlPsERltdARC 1;
BA_REL_ "GenSigTimeoutTime" BU_SG_REL_ ECM_HS SG_ 209 ChsBrkPdlPsERltd 250;
BA_REL_ "GenSigTimeoutMsg" BU_SG_REL_ ECM_HS SG_ 209 ChsBrkPdlPsERltd 209;
BA_REL_ "GenSigSuprvResp" BU_SG_REL_ ECM_HS SG_ 209 ChsBrkPdlPsERltd 1;
BA_REL_ "GenSigTimeoutTime" BU_SG_REL_ BSM_HS SG_ 209 DrvIntndTtlBrkTrq 500;
BA_REL_ "GenSigTimeoutMsg" BU_SG_REL_ BSM_HS SG_ 209 DrvIntndTtlBrkTrq 209;
BA_REL_ "GenSigSuprvResp" BU_SG_REL_ BSM_HS SG_ 209 DrvIntndTtlBrkTrq 1;
BA_REL_ "GenSigTimeoutTime" BU_SG_REL_ ECM_HS SG_ 715 ACCAxlTrqCmdProt 250;
BA_REL_ "GenSigSuprvResp" BU_SG_REL_ ECM_HS SG_ 715 ACCAxlTrqCmdProt 1;
BA_REL_ "GenSigTimeoutTime" BU_SG_REL_ ECM_HS SG_ 715 ACCCmndAlvRlgCnt 250;
BA_REL_ "GenSigSuprvResp" BU_SG_REL_ ECM_HS SG_ 715 ACCCmndAlvRlgCnt 1;
BA_REL_ "GenSigTimeoutTime" BU_SG_REL_ ECM_HS SG_ 715 ACCATC_SplREngInpR 250;
BA_REL_ "GenSigSuprvResp" BU_SG_REL_ ECM_HS SG_ 715 ACCATC_SplREngInpR 1;
BA_REL_ "GenSigTimeoutTime" BU_SG_REL_ BSM_HS SG_ 715 ACCATC_SplREngInpR 500;
BA_REL_ "GenSigTimeoutMsg" BU_SG_REL_ BSM_HS SG_ 715 ACCATC_SplREngInpR 715;
BA_REL_ "GenSigSuprvResp" BU_SG_REL_ BSM_HS SG_ 715 ACCATC_SplREngInpR 1;
BA_REL_ "GenSigTimeoutTime" BU_SG_REL_ ECM_HS SG_ 715 ACCATC_DrvAstdGoSt 250;
BA_REL_ "GenSigSuprvResp" BU_SG_REL_ ECM_HS SG_ 715 ACCATC_DrvAstdGoSt 1;
BA_REL_ "GenSigTimeoutTime" BU_SG_REL_ BSM_HS SG_ 715 ACCATC_DrvAstdGoSt 500;
BA_REL_ "GenSigTimeoutMsg" BU_SG_REL_ BSM_HS SG_ 715 ACCATC_DrvAstdGoSt 715;
BA_REL_ "GenSigSuprvResp" BU_SG_REL_ BSM_HS SG_ 715 ACCATC_DrvAstdGoSt 1;
BA_REL_ "GenSigTimeoutTime" BU_SG_REL_ ECM_HS SG_ 715 ACCATC_AxlTrqRq 250;
BA_REL_ "GenSigSuprvResp" BU_SG_REL_ ECM_HS SG_ 715 ACCATC_AxlTrqRq 1;
BA_REL_ "GenSigTimeoutTime" BU_SG_REL_ BSM_HS SG_ 715 ACCATC_AxlTrqRq 500;
BA_REL_ "GenSigTimeoutMsg" BU_SG_REL_ BSM_HS SG_ 715 ACCATC_AxlTrqRq 715;
BA_REL_ "GenSigSuprvResp" BU_SG_REL_ BSM_HS SG_ 715 ACCATC_AxlTrqRq 1;
BA_REL_ "GenSigTimeoutTime" BU_SG_REL_ ECM_HS SG_ 715 ACCATC_ACCTyp 250;
BA_REL_ "GenSigSuprvResp" BU_SG_REL_ ECM_HS SG_ 715 ACCATC_ACCTyp 1;
BA_REL_ "GenSigTimeoutTime" BU_SG_REL_ BSM_HS SG_ 715 ACCATC_ACCTyp 500;
BA_REL_ "GenSigTimeoutMsg" BU_SG_REL_ BSM_HS SG_ 715 ACCATC_ACCTyp 715;
BA_REL_ "GenSigSuprvResp" BU_SG_REL_ BSM_HS SG_ 715 ACCATC_ACCTyp 1;
BA_REL_ "GenSigTimeoutTime" BU_SG_REL_ ECM_HS SG_ 715 ACCATC_ACCAct 250;
BA_REL_ "GenSigSuprvResp" BU_SG_REL_ ECM_HS SG_ 715 ACCATC_ACCAct 1;
BA_REL_ "GenSigTimeoutTime" BU_SG_REL_ BSM_HS SG_ 715 ACCATC_ACCAct 500;
BA_REL_ "GenSigTimeoutMsg" BU_SG_REL_ BSM_HS SG_ 715 ACCATC_ACCAct 715;
BA_REL_ "GenSigSuprvResp" BU_SG_REL_ BSM_HS SG_ 715 ACCATC_ACCAct 1;
BA_REL_ "GenSigTimeoutTime" BU_SG_REL_ CGM_HS SG_ 453 DrvIntndAxlTrqMin 250;
BA_REL_ "GenSigTimeoutMsg" BU_SG_REL_ CGM_HS SG_ 453 DrvIntndAxlTrqMin 453;
BA_REL_ "GenSigSuprvResp" BU_SG_REL_ CGM_HS SG_ 453 DrvIntndAxlTrqMin 1;
BA_REL_ "GenSigTimeoutTime" BU_SG_REL_ CGM_HS SG_ 453 DrvIntndAxlTrqMax 250;
BA_REL_ "GenSigTimeoutMsg" BU_SG_REL_ CGM_HS SG_ 453 DrvIntndAxlTrqMax 453;
BA_REL_ "GenSigSuprvResp" BU_SG_REL_ CGM_HS SG_ 453 DrvIntndAxlTrqMax 1;
BA_REL_ "GenSigTimeoutTime" BU_SG_REL_ CGM_HS SG_ 453 DrvIntndAxlTrq 250;
BA_REL_ "GenSigTimeoutMsg" BU_SG_REL_ CGM_HS SG_ 453 DrvIntndAxlTrq 453;
BA_REL_ "GenSigSuprvResp" BU_SG_REL_ CGM_HS SG_ 453 DrvIntndAxlTrq 1;
BA_REL_ "GenSigTimeoutTime" BU_SG_REL_ EBCM_HS SG_ 453 DrvIntndAxlTrq 250;
BA_REL_ "GenSigTimeoutMsg" BU_SG_REL_ EBCM_HS SG_ 453 DrvIntndAxlTrq 453;
BA_REL_ "GenSigSuprvResp" BU_SG_REL_ EBCM_HS SG_ 453 DrvIntndAxlTrq 1;
BA_REL_ "GenSigTimeoutTime" BU_SG_REL_ BSM_HS SG_ 453 DrvIntndAxlTrq 500;
BA_REL_ "GenSigTimeoutMsg" BU_SG_REL_ BSM_HS SG_ 453 DrvIntndAxlTrq 453;
BA_REL_ "GenSigSuprvResp" BU_SG_REL_ BSM_HS SG_ 453 DrvIntndAxlTrq 1;
BA_REL_ "GenSigTimeoutTime" BU_SG_REL_ BSM_HS SG_ 495 MassAirFlo 500;
BA_REL_ "GenSigTimeoutMsg" BU_SG_REL_ BSM_HS SG_ 495 MassAirFlo 495;
BA_REL_ "GenSigSuprvResp" BU_SG_REL_ BSM_HS SG_ 495 MassAirFlo 1;
BA_REL_ "GenSigTimeoutTime" BU_SG_REL_ BSM_HS SG_ 493 InstFuelFlowEst 500;
BA_REL_ "GenSigTimeoutMsg" BU_SG_REL_ BSM_HS SG_ 493 InstFuelFlowEst 493;
BA_REL_ "GenSigSuprvResp" BU_SG_REL_ BSM_HS SG_ 493 InstFuelFlowEst 1;
BA_REL_ "GenSigTimeoutTime" BU_SG_REL_ CGM_HS SG_ 989 MntnceMdStEngRq 250;
BA_REL_ "GenSigTimeoutMsg" BU_SG_REL_ CGM_HS SG_ 989 MntnceMdStEngRq 989;
BA_REL_ "GenSigSuprvResp" BU_SG_REL_ CGM_HS SG_ 989 MntnceMdStEngRq 1;
BA_REL_ "GenSigTimeoutTime" BU_SG_REL_ CGM_HS SG_ 1927 DTCI_CodeSupported_787 2500;
BA_REL_ "GenSigTimeoutMsg" BU_SG_REL_ CGM_HS SG_ 1927 DTCI_CodeSupported_787 1927;
BA_REL_ "GenSigSuprvResp" BU_SG_REL_ CGM_HS SG_ 1927 DTCI_CodeSupported_787 1;
BA_REL_ "GenSigTimeoutTime" BU_SG_REL_ CGM_HS SG_ 1927 DTCI_CurrentStatus_787 2500;
BA_REL_ "GenSigTimeoutMsg" BU_SG_REL_ CGM_HS SG_ 1927 DTCI_CurrentStatus_787 1927;
BA_REL_ "GenSigSuprvResp" BU_SG_REL_ CGM_HS SG_ 1927 DTCI_CurrentStatus_787 1;
BA_REL_ "GenSigTimeoutTime" BU_SG_REL_ CGM_HS SG_ 1927 DTCI_DTCFailType_787 2500;
BA_REL_ "GenSigTimeoutMsg" BU_SG_REL_ CGM_HS SG_ 1927 DTCI_DTCFailType_787 1927;
BA_REL_ "GenSigSuprvResp" BU_SG_REL_ CGM_HS SG_ 1927 DTCI_DTCFailType_787 1;
BA_REL_ "GenSigTimeoutTime" BU_SG_REL_ CGM_HS SG_ 1927 DTCI_DTCFaultType_787 2500;
BA_REL_ "GenSigTimeoutMsg" BU_SG_REL_ CGM_HS SG_ 1927 DTCI_DTCFaultType_787 1927;
BA_REL_ "GenSigSuprvResp" BU_SG_REL_ CGM_HS SG_ 1927 DTCI_DTCFaultType_787 1;
BA_REL_ "GenSigTimeoutTime" BU_SG_REL_ CGM_HS SG_ 1927 DTCI_DTCNumber_787 2500;
BA_REL_ "GenSigTimeoutMsg" BU_SG_REL_ CGM_HS SG_ 1927 DTCI_DTCNumber_787 1927;
BA_REL_ "GenSigSuprvResp" BU_SG_REL_ CGM_HS SG_ 1927 DTCI_DTCNumber_787 1;
BA_REL_ "GenSigTimeoutTime" BU_SG_REL_ CGM_HS SG_ 1927 DTCI_DTCSource_787 2500;
BA_REL_ "GenSigTimeoutMsg" BU_SG_REL_ CGM_HS SG_ 1927 DTCI_DTCSource_787 1927;
BA_REL_ "GenSigSuprvResp" BU_SG_REL_ CGM_HS SG_ 1927 DTCI_DTCSource_787 1;
BA_REL_ "GenSigTimeoutTime" BU_SG_REL_ CGM_HS SG_ 1927 DTCI_DTCTriggered_787 2500;
BA_REL_ "GenSigTimeoutMsg" BU_SG_REL_ CGM_HS SG_ 1927 DTCI_DTCTriggered_787 1927;
BA_REL_ "GenSigSuprvResp" BU_SG_REL_ CGM_HS SG_ 1927 DTCI_DTCTriggered_787 1;
BA_REL_ "GenSigTimeoutTime" BU_SG_REL_ CGM_HS SG_ 1927 DTCI_HistStat_787 2500;
BA_REL_ "GenSigTimeoutMsg" BU_SG_REL_ CGM_HS SG_ 1927 DTCI_HistStat_787 1927;
BA_REL_ "GenSigSuprvResp" BU_SG_REL_ CGM_HS SG_ 1927 DTCI_HistStat_787 1;
BA_REL_ "GenSigTimeoutTime" BU_SG_REL_ CGM_HS SG_ 1927 DTCI_TstFldCdClrdStat_787 2500;
BA_REL_ "GenSigTimeoutMsg" BU_SG_REL_ CGM_HS SG_ 1927 DTCI_TstFldCdClrdStat_787 1927;
BA_REL_ "GenSigSuprvResp" BU_SG_REL_ CGM_HS SG_ 1927 DTCI_TstFldCdClrdStat_787 1;
BA_REL_ "GenSigTimeoutTime" BU_SG_REL_ CGM_HS SG_ 1927 DTCI_TstFldPwrUpSt_787 2500;
BA_REL_ "GenSigTimeoutMsg" BU_SG_REL_ CGM_HS SG_ 1927 DTCI_TstFldPwrUpSt_787 1927;
BA_REL_ "GenSigSuprvResp" BU_SG_REL_ CGM_HS SG_ 1927 DTCI_TstFldPwrUpSt_787 1;
BA_REL_ "GenSigTimeoutTime" BU_SG_REL_ CGM_HS SG_ 1927 DTCI_TstNPsdCdClrdSt_787 2500;
BA_REL_ "GenSigTimeoutMsg" BU_SG_REL_ CGM_HS SG_ 1927 DTCI_TstNPsdCdClrdSt_787 1927;
BA_REL_ "GenSigSuprvResp" BU_SG_REL_ CGM_HS SG_ 1927 DTCI_TstNPsdCdClrdSt_787 1;
BA_REL_ "GenSigTimeoutTime" BU_SG_REL_ CGM_HS SG_ 1927 DTCI_TstNPsdPwrUpSt_787 2500;
BA_REL_ "GenSigTimeoutMsg" BU_SG_REL_ CGM_HS SG_ 1927 DTCI_TstNPsdPwrUpSt_787 1927;
BA_REL_ "GenSigSuprvResp" BU_SG_REL_ CGM_HS SG_ 1927 DTCI_TstNPsdPwrUpSt_787 1;
BA_REL_ "GenSigTimeoutTime" BU_SG_REL_ CGM_HS SG_ 1927 DTCIUnused1_787 2500;
BA_REL_ "GenSigTimeoutMsg" BU_SG_REL_ CGM_HS SG_ 1927 DTCIUnused1_787 1927;
BA_REL_ "GenSigSuprvResp" BU_SG_REL_ CGM_HS SG_ 1927 DTCIUnused1_787 1;
BA_REL_ "GenSigTimeoutTime" BU_SG_REL_ CGM_HS SG_ 1927 DTCIUnused2_787 2500;
BA_REL_ "GenSigTimeoutMsg" BU_SG_REL_ CGM_HS SG_ 1927 DTCIUnused2_787 1927;
BA_REL_ "GenSigSuprvResp" BU_SG_REL_ CGM_HS SG_ 1927 DTCIUnused2_787 1;
BA_REL_ "GenSigTimeoutTime" BU_SG_REL_ CGM_HS SG_ 1927 DTCIUnused3_787 2500;
BA_REL_ "GenSigTimeoutMsg" BU_SG_REL_ CGM_HS SG_ 1927 DTCIUnused3_787 1927;
BA_REL_ "GenSigSuprvResp" BU_SG_REL_ CGM_HS SG_ 1927 DTCIUnused3_787 1;
BA_REL_ "GenSigTimeoutTime" BU_SG_REL_ CGM_HS SG_ 1927 DTCIUnused4_787 2500;
BA_REL_ "GenSigTimeoutMsg" BU_SG_REL_ CGM_HS SG_ 1927 DTCIUnused4_787 1927;
BA_REL_ "GenSigSuprvResp" BU_SG_REL_ CGM_HS SG_ 1927 DTCIUnused4_787 1;
BA_REL_ "GenSigTimeoutTime" BU_SG_REL_ CGM_HS SG_ 1927 DTCIUnused5_787 2500;
BA_REL_ "GenSigTimeoutMsg" BU_SG_REL_ CGM_HS SG_ 1927 DTCIUnused5_787 1927;
BA_REL_ "GenSigSuprvResp" BU_SG_REL_ CGM_HS SG_ 1927 DTCIUnused5_787 1;
BA_REL_ "GenSigTimeoutTime" BU_SG_REL_ CGM_HS SG_ 1927 DTCIUnused6_787 2500;
BA_REL_ "GenSigTimeoutMsg" BU_SG_REL_ CGM_HS SG_ 1927 DTCIUnused6_787 1927;
BA_REL_ "GenSigSuprvResp" BU_SG_REL_ CGM_HS SG_ 1927 DTCIUnused6_787 1;
BA_REL_ "GenSigTimeoutTime" BU_SG_REL_ CGM_HS SG_ 1927 DTCIUnused7_787 2500;
BA_REL_ "GenSigTimeoutMsg" BU_SG_REL_ CGM_HS SG_ 1927 DTCIUnused7_787 1927;
BA_REL_ "GenSigSuprvResp" BU_SG_REL_ CGM_HS SG_ 1927 DTCIUnused7_787 1;
BA_REL_ "GenSigTimeoutTime" BU_SG_REL_ CGM_HS SG_ 1927 DTCI_WrnIndRqdSt_787 2500;
BA_REL_ "GenSigTimeoutMsg" BU_SG_REL_ CGM_HS SG_ 1927 DTCI_WrnIndRqdSt_787 1927;
BA_REL_ "GenSigSuprvResp" BU_SG_REL_ CGM_HS SG_ 1927 DTCI_WrnIndRqdSt_787 1;
BA_REL_ "GenSigTimeoutTime" BU_SG_REL_ BCM_HS SG_ 1276 CCFrBlwFnSpdFbkRat 2500;
BA_REL_ "GenSigTimeoutMsg" BU_SG_REL_ BCM_HS SG_ 1276 CCFrBlwFnSpdFbkRat 1276;
BA_REL_ "GenSigSuprvResp" BU_SG_REL_ BCM_HS SG_ 1276 CCFrBlwFnSpdFbkRat 1;
VAL_ 967 PRS_PTRlyFdbkCtVtNtIR 1 "true" 0 "false" ;
VAL_ 967 PRS_PTRlyFdbkCktFAct 1 "true" 0 "false" ;
VAL_ 967 PRS_PTRlyCntrlCktFAct 1 "true" 0 "false" ;
VAL_ 967 PRS_PTRlyCmdSt 1 "Relay On" 0 "Relay Off" ;
VAL_ 487 EngRunng 1 "true" 0 "false" ;
VAL_ 487 FlPmpEDscOtptCmdSta 1 "Fuel Pump Enabled" 0 "Fuel Pump Disabled" ;
VAL_ 487 FuelCntlSysFltPrsnt 1 "true" 0 "false" ;
VAL_ 487 HiPresFuelPmpCntMd 6 "Zero Flow Mode" 5 "Noise Control Max Mode" 4 "Noise Control Disable Mode" 3 "Start Mode" 2 "Normal Mode" 1 "DFCO Mode" 0 "Disable Mode" ;
VAL_ 398 EngNTrnsRegStdyStTqV 1 "Invalid" 0 "Valid" ;
VAL_ 398 AccKdwnAtv 1 "true" 0 "false" ;
VAL_ 398 EngActStdyStTorqV 1 "Invalid" 0 "Valid" ;
VAL_ 398 TrnsEngSpdReqFld 1 "true" 0 "false" ;
VAL_ 398 PTACCAct 1 "true" 0 "false" ;
VAL_ 398 CTSS_StbltyLvl 7 "Level 7" 6 "Level 6" 5 "Level 5" 4 "Level 4" 3 "Level 3" 2 "Level 2" 1 "Level 1" 0 "Level 0" ;
VAL_ 398 CTSS_StbltyTyp 7 "Unused and Reserved 4" 6 "Unused and Reserved 3" 5 "Unused and Reserved 2" 4 "Unused and Reserved 1" 3 "Torque Increase Pending" 2 "Torque Decrease Pending" 1 "Torque High Pulsation" 0 "Normal Stability" ;
VAL_ 398 EngImmTrqTnsRqStat 0 "No Request" 7 "Unused and Reserved" 6 "Control System Failure Permanent" 5 "Control System Failure Temporary" 4 "Serial Data Failure Permanent" 3 "Serial Data Failure Temporary" 2 "Lost Arbitration" 1 "Request Honored" ;
VAL_ 398 EngImmTrqTnsRqLmSt 7 "Unused and Reserved 4" 6 "Unused and Reserved 3" 5 "Unused and Reserved 2" 4 "Unused and Reserved 1" 3 "Value Limited High" 2 "Value Limited Low" 1 "Rate Limited" 0 "Not Limited" ;
VAL_ 398 EngPrdctTrqTnsRqStat 7 "Unused and Reserved" 6 "Control System Failure Permanent" 5 "Control System Failure Temporary" 4 "Serial Data Failure Permanent" 3 "Serial Data Failure Temporary" 2 "Lost Arbitration" 1 "Request Honored" 0 "No Request" ;
VAL_ 398 EngPrdctTrqTnsRqLmS 7 "Unused and Reserved 4" 6 "Unused and Reserved 3" 5 "Unused and Reserved 2" 4 "Unused and Reserved 1" 3 "Value Limited High" 2 "Value Limited Low" 1 "Rate Limited" 0 "Not Limited" ;
VAL_ 1906 DTCI_DTCFaultType_772 3 "Type C" 2 "Type B" 1 "Type A" 0 "Not Supported" ;
VAL_ 1906 DTCI_CodeSupported_772 1 "true" 0 "false" ;
VAL_ 1906 DTCI_CurrentStatus_772 1 "true" 0 "false" ;
VAL_ 1906 DTCI_TstNPsdCdClrdSt_772 1 "true" 0 "false" ;
VAL_ 1906 DTCI_TstFldCdClrdStat_772 1 "true" 0 "false" ;
VAL_ 1906 DTCI_HistStat_772 1 "true" 0 "false" ;
VAL_ 1906 DTCI_TstNPsdPwrUpSt_772 0 "false" 1 "true" ;
VAL_ 1906 DTCI_TstFldPwrUpSt_772 1 "true" 0 "false" ;
VAL_ 1906 DTCI_WrnIndRqdSt_772 1 "true" 0 "false" ;
VAL_ 1906 DTCI_DTCTriggered_772 1 "true" 0 "false" ;
VAL_ 1906 DTCIUnused7_772 1 "true" 0 "false" ;
VAL_ 1906 DTCIUnused6_772 1 "true" 0 "false" ;
VAL_ 1906 DTCIUnused5_772 1 "true" 0 "false" ;
VAL_ 1906 DTCIUnused4_772 1 "true" 0 "false" ;
VAL_ 1906 DTCIUnused3_772 1 "true" 0 "false" ;
VAL_ 1906 DTCIUnused2_772 1 "true" 0 "false" ;
VAL_ 1906 DTCIUnused1_772 1 "true" 0 "false" ;
VAL_ 401 EngTrqTrnRqTmpFld 1 "true" 0 "false" ;
VAL_ 401 EngTrqTrnRqLmtd 1 "true" 0 "false" ;
VAL_ 401 TrnsEngSpdReqFld 1 "true" 0 "false" ;
VAL_ 401 EngTrqTnsRqFld 1 "true" 0 "false" ;
VAL_ 401 EngTrqRdnFld 1 "true" 0 "false" ;
VAL_ 401 EngNTrnsRegStdyStTqV 1 "Invalid" 0 "Valid" ;
VAL_ 401 EngAirflwStdyStTorqV 1 "Invalid" 0 "Valid" ;
VAL_ 401 AccKdwnAtv 1 "true" 0 "false" ;
VAL_ 401 AccPosV 1 "Invalid" 0 "Valid" ;
VAL_ 401 EngActStdyStTorqV 1 "Invalid" 0 "Valid" ;
VAL_ 872 ESBR_AutoBrkgRqTyp 3 "Unused and Reserved" 2 "Hold Deny Driver Release" 1 "Hold Allow Driver Release" 0 "Release" ;
VAL_ 872 ESBR_AutoBrkgRqd 1 "Braking Requested" 0 "Braking Not Requested " ;
VAL_ 331 TrlrPrfDltn 5 "Profile 5 Deleted" 4 "Profile 4 Deleted" 3 "Profile 3 Deleted" 2 "Profile 2 Deleted" 1 "Profile 1 Deleted" 0 "No Profile Deleted" ;
VAL_ 331 TrlrTrPrsSenrIDLrnReqd 1 "true" 0 "false" ;
VAL_ 331 TrlrProfSelV 1 "Invalid" 0 "Valid" ;
VAL_ 331 TrlrProfSel 5 "Profile 5" 4 "Profile 4" 3 "Profile 3" 2 "Profile 2" 1 "Profile 1" 0 "Default Profile" ;
VAL_ 1034 CRL_Cnfdnc 7 "Reserved4" 6 "Reserved3" 5 "Reserved2" 4 "Reserved1" 3 "Best" 2 "Marking Present" 1 "Weak Marking" 0 "No Lane" ;
VAL_ 1033 CLL_Cnfdnc 7 "Reserved4" 6 "Reserved3" 5 "Reserved2" 4 "Reserved1" 3 "Best" 2 "Marking Present" 1 "Weak Marking" 0 "No Lane" ;
VAL_ 1013 TrnRqHRBkCtlTgtVSpd 0 "Normal" 1 "Reduced Speed 1" 2 "Reduced Speed 2" 3 "Reduced Speed 3" ;
VAL_ 1013 TransReqHSAAval 0 "Normal" 1 "Level 1" 2 "Level 2" 3 "Level 3" ;
VAL_ 1013 TRDLF_TrnsFwDrvRDLFlt 1 "true" 0 "false" ;
VAL_ 1013 TRDLF_TrnsNtRgDgLtFlt 1 "true" 0 "false" ;
VAL_ 1013 TRDLF_TrnsRvRgDgLtFlt 1 "true" 0 "false" ;
VAL_ 1013 TRDLF_TrnsPkRgDgLtFlt 1 "true" 0 "false" ;
VAL_ 1013 TRDCF_TrnsFwDrvRDCFlt 1 "true" 0 "false" ;
VAL_ 1013 TRDCF_TrnsNtRgDgCtFlt 1 "true" 0 "false" ;
VAL_ 1013 TRDCF_TrnsRvRgDgCtFlt 1 "true" 0 "false" ;
VAL_ 1013 TRDCF_TrnsPkRgDgCtFlt 1 "true" 0 "false" ;
VAL_ 170 EngCommFlrRedPwrCm 1 "true" 0 "false" ;
VAL_ 170 CmndAxlTrqRespTyp 0 "Inactive" 1 "Pleasability Limit" 2 "Maximum Range" 3 "Automatic Actuator Selection" ;
VAL_ 647 DrvTrkModeCmnd 1 "true" 0 "false" ;
VAL_ 647 DrvCrwlModeCmnd 1 "true" 0 "false" ;
VAL_ 647 EngCntDtIntRSnsPsWdtV 1 "Invalid" 0 "Valid" ;
VAL_ 647 CrnksftTqModRspMxCapV 1 "Invalid" 0 "Valid" ;
VAL_ 647 EngDetPndTrnCsRngShfV 1 "Invalid" 0 "Valid" ;
VAL_ 647 EngDetPndTrnCsRngShf 3 "Shift Out of Neutral Range" 2 "Shift Out of Low Range" 1 "Shift Out of High Range" 0 "None" ;
VAL_ 647 CrpCstCrvCmd 7 "Creep Coast Curve 7" 6 "Creep Coast Curve 6" 5 "Creep Coast Curve 5" 4 "Creep Coast Curve 4" 3 "Creep Coast Curve 3" 2 "Creep Coast Curve 2" 1 "Creep Coast Curve 1" 0 "Creep Coast Curve 0" ;
VAL_ 647 DrvMntnMdCmnd 1 "true" 0 "false" ;
VAL_ 647 DrvHldMdCmnd 1 "true" 0 "false" ;
VAL_ 647 DrPTGrdBrkDsbMdCmd 1 "true" 0 "false" ;
VAL_ 647 DrvWntrMdCmd 1 "true" 0 "false" ;
VAL_ 647 DrvTwHaulMdCmd 1 "true" 0 "false" ;
VAL_ 647 DrvSprtMdCmd 1 "true" 0 "false" ;
VAL_ 647 DrvEconMdCmd 1 "true" 0 "false" ;
VAL_ 647 EngCntrlDtrmdTrfCRngV 1 "Invalid" 0 "Valid" ;
VAL_ 647 EngCntrlDtrmdTrfCRng 3 "Neutral" 2 "Unused and Reserved" 1 "Low" 0 "High" ;
VAL_ 647 EngCntrlUtldTrnCsRng 3 "Neutral" 2 "Unused and Reserved" 1 "Low" 0 "High" ;
VAL_ 647 EngCntrlUtldTrnCsRgIn 1 "true" 0 "false" ;
VAL_ 199 TORSValidity 1 "Invalid" 0 "Valid" ;
VAL_ 199 TORSRstOcrd 1 "true" 0 "false" ;
VAL_ 199 TORSLstTransType 3 "Undefined" 2 "Falling Transition" 1 "Rising Transition" 0 "Single Edge Sensor" ;
VAL_ 199 TORSRotDir 3 "Undefined" 2 "Reverse" 1 "Forward" 0 "Unknown" ;
VAL_ 190 TrnsAuxPmpAct 1 "true" 0 "false" ;
VAL_ 190 PSBPI_PTSnBrkPdlPsV 1 "Invalid" 0 "Valid" ;
VAL_ 707 CSTATRS_ReqStat 6 "Control System Failure Permanent" 5 "Control System Failure Temporary" 4 "Serial Data Failure Permanent" 3 "Serial Data Failure Temporary" 2 "Lost Arbitration" 1 "Request Honored" 0 "No Request" ;
VAL_ 707 CSTATRS_LmtgStat 3 "Rate and Value Limited" 2 "Value Limited" 1 "Rate Limited" 0 "Not Limited" ;
VAL_ 707 EngManfldAbsPrsV 1 "Invalid" 0 "Valid" ;
VAL_ 707 EngTrqMinExtRngV 1 "Invalid" 0 "Valid" ;
VAL_ 707 EngTrqMaxExtRngV 1 "Invalid" 0 "Valid" ;
VAL_ 249 TrnsDrvlneTqShpDisRq 1 "true" 0 "false" ;
VAL_ 249 TrnsOtptShftAngVelSnrPr 1 "true" 0 "false" ;
VAL_ 249 TrnsRqHSABrkPrDcyRt 0 "Normal" 1 "Level 1" 2 "Level 2" 3 "Level 3" ;
VAL_ 249 TrnsOtptRotRCRstOcc 1 "true" 0 "false" ;
VAL_ 249 TrnsOtptRotRCV 1 "Invalid" 0 "Valid" ;
VAL_ 249 TrnsOutShftAngVelV 1 "Invalid" 0 "Valid" ;
VAL_ 249 TrnsOvrallEstTorqRatioV 1 "Invalid" 0 "Valid" ;
VAL_ 1273 BrkSyCtl1EmsRldMlfAct 1 "true" 0 "false" ;
VAL_ 1273 BSC1ERDTC_SysDes 15 "U3-Network Codes Reserved" 14 "U2-Network Codes Reserved" 13 "U1-Network Codes MFG Controlled" 12 "U0-Network Codes SAE Controlled" 11 "B3-Body Codes Reserved" 10 "B2-Body Codes Reserved" 9 "B1-Body Codes MFG Controlled" 8 "B0-Body Codes SAE Controlled" 7 "C3-Chassis Codes Reserved" 6 "C2-Chassis Codes Reserved" 5 "C1-Chassis Codes MFG Controlled" 4 "C0-Chassis Codes SAE Controlled" 3 "P3-Powertrain Codes Reserved" 2 "P2-Powertrain Codes Reserved" 1 "P1-Powertrain Codes MFG Controlled" 0 "P0-Powertrain Codes SAE Controlled" ;
VAL_ 753 EBCMDS5_DTCStatus 0 "Not Supported" 1 "Critically Disabled" 2 "No Status to Report" 3 "Diagnostic Passed" 4 "Diagnostic Failed" ;
VAL_ 753 EBCMDS4_DTCStatus 0 "Not Supported" 1 "Critically Disabled" 2 "No Status to Report" 3 "Diagnostic Passed" 4 "Diagnostic Failed" ;
VAL_ 753 EBCMDS3_DTCStatus 0 "Not Supported" 1 "Critically Disabled" 2 "No Status to Report" 3 "Diagnostic Passed" 4 "Diagnostic Failed" ;
VAL_ 753 EBCMDS2_DTCStatus 0 "Not Supported" 1 "Critically Disabled" 2 "No Status to Report" 3 "Diagnostic Passed" 4 "Diagnostic Failed" ;
VAL_ 753 EBCMDS1_DTCStatus 0 "Not Supported" 1 "Critically Disabled" 2 "No Status to Report" 3 "Diagnostic Passed" 4 "Diagnostic Failed" ;
VAL_ 508 CSTBATS_TrqVlV 1 "Invalid" 0 "Valid" ;
VAL_ 454 APAAxlTrqRdctnAct 1 "true" 0 "false" ;
VAL_ 454 CSPATR_TrqIntrvnTyp 3 "Minimum and Maximum Limit" 2 "Minimum Limit" 1 "Maximum Limit" 0 "No Intervention" ;
VAL_ 454 CSPATR_TrqRqTyp 0 "Absolute Torque Request" ;
VAL_ 454 ChsSysAxlTqRqRspTyp 4 "Braking Torque Request" 3 "Automatic Actuator Selection" 2 "Maximum Range Request" 1 "Pleasability Limited Request" 0 "Inactive" ;
VAL_ 554 BrkSysVTopSpdLimRqTp 3 "Unused and Reserved 2" 2 "Unused and Reserved 1" 1 "OBD" 0 "Inactive" ;
VAL_ 554 PrtdEPBSwStat 3 "Active" 2 "Apply" 1 "Release" 0 "Not Active" ;
VAL_ 554 ElecPrkBrkAvailStat 7 "Unused and Reserved 3" 6 "Unused and Reserved 2" 5 "Unused and Reserved 1" 4 "Unavailable, Failed other" 3 "Unavailable, Failed Released" 2 "Unavailable, Failed Applied" 1 "Available, Not Failed" 0 "Unavailable, Not Failed" ;
VAL_ 554 ElecPrkBrkApplStat 3 "Park Brake Application in Progress" 2 "Park brake Released" 1 "Park Brake Applied" 0 "Unknown" ;
VAL_ 462 SecAxlLkTqRqCplRqTp 0 "No Action" 1 "Maximum Allowed Torque" 2 "Minimum Allowed Torque" 3 "Control To Requested Torque" ;
VAL_ 462 SATRCplReqAtv 1 "true" 0 "false" ;
VAL_ 1920 DTCI_CurrentStatus_780 1 "true" 0 "false" ;
VAL_ 1920 DTCI_WrnIndRqdSt_780 1 "true" 0 "false" ;
VAL_ 1920 DTCIUnused7_780 1 "true" 0 "false" ;
VAL_ 1920 DTCIUnused6_780 1 "true" 0 "false" ;
VAL_ 1920 DTCIUnused5_780 1 "true" 0 "false" ;
VAL_ 1920 DTCIUnused4_780 1 "true" 0 "false" ;
VAL_ 1920 DTCIUnused3_780 1 "true" 0 "false" ;
VAL_ 1920 DTCIUnused2_780 1 "true" 0 "false" ;
VAL_ 1920 DTCIUnused1_780 1 "true" 0 "false" ;
VAL_ 1920 DTCI_TstNPsdPwrUpSt_780 1 "true" 0 "false" ;
VAL_ 1920 DTCI_TstNPsdCdClrdSt_780 1 "true" 0 "false" ;
VAL_ 1920 DTCI_TstFldPwrUpSt_780 1 "true" 0 "false" ;
VAL_ 1920 DTCI_TstFldCdClrdStat_780 1 "true" 0 "false" ;
VAL_ 1920 DTCI_HistStat_780 1 "true" 0 "false" ;
VAL_ 1920 DTCI_DTCTriggered_780 1 "true" 0 "false" ;
VAL_ 1920 DTCI_DTCFaultType_780 3 "Type C" 2 "Type B" 1 "Type A" 0 "Not Supported" ;
VAL_ 1920 DTCI_CodeSupported_780 1 "true" 0 "false" ;
VAL_ 1907 DTCI_DTCFaultType_773 3 "Type C" 2 "Type B" 1 "Type A" 0 "Not Supported" ;
VAL_ 1907 DTCI_CodeSupported_773 1 "true" 0 "false" ;
VAL_ 1907 DTCI_CurrentStatus_773 1 "true" 0 "false" ;
VAL_ 1907 DTCI_TstNPsdCdClrdSt_773 1 "true" 0 "false" ;
VAL_ 1907 DTCI_TstFldCdClrdStat_773 1 "true" 0 "false" ;
VAL_ 1907 DTCI_HistStat_773 1 "true" 0 "false" ;
VAL_ 1907 DTCI_TstNPsdPwrUpSt_773 1 "true" 0 "false" ;
VAL_ 1907 DTCI_TstFldPwrUpSt_773 1 "true" 0 "false" ;
VAL_ 1907 DTCI_WrnIndRqdSt_773 1 "true" 0 "false" ;
VAL_ 1907 DTCI_DTCTriggered_773 1 "true" 0 "false" ;
VAL_ 1907 DTCIUnused7_773 1 "true" 0 "false" ;
VAL_ 1907 DTCIUnused6_773 1 "true" 0 "false" ;
VAL_ 1907 DTCIUnused5_773 1 "true" 0 "false" ;
VAL_ 1907 DTCIUnused4_773 1 "true" 0 "false" ;
VAL_ 1907 DTCIUnused3_773 1 "true" 0 "false" ;
VAL_ 1907 DTCIUnused2_773 1 "true" 0 "false" ;
VAL_ 1907 DTCIUnused1_773 1 "true" 0 "false" ;
VAL_ 455 APAEngTrqRdctnAct 1 "true" 0 "false" ;
VAL_ 455 CSETRER_TqIntvnTyp 2 "Increase Torque" 1 "Reduce Torque" 0 "No Intervention" ;
VAL_ 975 CGMDS1_DTCStat 7 "Unused and Reserved3" 6 "Unused and Reserved2" 5 "Unused and Reserved1" 4 "Diagnostic Failed" 3 "Diagnostic Passed" 2 "No Status to Report" 1 "Critically Disabled" 0 "Not Supported" ;
VAL_ 975 CGMDS2_DTCStat 7 "Unused and Reserved3" 6 "Unused and Reserved2" 5 "Unused and Reserved1" 4 "Diagnostic Failed" 3 "Diagnostic Passed" 2 "No Status to Report" 1 "Critically Disabled" 0 "Not Supported" ;
VAL_ 1223 PropSysOffTmeV 1 "Invalid" 0 "Valid" ;
VAL_ 1223 PropSysOffTmeM 1 "Use Data" 0 "Don't Use Data" ;
VAL_ 211 ActAxleTrqV 1 "Invalid" 0 "Valid" ;
VAL_ 988 MntnceMdDsplyRq 15 "Unused and Reserved" 14 "Continue FM" 13 "Force FM" 12 "FM 1 Day Warning" 11 "FM 2 Day Warning" 10 "FM 3 Day Warning" 9 "FM 4 Day Warning" 8 "FM 5 Day Warning" 7 "Continue EM" 6 "Force EM" 5 "EM 1 Day Warning" 4 "EM 2 Day Warning" 3 "EM 3 Day Warning" 2 "EM 4 Day Warning" 1 "EM 5 Day Warning" 0 "No Request" ;
VAL_ 988 EngMntnceMdAct 1 "true" 0 "false" ;
VAL_ 988 EngHtrValvBpasCmd 0 "Bypass Commanded" 1 "Normal Operation Allowed" ;
VAL_ 988 EGHRInhbtRqstd 1 "true" 0 "false" ;
VAL_ 988 AccPwrModMinCoolRq 0 "None" 1 "Minimum" 2 "Low" 3 "Medium" 4 "High" ;
VAL_ 988 HVPropChgrUnbl 1 "true" 0 "false" ;
VAL_ 988 A6ERRAlrmReq 2 "Cancel Alarm" 1 "Set Alarm" 0 "No Action" ;
VAL_ 209 ChsBrkPdlPsERltdV 1 "Invalid" 0 "Valid" ;
VAL_ 715 LCCC_Act 1 "true" 0 "false" ;
VAL_ 715 LCCC_AccelPedLimReq 1 "true" 0 "false" ;
VAL_ 715 ACCATC_SplREngInpR 1 "true" 0 "false" ;
VAL_ 715 ACCATC_DrvAstdGoSt 3 "Auto Resume Pending" 2 "Apply Acc Pedal or Resume Sw To Go" 1 "Apply Accel Pedal to Go" 0 "Not Stopped" ;
VAL_ 715 ACCATC_ACCTyp 3 "Full Speed Range ACC with LCC" 2 "Full Speed Range ACC with Booster" 1 "Full Speed Range ACC" 0 "Adaptive Cruise Control" ;
VAL_ 715 ACCATC_ACCAct 1 "true" 0 "false" ;
VAL_ 453 DrvIntndAxlTrqMinV 1 "Invalid" 0 "Valid" ;
VAL_ 453 DrvIntndAxlTrqMaxV 1 "Invalid" 0 "Valid" ;
VAL_ 453 DrvIntndAxlTrqV 1 "Invalid" 0 "Valid" ;
VAL_ 495 MassAirFloV 1 "Invalid" 0 "Valid" ;
VAL_ 493 EngRunng 1 "true" 0 "false" ;
VAL_ 493 FlPmpEDscOtptCmdSta 1 "Fuel Pump Enabled" 0 "Fuel Pump Disabled" ;
VAL_ 493 FuelCntlSysFltPrsnt 1 "true" 0 "false" ;
VAL_ 989 RdChrgrCntctrStatus 2 "Closed" 1 "Precharge" 0 "Open" ;
VAL_ 989 RdHVCntctrShdwnReq 0 "None" 1 "Emergency Shutdown" 2 "Controlled Shutdown" 3 "Emergency Crash Shutdown" ;
VAL_ 989 AuxClntHtrVlvStat 7 "Unused and Reserved 2" 6 "De-Aeration Routine Active" 5 "Diagnostic Override" 4 "Re-Calibration" 3 "Fault Active" 2 "Engine Link" 1 "Transition" 0 "Engine Bypass" ;
VAL_ 989 EngCoolFanOpEnbl 1 "true" 0 "false" ;
VAL_ 989 DiagFreeRunCntrV 1 "Invalid" 0 "Valid" ;
VAL_ 989 JmpStrtEnbld 1 "true" 0 "false" ;
VAL_ 989 MntnceMdStEngRq 1 "true" 0 "false" ;
VAL_ 989 ThrmlRefCompSpdV 1 "Invalid" 0 "Valid" ;
VAL_ 989 RdHVCntctrCmdStat 0 "Open" 1 "Precharge" 2 "Close" ;
VAL_ 1927 DTCI_CodeSupported_787 1 "true" 0 "false" ;
VAL_ 1927 DTCI_CurrentStatus_787 1 "true" 0 "false" ;
VAL_ 1927 DTCI_DTCFaultType_787 3 "Type C" 2 "Type B" 1 "Type A" 0 "Not Supported" ;
VAL_ 1927 DTCI_DTCTriggered_787 1 "true" 0 "false" ;
VAL_ 1927 DTCI_HistStat_787 1 "true" 0 "false" ;
VAL_ 1927 DTCI_TstFldCdClrdStat_787 1 "true" 0 "false" ;
VAL_ 1927 DTCI_TstFldPwrUpSt_787 1 "true" 0 "false" ;
VAL_ 1927 DTCI_TstNPsdCdClrdSt_787 1 "true" 0 "false" ;
VAL_ 1927 DTCI_TstNPsdPwrUpSt_787 1 "true" 0 "false" ;
VAL_ 1927 DTCIUnused1_787 1 "true" 0 "false" ;
VAL_ 1927 DTCIUnused2_787 1 "true" 0 "false" ;
VAL_ 1927 DTCIUnused3_787 1 "true" 0 "false" ;
VAL_ 1927 DTCIUnused4_787 1 "true" 0 "false" ;
VAL_ 1927 DTCIUnused5_787 1 "true" 0 "false" ;
VAL_ 1927 DTCIUnused6_787 1 "true" 0 "false" ;
VAL_ 1927 DTCIUnused7_787 1 "true" 0 "false" ;
VAL_ 1927 DTCI_WrnIndRqdSt_787 1 "true" 0 "false" ;
VAL_ 1278 EHCCT_EHtrCrOutClntTmpV 1 "Invalid" 0 "Valid" ;
VAL_ 1278 EHCCT_EHtrCrInClntTmpV 1 "Invalid" 0 "Valid" ;
VAL_ 1278 EstHtrCrClntFlwrtFdbkV 1 "Invalid" 0 "Valid" ;
VAL_ 1276 CCFrBlwFnSpdFbkRatV 1 "Invalid" 0 "Valid" ;
VAL_ 1037 BrkPdLfRrCnfrmReplcmntIO 1 "true" 0 "false" ;
VAL_ 1037 BrkPdLfFrtCnfrmReplcmntIO 1 "true" 0 "false" ;
VAL_ 1037 BrkPdLfRrDstWrnIndRq 2 "Display Distance" 1 "Low" 0 "No Action" ;
VAL_ 1037 BrkPdLfFrtDstWrnIndRq 2 "Display Distance" 1 "Low" 0 "No Action" ;
VAL_ 1037 BrkPdLfRrRstAvail 1 "true" 0 "false" ;
VAL_ 1037 BrkPdLfFrtRstAvail 1 "true" 0 "false" ;
VAL_ 1037 BrkPdLfRrV 1 "Invalid" 0 "Valid" ;
VAL_ 1037 BrkPdLfFrtV 1 "Invalid" 0 "Valid" ;
VAL_ 569 CrwlModeDndRsnIndReq 4 "Reduce Speed" 3 "Shift To 4 High" 2 "Brakes Overtemp" 1 "Unavailable" 0 "No Action" ;
SIG_GROUP_ 967 PTRlyStat 1 : PRS_PTRlyFdbkCktVlt PRS_PTRlyFdbkCtVtNtIR PRS_PTRlyFdbkCktFAct PRS_PTRlyCntrlCktFAct PRS_PTRlyCmdSt;
SIG_GROUP_ 398 CrksftTrqStbStat 1 : CTSS_StbltyLvl CTSS_StbltyTyp;
SIG_GROUP_ 1906 DTCInfo_772 1 : DTCI_DTCFaultType_772 DTCI_CodeSupported_772 DTCI_CurrentStatus_772 DTCI_TstNPsdCdClrdSt_772 DTCI_TstFldCdClrdStat_772 DTCI_HistStat_772 DTCI_TstNPsdPwrUpSt_772 DTCI_TstFldPwrUpSt_772 DTCI_WrnIndRqdSt_772 DTCI_DTCFailType_772 DTCI_DTCNumber_772 DTCI_DTCSource_772 DTCI_DTCTriggered_772 DTCIUnused7_772 DTCIUnused6_772 DTCIUnused5_772 DTCIUnused4_772 DTCIUnused3_772 DTCIUnused2_772 DTCIUnused1_772;
SIG_GROUP_ 872 ElcShftBrkgRq 1 : ESBR_AutoBrkgRqTyp ESBR_AutoBrkgRqd;
SIG_GROUP_ 1034 CurvRghtLine 1 : CRL_Cnfdnc CRL_ViewRng CRL_CoefdA CRL_CoefA;
SIG_GROUP_ 1033 CurvLftLine 1 : CLL_Cnfdnc CLL_ViewRng CLL_CoefdA CLL_CoefA;
SIG_GROUP_ 1013 TrnsRngDiagLmtdFlt 1 : TRDLF_TrnsFwDrvRDLFlt TRDLF_TrnsNtRgDgLtFlt TRDLF_TrnsRvRgDgLtFlt TRDLF_TrnsPkRgDgLtFlt;
SIG_GROUP_ 1013 TransRngDiagCrtFlt 1 : TRDCF_TrnsFwDrvRDCFlt TRDCF_TrnsNtRgDgCtFlt TRDCF_TrnsRvRgDgCtFlt TRDCF_TrnsPkRgDgCtFlt;
SIG_GROUP_ 199 TransOutputRotStat 1 : TORSTimestamp TORSPulsCntr TORSValidity TORSRstOcrd TORSLstTransType TORSRotDir;
SIG_GROUP_ 190 PTSnsdBrkPdlInf 1 : PSBPI_PTSnBrkPdlPsV PSBPI_PTSnBrkPdlPs;
SIG_GROUP_ 707 ChsSysTtlAxleTrqRqSt 1 : CSTATRS_ReqStat CSTATRS_LmtgStat;
SIG_GROUP_ 1273 BrkSysCtl1EmnsRelDTC 1 : BSC1ERDTC_CdNum BSC1ERDTC_SysDes;
SIG_GROUP_ 753 ElecBrkCntlMdlDiagSt5 1 : EBCMDS5_DTCStatus EBCMDS5_DTCIndex;
SIG_GROUP_ 753 ElecBrkCntlMdlDiagSt4 1 : EBCMDS4_DTCStatus EBCMDS4_DTCIndex;
SIG_GROUP_ 753 ElecBrkCntlMdlDiagSt3 1 : EBCMDS3_DTCStatus EBCMDS3_DTCIndex;
SIG_GROUP_ 753 ElecBrkCntlMdlDiagSt2 1 : EBCMDS2_DTCStatus EBCMDS2_DTCIndex;
SIG_GROUP_ 753 ElecBrkCntlMdlDiagSt1 1 : EBCMDS1_DTCStatus EBCMDS1_DTCIndex;
SIG_GROUP_ 508 ChsSysTtlBrkAxleTrqSt 1 : CSTBATS_TrqVl CSTBATS_TrqVlV;
SIG_GROUP_ 454 ChsSysPrdAxlTqRq 1 : CSPATR_TrqIntrvnTyp CSPATR_PrdTrqRqVal CSPATR_TrqRqTyp;
SIG_GROUP_ 462 SecAxlTrqReq 1 : SATRCplReqVal SATRCplReqAtv;
SIG_GROUP_ 510 BrkPresSnsrUnprocData 1 : BPSUD_MsCyPrSnsSUpVal BPSUD_MsCyPrSns2UpVal BPSUD_MsCyPrSns1UpVal;
SIG_GROUP_ 1920 DTCInfo_780 1 : DTCI_CurrentStatus_780 DTCI_WrnIndRqdSt_780 DTCIUnused7_780 DTCIUnused6_780 DTCIUnused5_780 DTCIUnused4_780 DTCIUnused3_780 DTCIUnused2_780 DTCIUnused1_780 DTCI_TstNPsdPwrUpSt_780 DTCI_TstNPsdCdClrdSt_780 DTCI_TstFldPwrUpSt_780 DTCI_TstFldCdClrdStat_780 DTCI_HistStat_780 DTCI_DTCTriggered_780 DTCI_DTCSource_780 DTCI_DTCNumber_780 DTCI_DTCFaultType_780 DTCI_DTCFailType_780 DTCI_CodeSupported_780;
SIG_GROUP_ 1907 DTCInfo_773 1 : DTCI_DTCFaultType_773 DTCI_CodeSupported_773 DTCI_CurrentStatus_773 DTCI_TstNPsdCdClrdSt_773 DTCI_TstFldCdClrdStat_773 DTCI_HistStat_773 DTCI_TstNPsdPwrUpSt_773 DTCI_TstFldPwrUpSt_773 DTCI_WrnIndRqdSt_773 DTCI_DTCFailType_773 DTCI_DTCNumber_773 DTCI_DTCSource_773 DTCI_DTCTriggered_773 DTCIUnused7_773 DTCIUnused6_773 DTCIUnused5_773 DTCIUnused4_773 DTCIUnused3_773 DTCIUnused2_773 DTCIUnused1_773;
SIG_GROUP_ 455 ChsSysEngTorqReqER 1 : CSETRER_TorqReqVal CSETRER_TqIntvnTyp;
SIG_GROUP_ 975 CGMDiagStat2 1 : CGMDS2_DTCStat CGMDS2_DTCIndx;
SIG_GROUP_ 975 CGMDiagStat1 1 : CGMDS1_DTCStat CGMDS1_DTCIndx;
SIG_GROUP_ 988 Alrm6ExtRngReq 1 :;
SIG_GROUP_ 715 LnCntrngCtlCmd 1 : LCCC_Act LCCC_AccelPedLimReq;
SIG_GROUP_ 715 ACCAxlTrqCmd 1 : ACCATC_SplREngInpR ACCATC_DrvAstdGoSt ACCATC_AxlTrqRq ACCATC_ACCTyp ACCATC_ACCAct;
SIG_GROUP_ 1927 DTCInfo_787 1 : DTCI_CodeSupported_787 DTCI_CurrentStatus_787 DTCI_DTCFailType_787 DTCI_DTCFaultType_787 DTCI_DTCNumber_787 DTCI_DTCSource_787 DTCI_DTCTriggered_787 DTCI_HistStat_787 DTCI_TstFldCdClrdStat_787 DTCI_TstFldPwrUpSt_787 DTCI_TstNPsdCdClrdSt_787 DTCI_TstNPsdPwrUpSt_787 DTCIUnused1_787 DTCIUnused2_787 DTCIUnused3_787 DTCIUnused4_787 DTCIUnused5_787 DTCIUnused6_787 DTCIUnused7_787 DTCI_WrnIndRqdSt_787;
SIG_GROUP_ 1278 EstHtrCorClntTemp 1 : EHCCT_EHtrCrOutClntTmp EHCCT_EHtrCrInClntTmp EHCCT_EHtrCrOutClntTmpV EHCCT_EHtrCrInClntTmpV;
